VERSION ""

NS_ :

BS_:

BU_: ICC DVR PCL EAMP FLZCU_HCU_IC FLZCU_IC HCU_IC FLZCU_Signal_IC CGW TBOX BNCM CWC FRZCU

BO_ 1254 ICC_DK_7: 64 ICC
 SG_ ICC_WelcomeOpenSet : 1|2@0+ (1,0) [0|3] ""  FLZCU_HCU_IC,FLZCU_IC,BNCM
 SG_ ICC_WALOpenSet : 3|2@0+ (1,0) [0|3] ""  FLZCU_HCU_IC,FLZCU_IC,BNCM
 SG_ ICC_EasytrunkSet : 5|2@0+ (1,0) [0|3] ""  BNCM
 SG_ ICC_UIROpenSet : 7|2@0+ (1,0) [0|3] ""  FLZCU_HCU_IC,FLZCU_IC,BNCM
 SG_ ICC_BeanIDReq : 13|2@0+ (1,0) [0|3] ""  BNCM
 SG_ ICC_CWCWorkingStsSet : 15|2@0+ (1,0) [0|3] ""  CWC
 SG_ ICC_CWCPhoneforgottenFunStsSet : 17|2@0+ (1,0) [0|3] ""  CWC
 SG_ ICC_RCWCWorkingStsSet : 25|2@0+ (1,0) [0|3] "" Vector__XXX
 SG_ ICC_RCWCPhoneforgottenFunStsSet : 27|2@0+ (1,0) [0|3] "" Vector__XXX

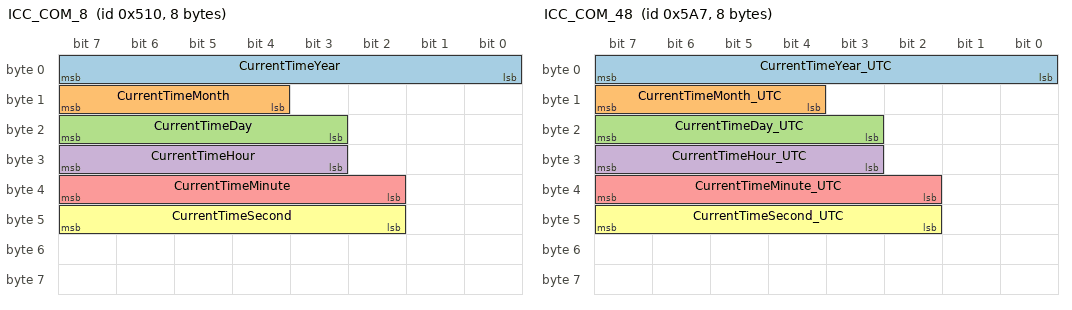
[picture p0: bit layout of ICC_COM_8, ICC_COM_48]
BO_ 1296 ICC_COM_8: 8 ICC
 SG_ CurrentTimeYear : 7|8@0+ (1,2000) [2000|2255] ""  DVR,FLZCU_HCU_IC,HCU_IC,BNCM
 SG_ CurrentTimeMonth : 15|4@0+ (1,0) [1|12] ""  DVR,FLZCU_HCU_IC,HCU_IC,BNCM
 SG_ CurrentTimeDay : 23|5@0+ (1,0) [1|31] ""  DVR,FLZCU_HCU_IC,HCU_IC,BNCM
 SG_ CurrentTimeHour : 31|5@0+ (1,0) [0|23] ""  DVR,FLZCU_HCU_IC,HCU_IC,BNCM
 SG_ CurrentTimeMinute : 39|6@0+ (1,0) [0|59] ""  DVR,FLZCU_HCU_IC,HCU_IC,BNCM
 SG_ CurrentTimeSecond : 47|6@0+ (1,0) [0|59] ""  DVR,FLZCU_HCU_IC,HCU_IC,BNCM

BO_ 1447 ICC_COM_48: 8 ICC
 SG_ CurrentTimeYear_UTC : 7|8@0+ (1,2000) [2000|2255] ""  FLZCU_HCU_IC,FLZCU_IC
 SG_ CurrentTimeMonth_UTC : 15|4@0+ (1,0) [1|12] ""  FLZCU_HCU_IC,FLZCU_IC
 SG_ CurrentTimeDay_UTC : 23|5@0+ (1,0) [1|31] ""  FLZCU_HCU_IC,FLZCU_IC
 SG_ CurrentTimeHour_UTC : 31|5@0+ (1,0) [0|23] ""  FLZCU_HCU_IC,FLZCU_IC
 SG_ CurrentTimeMinute_UTC : 39|6@0+ (1,0) [0|59] ""  FLZCU_HCU_IC,FLZCU_IC
 SG_ CurrentTimeSecond_UTC : 47|6@0+ (1,0) [0|59] ""  FLZCU_HCU_IC,FLZCU_IC

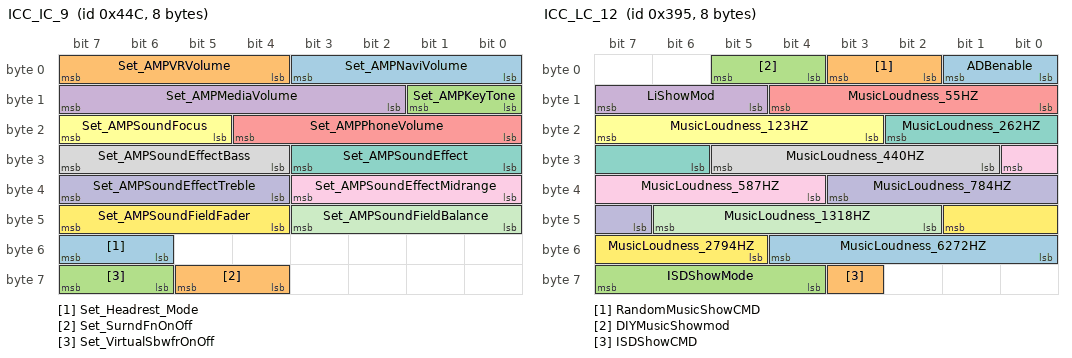
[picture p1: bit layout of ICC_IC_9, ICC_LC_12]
BO_ 1100 ICC_IC_9: 8 ICC
 SG_ Set_AMPNaviVolume : 3|4@0+ (1,0) [0|15] ""  EAMP
 SG_ Set_AMPVRVolume : 7|4@0+ (1,0) [0|15] ""  EAMP
 SG_ Set_AMPKeyTone : 9|2@0+ (1,0) [0|3] ""  EAMP
 SG_ Set_AMPMediaVolume : 15|6@0+ (1,0) [0|63] ""  EAMP
 SG_ Set_AMPPhoneVolume : 20|5@0+ (1,0) [0|31] ""  EAMP
 SG_ Set_AMPSoundFocus : 23|3@0+ (1,0) [0|7] ""  EAMP
 SG_ Set_AMPSoundEffect : 27|4@0+ (1,0) [0|15] ""  EAMP
 SG_ Set_AMPSoundEffectBass : 31|4@0+ (1,0) [0|15] ""  EAMP
 SG_ Set_AMPSoundEffectMidrange : 35|4@0+ (1,0) [0|15] ""  EAMP
 SG_ Set_AMPSoundEffectTreble : 39|4@0+ (1,0) [0|15] ""  EAMP
 SG_ Set_AMPSoundFieldBalance : 43|4@0+ (1,0) [0|15] ""  EAMP
 SG_ Set_AMPSoundFieldFader : 47|4@0+ (1,0) [0|15] ""  EAMP
 SG_ Set_Headrest_Mode : 55|2@0+ (1,0) [0|3] ""  EAMP
 SG_ Set_SurndFnOnOff : 61|2@0+ (1,0) [0|3] ""  EAMP
 SG_ Set_VirtualSbwfrOnOff : 63|2@0+ (1,0) [0|1] ""  EAMP

BO_ 1119 ICC_IC_10: 8 ICC
 SG_ Set_AMPMediaDuck : 1|2@0+ (1,0) [0|3] ""  EAMP
 SG_ Set_AMPSpeedVolume : 5|3@0+ (1,0) [0|7] ""  EAMP
 SG_ Set_AMPMute : 7|2@0+ (1,0) [0|3] ""  EAMP
 SG_ REQ_AMPA2BMediaSound : 9|2@0+ (1,0) [0|3] ""  EAMP
 SG_ REQ_AMPA2BNaviSound : 11|2@0+ (1,0) [0|3] ""  EAMP
 SG_ REQ_AMPA2BVRSound : 13|2@0+ (1,0) [0|3] ""  EAMP
 SG_ REQ_AMPA2BTTSSound : 15|2@0+ (1,0) [0|3] ""  EAMP
 SG_ REQ_AMPA2BKeyTone : 23|2@0+ (1,0) [0|3] ""  EAMP
 SG_ Set_AMPRestoreDefaults : 25|2@0+ (1,0) [0|3] ""  EAMP
 SG_ Set_AMPAlarmVolume : 29|4@0+ (1,0) [0|15] ""  EAMP
 SG_ REQ_AMPA2BPhoneSound : 31|2@0+ (1,0) [0|3] ""  EAMP
 SG_ Set_AMPSoundEffectMegaBass : 35|4@0+ (1,0) [0|15] ""  EAMP
 SG_ Set_AMPSoundEffectMidBass : 39|4@0+ (1,0) [0|15] ""  EAMP
 SG_ Set_AMPSoundEffectMidTreble : 43|4@0+ (1,0) [0|15] ""  EAMP
 SG_ Set_AMPBackgroundVolume : 53|6@0+ (1,0) [0|63] ""  EAMP
 SG_ Set_AMPSoundBypass : 45|2@0+ (1,0) [0|3] ""  EAMP
 SG_ Set_AMPA2BConfig : 47|2@0+ (1,0) [0|3] ""  EAMP

BO_ 1150 ICC_BD_11: 8 ICC
 SG_ Fusa_47E_3 : 28|1@0+ (1,0) [0|1] "" Vector__XXX
 SG_ Fusa_47E_2 : 23|4@0+ (1,0) [0|15] "" Vector__XXX
 SG_ Fusa_47E_1 : 15|2@0+ (1,0) [0|3] "" Vector__XXX
 SG_ ICC_BD_11_CRC : 7|8@0+ (1,0) [0|255] "" Vector__XXX
 SG_ ICC_BD_11_RollgCntr : 11|4@0+ (1,0) [0|14] "" Vector__XXX
 SG_ ICC_CPDDelaySwitchSet : 13|2@0+ (1,0) [0|3] "" Vector__XXX
 SG_ ICC_PPMIDBSRBPASet : 17|2@0+ (1,0) [0|3] "" Vector__XXX
 SG_ ICC_PPMIDHwSet : 19|2@0+ (1,0) [0|3] "" Vector__XXX
 SG_ ICC_DriveDrosinessLevel : 31|3@0+ (1,0) [0|7] "" Vector__XXX
 SG_ ICC_FLDoorButton : 25|2@0+ (1,0) [0|3] "" Vector__XXX
 SG_ ICC_FRDoorButton : 27|2@0+ (1,0) [0|3] "" Vector__XXX
 SG_ ICC_RRDoorButton : 33|2@0+ (1,0) [0|3] "" Vector__XXX
 SG_ ICC_RLDoorButton : 35|2@0+ (1,0) [0|3] "" Vector__XXX
 SG_ ICC_CloseAllDoors : 37|2@0+ (1,0) [0|3] "" Vector__XXX
 SG_ ICC_DoorRemoteKeyControlEnable : 39|2@0+ (1,0) [0|3] ""  FLZCU_HCU_IC
 SG_ ICC_SetOpenAngle : 41|2@0+ (1,0) [0|3] "" Vector__XXX
 SG_ ICC_CPDSwitchSet : 43|2@0+ (1,0) [0|3] "" Vector__XXX
 SG_ ICC_FrontDoorPowerMode : 45|2@0+ (1,0) [0|3] "" Vector__XXX
 SG_ ICC_RearDoorPowerMode : 47|2@0+ (1,0) [0|3] "" Vector__XXX
 SG_ ICC_PedalCloseDriverDoorEnable : 49|2@0+ (1,0) [0|3] "" Vector__XXX
 SG_ RR_Door_RearScreen_Control : 51|2@0+ (1,0) [0|3] "" Vector__XXX
 SG_ ICC_RearDoorVoiceControlEnable : 53|2@0+ (1,0) [0|3] "" Vector__XXX
 SG_ ICC_FLVoiceControl : 55|2@0+ (1,0) [0|3] "" Vector__XXX
 SG_ ICC_FRVoiceControl : 57|2@0+ (1,0) [0|3] "" Vector__XXX
 SG_ ICC_RRVoiceControl : 59|2@0+ (1,0) [0|3] "" Vector__XXX
 SG_ ICC_RLVoiceControl : 61|2@0+ (1,0) [0|3] "" Vector__XXX
 SG_ RL_Door_RearScreen_Control : 63|2@0+ (1,0) [0|3] "" Vector__XXX

BO_ 917 ICC_LC_12: 8 ICC
 SG_ ADBenable : 1|2@0+ (1,0) [0|3] "" Vector__XXX
 SG_ RandomMusicShowCMD : 3|2@0+ (1,0) [0|3] "" Vector__XXX
 SG_ DIYMusicShowmod : 5|2@0+ (1,0) [0|3] "" Vector__XXX
 SG_ LiShowMod : 15|3@0+ (1,0) [0|7] "" Vector__XXX
 SG_ MusicLoudness_55HZ : 12|5@0+ (1,0) [0|31] "" Vector__XXX
 SG_ MusicLoudness_123HZ : 23|5@0+ (1,0) [0|31] "" Vector__XXX
 SG_ MusicLoudness_262HZ : 18|5@0+ (1,0) [0|31] "" Vector__XXX
 SG_ MusicLoudness_440HZ : 29|5@0+ (1,0) [0|31] "" Vector__XXX
 SG_ MusicLoudness_587HZ : 24|5@0+ (1,0) [0|31] "" Vector__XXX
 SG_ MusicLoudness_784HZ : 35|5@0+ (1,0) [0|31] "" Vector__XXX
 SG_ MusicLoudness_1318HZ : 46|5@0+ (1,0) [0|31] "" Vector__XXX
 SG_ MusicLoudness_2794HZ : 41|5@0+ (1,0) [0|31] "" Vector__XXX
 SG_ MusicLoudness_6272HZ : 52|5@0+ (1,0) [0|31] "" Vector__XXX
 SG_ ISDShowCMD : 59|1@0+ (1,0) [0|1] "" Vector__XXX
 SG_ ISDShowMode : 63|4@0+ (1,0) [0|15] "" Vector__XXX

BO_ 1273 ICC_IC_14: 8 ICC
 SG_ FaceID : 29|3@0+ (1,0) [0|7] ""  FLZCU_HCU_IC,FLZCU_IC

BO_ 1157 ICC_DA_15: 8 ICC
 SG_ Fusa_485_2 : 55|16@0+ (1,0) [0|65535] "" Vector__XXX
 SG_ Fusa_485_1 : 31|3@0+ (1,0) [0|7] "" Vector__XXX
 SG_ ICC_DA_15_CRC : 7|8@0+ (1,0) [0|255] "" Vector__XXX
 SG_ ICC_DA_15_RollgCntr : 11|4@0+ (1,0) [0|14] "" Vector__XXX
 SG_ ICC_DA_15_Resd : 15|4@0+ (1,0) [0|15] "" Vector__XXX
 SG_ ICC_DA_15_BSDLCWSettingSt : 17|2@0+ (1,0) [0|3] "" Vector__XXX
 SG_ ICC_DA_15_DOWSettingSt : 19|2@0+ (1,0) [0|3] "" Vector__XXX
 SG_ ICC_DA_15_RCWSettingSt : 21|2@0+ (1,0) [0|3] "" Vector__XXX
 SG_ ICC_DA_15_RCTARCTBWarnType : 23|2@0+ (1,0) [0|3] "" Vector__XXX
 SG_ ICC_DA_15_FCTAFCTBWarnType : 25|2@0+ (1,0) [0|3] "" Vector__XXX
 SG_ ICC_DA_15_FrontPDCMuteSet : 26|1@0+ (1,0) [0|1] "" Vector__XXX
 SG_ ICC_DA_15_FKPMuteSet : 27|1@0+ (1,0) [0|1] "" Vector__XXX
 SG_ ICC_DA_15_ExtremeEnergySaveMode : 28|1@0+ (1,0) [0|1] "" Vector__XXX
 SG_ Driver_EyeOnRoad : 39|3@0+ (1,0) [0|7] "" Vector__XXX
 SG_ Dms_Status : 36|3@0+ (1,0) [0|7] "" Vector__XXX
 SG_ Driver_AbnormalBehavior : 33|2@0+ (1,0) [0|3] "" Vector__XXX
 SG_ Driver_GazeRegion : 47|4@0+ (1,0) [0|15] "" Vector__XXX
 SG_ Dms_DriverPresence : 43|2@0+ (1,0) [0|3] "" Vector__XXX
 SG_ ICC_IHCfunctionSw : 41|2@0+ (1,0) [0|3] "" Vector__XXX

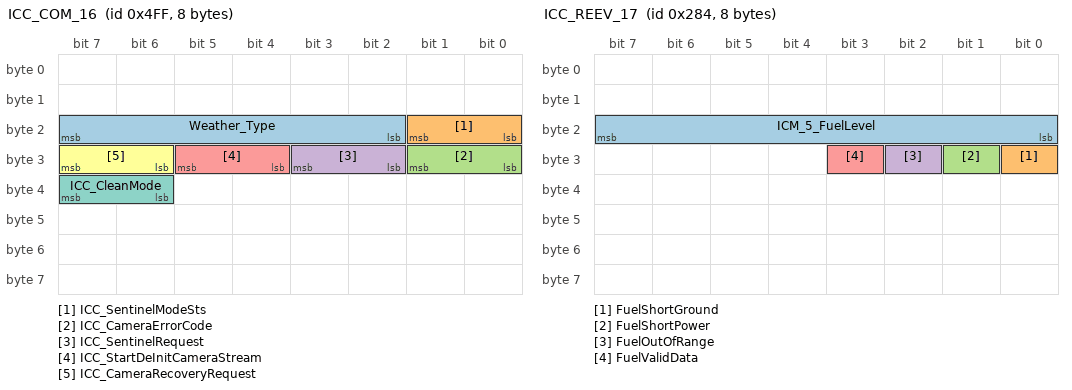
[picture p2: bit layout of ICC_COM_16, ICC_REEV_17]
BO_ 1279 ICC_COM_16: 8 ICC
 SG_ Weather_Type : 23|6@0+ (1,0) [0|63] "" Vector__XXX
 SG_ ICC_SentinelModeSts : 17|2@0+ (1,0) [0|3] "" Vector__XXX
 SG_ ICC_CameraErrorCode : 25|2@0+ (1,0) [0|3] "" Vector__XXX
 SG_ ICC_SentinelRequest : 27|2@0+ (1,0) [0|3] "" Vector__XXX
 SG_ ICC_StartDeInitCameraStream : 29|2@0+ (1,0) [0|3] "" Vector__XXX
 SG_ ICC_CameraRecoveryRequest : 31|2@0+ (1,0) [0|3] "" Vector__XXX
 SG_ ICC_CleanMode : 39|2@0+ (1,0) [0|3] "" Vector__XXX

BO_ 644 ICC_REEV_17: 8 ICC
 SG_ ICM_5_FuelLevel : 23|8@0+ (1,0) [0|100] "%"  FLZCU_HCU_IC,HCU_IC,TBOX
 SG_ FuelShortGround : 24|1@0+ (1,0) [0|1] ""  FLZCU_HCU_IC
 SG_ FuelShortPower : 25|1@0+ (1,0) [0|1] ""  FLZCU_HCU_IC
 SG_ FuelOutOfRange : 26|1@0+ (1,0) [0|1] ""  FLZCU_HCU_IC
 SG_ FuelValidData : 27|1@0+ (1,0) [0|1] ""  FLZCU_HCU_IC

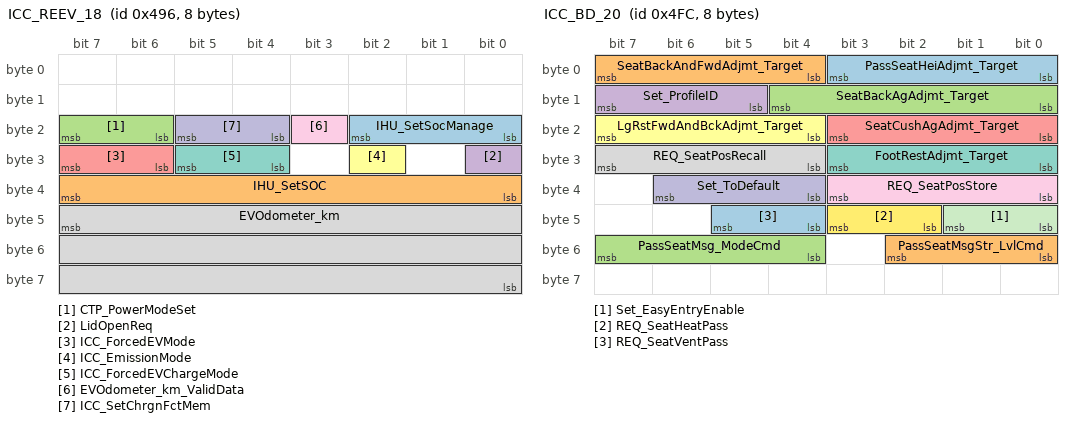
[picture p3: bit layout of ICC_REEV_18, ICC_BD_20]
BO_ 1174 ICC_REEV_18: 8 ICC
 SG_ IHU_SetSocManage : 18|3@0+ (1,0) [0|7] ""  FLZCU_HCU_IC
 SG_ IHU_SetSOC : 39|8@0+ (1,0) [0|100] "%"  FLZCU_HCU_IC,HCU_IC
 SG_ CTP_PowerModeSet : 23|2@0+ (1,0) [0|3] ""  FLZCU_HCU_IC,HCU_IC
 SG_ LidOpenReq : 24|1@0+ (1,0) [0|1] "" Vector__XXX
 SG_ ICC_ForcedEVMode : 31|2@0+ (1,0) [0|3] ""  FLZCU_HCU_IC
 SG_ ICC_EmissionMode : 26|1@0+ (1,0) [0|1] ""  FLZCU_HCU_IC,HCU_IC
 SG_ ICC_ForcedEVChargeMode : 29|2@0+ (1,0) [0|3] ""  FLZCU_HCU_IC
 SG_ EVOdometer_km : 47|24@0+ (0.1,0) [0|999999.9] "km"  FLZCU_HCU_IC
 SG_ EVOdometer_km_ValidData : 19|1@0+ (1,0) [0|1] ""  FLZCU_HCU_IC
 SG_ ICC_SetChrgnFctMem : 21|2@0+ (1,0) [0|3] ""  FLZCU_HCU_IC,HCU_IC

BO_ 1242 ICC_DK_19: 32 ICC
 SG_ ICC_DK_19_CRC1 : 7|8@0+ (1,0) [0|255] ""  BNCM
 SG_ ICC_DK_19_RollgCntr1 : 11|4@0+ (1,0) [0|14] ""  BNCM
 SG_ ICC_DK_19_Resd1 : 15|4@0+ (1,0) [0|15] ""  BNCM
 SG_ ICC_DK_19_CMD : 23|16@0+ (1,0) [0|65535] ""  BNCM
 SG_ ICC_DK_19_PDU1 : 39|64@0+ (1,0) [0|1.84467440737096E+019] ""  BNCM
 SG_ ICC_DK_19_PDU2 : 103|64@0+ (1,0) [0|1.84467440737096E+019] ""  BNCM
 SG_ ICC_DK_19_PDU3 : 167|64@0+ (1,0) [0|1.84467440737096E+019] ""  BNCM
 SG_ ICC_DK_19_PDU4 : 231|32@0+ (1,0) [0|4294967295] ""  BNCM

BO_ 1276 ICC_BD_20: 8 ICC
 SG_ PassSeatHeiAdjmt_Target : 3|4@0+ (1,0) [0|15] "" Vector__XXX
 SG_ SeatBackAndFwdAdjmt_Target : 7|4@0+ (1,0) [0|15] "" Vector__XXX
 SG_ SeatBackAgAdjmt_Target : 12|5@0+ (1,0) [0|31] "" Vector__XXX
 SG_ Set_ProfileID : 15|3@0+ (1,0) [0|7] "" Vector__XXX
 SG_ SeatCushAgAdjmt_Target : 19|4@0+ (1,0) [0|15] "" Vector__XXX
 SG_ LgRstFwdAndBckAdjmt_Target : 23|4@0+ (1,0) [0|15] "" Vector__XXX
 SG_ FootRestAdjmt_Target : 27|4@0+ (1,0) [0|15] "" Vector__XXX
 SG_ REQ_SeatPosRecall : 31|4@0+ (1,0) [0|15] "" Vector__XXX
 SG_ REQ_SeatPosStore : 35|4@0+ (1,0) [0|15] "" Vector__XXX
 SG_ Set_ToDefault : 38|3@0+ (1,0) [0|7] "" Vector__XXX
 SG_ Set_EasyEntryEnable : 41|2@0+ (1,0) [0|3] "" Vector__XXX
 SG_ REQ_SeatHeatPass : 43|2@0+ (1,0) [0|3] "" Vector__XXX
 SG_ REQ_SeatVentPass : 45|2@0+ (1,0) [0|3] "" Vector__XXX
 SG_ PassSeatMsgStr_LvlCmd : 50|3@0+ (1,0) [0|7] "" Vector__XXX
 SG_ PassSeatMsg_ModeCmd : 55|4@0+ (1,0) [0|15] "" Vector__XXX

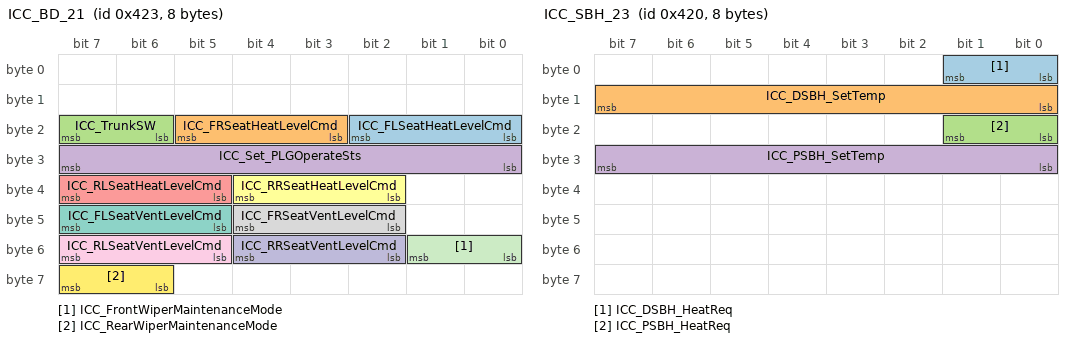
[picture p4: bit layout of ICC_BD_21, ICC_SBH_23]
BO_ 1059 ICC_BD_21: 8 ICC
 SG_ ICC_FLSeatHeatLevelCmd : 18|3@0+ (1,0) [0|7] ""  FLZCU_HCU_IC,FLZCU_IC
 SG_ ICC_FRSeatHeatLevelCmd : 21|3@0+ (1,0) [0|7] ""  FRZCU
 SG_ ICC_TrunkSW : 23|2@0+ (1,0) [0|3] "" Vector__XXX
 SG_ ICC_Set_PLGOperateSts : 31|8@0+ (1,-1) [-1|100] "%" Vector__XXX
 SG_ ICC_RLSeatHeatLevelCmd : 39|3@0+ (1,0) [0|7] ""  FLZCU_HCU_IC,FLZCU_IC
 SG_ ICC_RRSeatHeatLevelCmd : 36|3@0+ (1,0) [0|7] ""  FRZCU
 SG_ ICC_FLSeatVentLevelCmd : 47|3@0+ (1,0) [0|7] ""  FLZCU_HCU_IC,FLZCU_IC
 SG_ ICC_FRSeatVentLevelCmd : 44|3@0+ (1,0) [0|7] ""  FRZCU
 SG_ ICC_RLSeatVentLevelCmd : 55|3@0+ (1,0) [0|7] ""  FLZCU_HCU_IC,FLZCU_IC
 SG_ ICC_RRSeatVentLevelCmd : 52|3@0+ (1,0) [0|7] ""  FRZCU
 SG_ ICC_FrontWiperMaintenanceMode : 49|2@0+ (1,0) [0|3] ""  FLZCU_HCU_IC,FLZCU_IC
 SG_ ICC_RearWiperMaintenanceMode : 63|2@0+ (1,0) [0|3] ""  FLZCU_HCU_IC,FLZCU_IC

BO_ 1105 ICC_MFS_22: 8 ICC
 SG_ ICC_MultiplexSignalStatusSet : 12|3@0+ (1,0) [0|7] "" Vector__XXX

BO_ 1056 ICC_SBH_23: 8 ICC
 SG_ ICC_DSBH_HeatReq : 1|2@0+ (1,0) [0|3] "" Vector__XXX
 SG_ ICC_DSBH_SetTemp : 15|8@0+ (1,0) [30|65] "°C" Vector__XXX
 SG_ ICC_PSBH_HeatReq : 17|2@0+ (1,0) [0|3] "" Vector__XXX
 SG_ ICC_PSBH_SetTemp : 31|8@0+ (1,0) [30|65] "°C" Vector__XXX

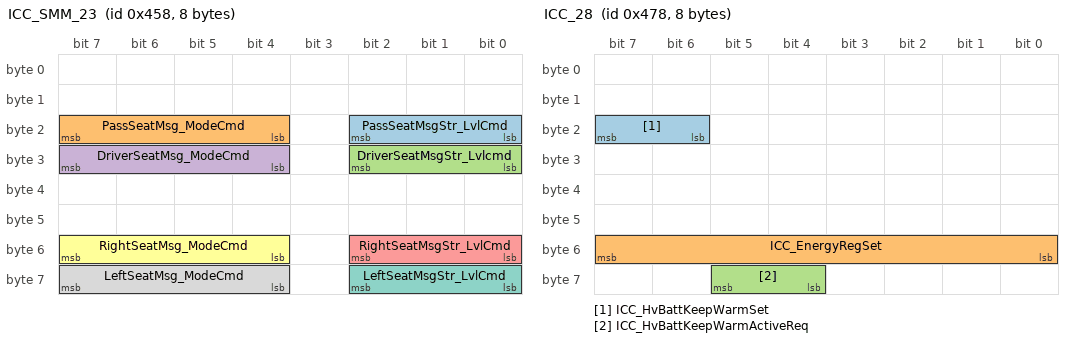
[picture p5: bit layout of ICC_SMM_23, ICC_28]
BO_ 1112 ICC_SMM_23: 8 ICC
 SG_ PassSeatMsgStr_LvlCmd : 18|3@0+ (1,0) [0|7] ""  FLZCU_HCU_IC,FLZCU_IC
 SG_ PassSeatMsg_ModeCmd : 23|4@0+ (1,0) [0|15] ""  FLZCU_HCU_IC,FLZCU_IC
 SG_ DriverSeatMsgStr_Lvlcmd : 26|3@0+ (1,0) [0|7] ""  FLZCU_HCU_IC,FLZCU_IC
 SG_ DriverSeatMsg_ModeCmd : 31|4@0+ (1,0) [0|15] ""  FLZCU_HCU_IC,FLZCU_IC
 SG_ RightSeatMsgStr_LvlCmd : 50|3@0+ (1,0) [0|7] ""  FLZCU_HCU_IC,FLZCU_IC
 SG_ RightSeatMsg_ModeCmd : 55|4@0+ (1,0) [0|15] ""  FLZCU_HCU_IC,FLZCU_IC
 SG_ LeftSeatMsgStr_LvlCmd : 58|3@0+ (1,0) [0|7] ""  FLZCU_HCU_IC,FLZCU_IC
 SG_ LeftSeatMsg_ModeCmd : 63|4@0+ (1,0) [0|15] ""  FLZCU_HCU_IC,FLZCU_IC

BO_ 1265 ICC_ZCU_25: 24 ICC
 SG_ ICC_PwrOff : 18|1@0+ (1,0) [0|1] ""  FLZCU_HCU_IC
 SG_ ICC_EtmEgySave : 20|1@0+ (1,0) [0|1] ""  FLZCU_HCU_IC
 SG_ ICC_HoodSW : 23|2@0+ (1,0) [0|3] ""  FLZCU_HCU_IC
 SG_ ICC_GloveboxSW : 25|2@0+ (1,0) [0|3] ""  FLZCU_HCU_IC
 SG_ ICC_ChrgPortCover_Switch : 27|2@0+ (1,0) [0|3] ""  FLZCU_HCU_IC
 SG_ ICC_ReWinDefrstSwt : 29|2@0+ (1,0) [0|3] ""  FLZCU_HCU_IC,FLZCU_IC
 SG_ ICC_RearMirrorFoldCmd : 31|2@0+ (1,0) [0|3] ""  FLZCU_HCU_IC,FLZCU_IC
 SG_ ICC_CenterLockSwt : 33|2@0+ (1,0) [0|3] ""  FLZCU_HCU_IC,FLZCU_IC
 SG_ ICC_ReverseExtMirrorSts : 36|3@0+ (1,0) [0|7] ""  FLZCU_HCU_IC,FLZCU_IC
 SG_ ICC_LightMainSwitchSts : 39|3@0+ (1,0) [0|7] ""  FLZCU_HCU_IC
 SG_ ICC_AutoFoldSts : 41|2@0+ (1,0) [0|3] ""  FLZCU_HCU_IC,FLZCU_IC
 SG_ ICC_HeadlampHeightSts : 44|3@0+ (1,0) [0|7] ""  FLZCU_HCU_IC,FLZCU_IC
 SG_ ICC_WiprSnvty : 47|3@0+ (1,0) [0|7] ""  FLZCU_HCU_IC,FLZCU_IC
 SG_ ICC_WindowCmd : 52|5@0+ (1,0) [0|31] ""  FLZCU_HCU_IC,FLZCU_IC
 SG_ ICC_LowBeamDelayOff : 55|3@0+ (1,0) [0|7] ""  FLZCU_HCU_IC,FLZCU_IC
 SG_ ICC_FLWinCmd : 62|7@0+ (1,-1) [-1|100] "%"  FLZCU_HCU_IC,FLZCU_IC
 SG_ ICC_FRWinCmd : 86|7@0+ (1,-1) [-1|100] "%"  FLZCU_HCU_IC,FLZCU_IC
 SG_ ICC_RLWinCmd : 94|7@0+ (1,-1) [-1|100] "%"  FLZCU_HCU_IC,FLZCU_IC
 SG_ ICC_RRWinCmd : 102|7@0+ (1,-1) [-1|100] "%"  FLZCU_HCU_IC,FLZCU_IC
 SG_ ICC_FGHeatSts : 105|2@0+ (1,0) [0|3] ""  FLZCU_HCU_IC,FLZCU_IC
 SG_ ICC_AutolockSts : 107|2@0+ (1,0) [0|3] ""  FLZCU_HCU_IC,FLZCU_IC
 SG_ ICC_WiperID : 109|2@0+ (1,0) [0|3] ""  FLZCU_HCU_IC
 SG_ ICC_MaintenanceMode : 111|2@0+ (1,0) [0|3] ""  FLZCU_HCU_IC
 SG_ ICC_lockSetSwitchSts : 113|2@0+ (1,0) [0|3] ""  FLZCU_HCU_IC
 SG_ ICC_ChildLockSW : 115|2@0+ (1,0) [0|3] ""  FLZCU_HCU_IC
 SG_ ICC_ParkUnlockEnable : 117|2@0+ (1,0) [0|3] ""  FLZCU_HCU_IC,FLZCU_IC
 SG_ ICC_BLEOpenDriverDoorEnable : 119|2@0+ (1,0) [0|3] ""  FLZCU_HCU_IC,FLZCU_IC
 SG_ ICC_WinInhbSwt : 121|2@0+ (1,0) [0|3] ""  FLZCU_HCU_IC
 SG_ ICC_SteerWhlHeatgSwt : 124|3@0+ (1,0) [0|7] ""  FLZCU_HCU_IC,FLZCU_IC
 SG_ ICC_AutoHeatingset : 127|2@0+ (1,0) [0|3] ""  FLZCU_HCU_IC
 SG_ ICC_FrontFogSw : 145|2@0+ (1,0) [0|3] ""  FLZCU_HCU_IC
 SG_ ICC_RearFogSw : 147|2@0+ (1,0) [0|3] ""  FLZCU_HCU_IC
 SG_ ICC_DoorControlSW : 149|2@0+ (1,0) [0|3] ""  FLZCU_HCU_IC
 SG_ ICC_LockCarWinCloseSw : 151|2@0+ (1,0) [0|3] ""  FLZCU_HCU_IC,FLZCU_IC
 SG_ ICC_RainCarWinCloseSw : 159|2@0+ (1,0) [0|3] ""  FLZCU_HCU_IC
 SG_ ICC_EasyEntryExitSet : 157|2@0+ (1,0) [0|3] ""  FLZCU_HCU_IC,FLZCU_IC
 SG_ ICC_NapTimeSet : 166|6@0+ (1,-1) [-1|60] "min"  FLZCU_HCU_IC,FLZCU_IC
 SG_ ICC_NapAreaSet : 155|2@0+ (1,0) [0|3] ""  FLZCU_HCU_IC,FLZCU_IC
 SG_ ICC_NapStatusSet : 153|2@0+ (1,0) [0|3] ""  FLZCU_HCU_IC,FLZCU_IC
 SG_ ICC_NapCFSStatusSet : 175|2@0+ (1,0) [0|3] ""  FLZCU_HCU_IC,FRZCU
 SG_ ICC_NapSetTemperature : 173|5@0+ (0.5,15.5) [15.5|30.5] "℃"  FLZCU_HCU_IC,FRZCU
 SG_ ICC_SpoilerWelcomeFunSet : 183|2@0+ (1,0) [0|3] ""  FLZCU_HCU_IC
 SG_ ICC_SpoilerCtrlCmd : 181|3@0+ (1,0) [0|7] ""  FLZCU_HCU_IC
 SG_ ICC_HazardLightReq : 177|2@0+ (1,0) [0|3] ""  FLZCU_HCU_IC
 SG_ ICC_MusicStatus : 187|2@0+ (1,0) [0|3] ""  FLZCU_HCU_IC,FLZCU_IC
 SG_ ICC_CinemaStatus : 185|2@0+ (1,0) [0|3] ""  PCL,FLZCU_HCU_IC,FLZCU_IC,HCU_IC

BO_ 1137 ICC_TBOX_27: 32 ICC
 SG_ ICC_BookChrgSetReq : 23|2@0+ (1,0) [0|3] ""  FLZCU_HCU_IC,HCU_IC,TBOX
 SG_ ICC_BkChrgStartTimeYear : 31|16@0+ (1,1900) [1900|9999] "年"  FLZCU_HCU_IC,HCU_IC,TBOX
 SG_ ICC_BkChrgStartTimeDay : 47|5@0+ (1,0) [1|31] "日"  FLZCU_HCU_IC,HCU_IC,TBOX
 SG_ ICC_BkChrgStartTimeHour : 55|5@0+ (1,0) [0|23] "小时"  FLZCU_HCU_IC,HCU_IC,TBOX
 SG_ ICC_BkChrgStartTimemMin : 63|6@0+ (1,0) [0|59] "分钟"  FLZCU_HCU_IC,HCU_IC,TBOX
 SG_ ICC_BkChrgStartTimeMonth : 87|4@0+ (1,0) [1|12] "月"  FLZCU_HCU_IC,HCU_IC,TBOX
 SG_ ICC_BkChrgDuration : 83|11@0+ (1,0) [0|1440] "min"  FLZCU_HCU_IC,HCU_IC,TBOX
 SG_ ICC_BkChrgCycleType : 103|3@0+ (1,0) [0|7] ""  FLZCU_HCU_IC,HCU_IC,TBOX
 SG_ ICC_StopChrgReq : 100|2@0+ (1,0) [0|3] ""  FLZCU_HCU_IC,HCU_IC,TBOX
 SG_ ICC_BkChrgCycleMon : 98|2@0+ (1,0) [0|3] ""  FLZCU_HCU_IC,HCU_IC,TBOX
 SG_ ICC_BkChrgCycleTues : 111|2@0+ (1,0) [0|3] ""  FLZCU_HCU_IC,HCU_IC,TBOX
 SG_ ICC_BkChrgCycleWen : 109|2@0+ (1,0) [0|3] ""  FLZCU_HCU_IC,HCU_IC,TBOX
 SG_ ICC_BkChrgCycleThur : 107|2@0+ (1,0) [0|3] ""  FLZCU_HCU_IC,HCU_IC,TBOX
 SG_ ICC_BkChrgCycleFri : 105|2@0+ (1,0) [0|3] ""  FLZCU_HCU_IC,HCU_IC,TBOX
 SG_ ICC_BkChrgCycleSat : 119|2@0+ (1,0) [0|3] ""  FLZCU_HCU_IC,HCU_IC,TBOX
 SG_ ICC_BkChrgCycleSun : 117|2@0+ (1,0) [0|3] ""  FLZCU_HCU_IC,HCU_IC,TBOX
 SG_ ICC_KeepWarmStrt : 124|5@0+ (1,0) [1|31] "日"  FLZCU_HCU_IC,HCU_IC,TBOX
 SG_ ICC_KeepWarmStrtHour : 148|5@0+ (1,0) [0|23] "小时"  FLZCU_HCU_IC,HCU_IC,TBOX
 SG_ ICC_KeepWarmStrtMin : 157|6@0+ (1,0) [0|59] "分钟"  FLZCU_HCU_IC,HCU_IC,TBOX
 SG_ ICC_PetmodeFb : 159|2@0+ (1,0) [0|3] ""  FLZCU_HCU_IC,HCU_IC,TBOX
 SG_ ICC_SentinelModeSwitchSts : 167|2@0+ (1,0) [0|3] ""  FLZCU_HCU_IC,HCU_IC,TBOX
 SG_ ICC_SentinelModeWorkingSts : 165|3@0+ (1,0) [0|7] ""  FLZCU_HCU_IC,HCU_IC,TBOX
 SG_ ICC_SentinelModeFaultSts : 161|2@0+ (1,0) [0|3] ""  FLZCU_HCU_IC,HCU_IC,TBOX
 SG_ ICC_SentinelModeAlarmSts : 175|2@0+ (1,0) [0|3] ""  FLZCU_HCU_IC,HCU_IC,TBOX
 SG_ ICC_SentinelModeExitReason : 173|3@0+ (1,0) [0|7] ""  FLZCU_HCU_IC,HCU_IC,TBOX
 SG_ ICC_PetModeWarn : 170|3@0+ (1,0) [0|7] ""  FLZCU_HCU_IC
 SG_ ICC_TBOXPetmodeReq : 178|2@0+ (1,0) [0|3] ""  FLZCU_HCU_IC,TBOX
 SG_ ICC_PetModeWarn_2 : 183|5@0+ (1,0) [0|31] ""  FLZCU_HCU_IC,HCU_IC,TBOX
 SG_ ICM_FuelLevel : 215|8@0+ (1,0) [0|255] "L"  FLZCU_HCU_IC,HCU_IC,TBOX,BNCM
 SG_ ICM_AverageVehicleSpeed : 223|8@0+ (1,0) [0|255] "Km/h"  FLZCU_HCU_IC,HCU_IC,TBOX
 SG_ ICM_DistenceToEmpty_Km : 231|11@0+ (1,0) [0|2047] "km"  FLZCU_HCU_IC,HCU_IC,TBOX
 SG_ ICM_FuelLevelFailSts : 235|1@0+ (1,0) [0|1] ""  FLZCU_HCU_IC,HCU_IC,TBOX
 SG_ ICM_Maintenance_tips : 234|1@0+ (1,0) [0|1] ""  FLZCU_HCU_IC,HCU_IC,TBOX
 SG_ ICM_SumTrip : 247|14@0+ (1,0) [0|16383] "km"  FLZCU_HCU_IC,HCU_IC,TBOX

BO_ 1144 ICC_28: 8 ICC
 SG_ ICC_HvBattKeepWarmSet : 23|2@0+ (1,0) [0|3] ""  FLZCU_HCU_IC,HCU_IC,TBOX
 SG_ ICC_EnergyRegSet : 55|8@0+ (1,-1) [-1|100] "%"  FLZCU_HCU_IC
 SG_ ICC_HvBattKeepWarmActiveReq : 61|2@0+ (1,0) [0|3] ""  FLZCU_HCU_IC,HCU_IC,TBOX

BO_ 1210 ICC_ZCU_29: 32 ICC
 SG_ ICC_FLSeatHeiCmd : 23|2@0+ (1,0) [0|3] ""  FLZCU_HCU_IC
 SG_ ICC_FLSeatLvlCmd : 21|2@0+ (1,0) [0|3] ""  FLZCU_HCU_IC
 SG_ ICC_FLSeatBackAgCmd : 19|2@0+ (1,0) [0|3] ""  FLZCU_HCU_IC
 SG_ ICC_FLSeatCushCmd : 17|2@0+ (1,0) [0|3] ""  FLZCU_HCU_IC
 SG_ ICC_FLSeatLegSpprtCmd : 31|2@0+ (1,0) [0|3] ""  FLZCU_HCU_IC
 SG_ ICC_FRSeatHeiCmd : 29|2@0+ (1,0) [0|3] ""  FLZCU_HCU_IC
 SG_ ICC_FRSeatLvlCmd : 27|2@0+ (1,0) [0|3] ""  FLZCU_HCU_IC
 SG_ ICC_FRSeatBackAgCmd : 25|2@0+ (1,0) [0|3] ""  FLZCU_HCU_IC
 SG_ ICC_FRSeatLegSpprtCmd : 39|2@0+ (1,0) [0|3] ""  FLZCU_HCU_IC
 SG_ ICC_MemoryRecoveryCmd : 37|2@0+ (1,0) [0|3] ""  FLZCU_HCU_IC,FLZCU_IC
 SG_ ICC_DeleteFaceID : 35|3@0+ (1,0) [0|7] ""  FLZCU_HCU_IC,FLZCU_IC
 SG_ ICC_FLSeatHeitargetCmd : 47|7@0+ (1,-1) [-1|100] "%"  FLZCU_HCU_IC
 SG_ ICC_FLSeatLvltargetCmd : 55|7@0+ (1,-1) [-1|100] "%"  FLZCU_HCU_IC
 SG_ ICC_FLSeatBackAgtargetCmd : 63|7@0+ (1,-1) [-1|100] "%"  FLZCU_HCU_IC
 SG_ ICC_FLSeatCushtargetCmd : 87|7@0+ (1,-1) [-1|100] "%"  FLZCU_HCU_IC
 SG_ ICC_FLSeatLegSpprttargetCmd : 95|7@0+ (1,-1) [-1|100] "%"  FLZCU_HCU_IC
 SG_ ICC_FRSeatHeitargetCmd : 103|7@0+ (1,-1) [-1|100] "%"  FLZCU_HCU_IC
 SG_ ICC_FRSeatLvltargetCmd : 111|7@0+ (1,-1) [-1|100] "%"  FLZCU_HCU_IC
 SG_ ICC_FRSeatBackAgtargetCmd : 119|7@0+ (1,-1) [-1|100] "%"  FLZCU_HCU_IC
 SG_ ICC_FRSeatLegSpprttargetCmd : 127|7@0+ (1,-1) [-1|100] "%"  FLZCU_HCU_IC
 SG_ ICC_NapFLSeatBackAgtargetSet : 151|7@0+ (1,-1) [-1|100] "%"  FLZCU_HCU_IC,FLZCU_IC
 SG_ ICC_NapFRSeatBackAgtargetSet : 159|7@0+ (1,-1) [-1|100] "%"  FLZCU_HCU_IC,FLZCU_IC
 SG_ ICC_NapFLSeatLvltargetSet : 167|7@0+ (1,-1) [-1|100] "%"  FLZCU_HCU_IC,FLZCU_IC
 SG_ ICC_NapFRSeatLvltargetSet : 175|7@0+ (1,-1) [-1|100] "%"  FLZCU_HCU_IC,FLZCU_IC
 SG_ ICC_FRSeatLegRestAngleCmd : 183|2@0+ (1,0) [0|3] ""  FLZCU_HCU_IC
 SG_ ICC_FRSeatLegRestAngletargetCmd : 190|7@0+ (1,-1) [-1|100] "%"  FLZCU_HCU_IC
 SG_ ICC_FRSeatCushCmd : 181|2@0+ (1,0) [0|3] ""  FLZCU_HCU_IC
 SG_ ICC_FRSeatCushtargetCmd : 214|7@0+ (1,-1) [-1|100] "%"  FLZCU_HCU_IC
 SG_ ICC_FRZeroGravitySeatSw : 179|2@0+ (1,0) [0|3] ""  FLZCU_HCU_IC
 SG_ ICC_HomeLinkArmHornSet : 223|2@0+ (1,0) [0|3] ""  FLZCU_HCU_IC
 SG_ ICC_HomeLinkWelLightSet : 221|2@0+ (1,0) [0|3] ""  FLZCU_HCU_IC
 SG_ ICC_HomeLinkPositionSts : 219|2@0+ (1,0) [0|3] ""  FLZCU_HCU_IC
 SG_ ICC_WelcomeOpenSetCmd : 217|2@0+ (1,0) [0|3] ""  FLZCU_HCU_IC,FLZCU_IC
 SG_ ICC_WALOpenSetCmd : 231|2@0+ (1,0) [0|3] ""  FLZCU_HCU_IC,FLZCU_IC
 SG_ ICC_UIROpenSetCmd : 229|2@0+ (1,0) [0|3] ""  FLZCU_HCU_IC,FLZCU_IC
 SG_ ICC_EnjoyableSeatSwitch : 227|2@0+ (1,0) [0|3] ""  FLZCU_HCU_IC,FLZCU_IC
 SG_ ICC_BLTKeyPESet : 225|2@0+ (1,0) [0|3] ""  FLZCU_HCU_IC,FLZCU_IC
 SG_ ICC_FRMemoryDeleteCmd : 241|2@0+ (1,0) [0|3] ""  FLZCU_HCU_IC
 SG_ ICC_FLSitPosnlocation : 233|2@0+ (1,0) [0|3] ""  FLZCU_HCU_IC,FLZCU_IC
 SG_ ICC_FRSitPosnlocation : 235|2@0+ (1,0) [0|3] ""  FLZCU_HCU_IC
 SG_ ICC_FREasyEntryExitSet : 237|2@0+ (1,0) [0|3] ""  FLZCU_HCU_IC
 SG_ ICC_FRMemoryRecoveryCmd : 239|2@0+ (1,0) [0|3] ""  FLZCU_HCU_IC
 SG_ ICC_ConsoleAdjustSwitch : 245|4@0+ (1,0) [0|15] ""  FLZCU_HCU_IC

BO_ 1399 ICC_TBOX_31: 32 ICC
 SG_ ICC_CLTC_RangeAval : 1|10@0+ (1,0) [0|1022] "KM"  TBOX
 SG_ ICC_DynamicRangeAval : 17|10@0+ (1,0) [0|1022] "KM"  TBOX
 SG_ ICC_WLTC_RangeAval : 33|10@0+ (1,0) [0|1022] "KM"  TBOX
 SG_ ICC_CLTC_RangeAvalFuel : 51|12@0+ (1,0) [0|2000] "KM"  TBOX
 SG_ ICC_WLTC_RangeAvalFuel : 67|12@0+ (1,0) [0|2000] "KM"  TBOX
 SG_ ICC_DynamicRangeAvalFuel : 83|12@0+ (1,0) [0|2000] "KM"  TBOX
 SG_ ICC_CLTC_RangeAvalComp : 99|12@0+ (1,0) [0|2000] "KM"  TBOX
 SG_ ICC_WLTC_RangeAvalComp : 115|12@0+ (1,0) [0|2000] "KM"  TBOX
 SG_ ICC_DynamicRangeAvalComp : 131|12@0+ (1,0) [0|2000] "KM"  TBOX
 SG_ ICC_Conditiontype : 151|2@0+ (1,0) [0|3] ""  TBOX

BO_ 1238 ICC_TMS_32: 32 ICC
 SG_ ICC_CFSSwitch : 17|2@0+ (1,0) [0|3] "" Vector__XXX
 SG_ ICC_CFSLevelSet : 20|3@0+ (1,0) [0|7] "" Vector__XXX
 SG_ ICC_CFSPosSet : 23|2@0+ (1,0) [0|3] "" Vector__XXX
 SG_ ICC_PM25Switch : 25|2@0+ (1,0) [0|3] "" Vector__XXX
 SG_ ICC_AQSSwitch : 27|2@0+ (1,0) [0|3] "" Vector__XXX
 SG_ ICC_SecSetTemp_C : 36|5@0+ (0.5,15.5) [15.5|30.5] "℃" Vector__XXX
 SG_ ICC_SecFaceKeySts : 39|2@0+ (1,0) [0|3] "" Vector__XXX
 SG_ ICC_SecFootKeySts : 41|2@0+ (1,0) [0|3] "" Vector__XXX
 SG_ ICC_SecBlowSpeedLevelKeySts : 45|4@0+ (1,0) [0|15] "" Vector__XXX
 SG_ ICC_SecAutoSwitch : 47|2@0+ (1,0) [0|3] "" Vector__XXX
 SG_ ICC_SecCLMSwitch : 49|2@0+ (1,0) [0|3] "" Vector__XXX
 SG_ ICC_ThrSetTemp_C : 54|5@0+ (0.5,15.5) [15.5|30.5] "℃" Vector__XXX
 SG_ ICC_ThrFaceKeySts : 57|2@0+ (1,0) [0|3] "" Vector__XXX
 SG_ ICC_ThrFootKeySts : 59|2@0+ (1,0) [0|3] "" Vector__XXX
 SG_ ICC_ThrBlowSpeedLevelKeySts : 63|4@0+ (1,0) [0|15] "" Vector__XXX
 SG_ ICC_ThrAutoSwitch : 81|2@0+ (1,0) [0|3] "" Vector__XXX
 SG_ ICC_ThrCLMSwitch : 83|2@0+ (1,0) [0|3] "" Vector__XXX
 SG_ ICC_ThrACRequestKeySts : 85|2@0+ (1,0) [0|3] "" Vector__XXX
 SG_ ICC_DFMSwitch : 87|2@0+ (1,0) [0|3] "" Vector__XXX

BO_ 1289 ICC_34: 32 ICC
 SG_ ICC_TirePressureDisplayUnit : 23|2@0+ (1,0) [0|3] ""  TBOX
 SG_ ICC_TireTemperatureDisplayUnit : 21|2@0+ (1,0) [0|3] ""  TBOX
 SG_ ICC_ToggleUnits : 19|2@0+ (1,0) [0|3] ""  TBOX
 SG_ ICC_BtConFlag : 28|3@0+ (1,0) [0|7] ""  TBOX
 SG_ ICC_GPSSwitchSet : 25|2@0+ (1,0) [0|3] ""  TBOX

BO_ 1167 ICC_35: 32 ICC
 SG_ ICC_KeyDriveModememory : 17|2@0+ (1,0) [0|3] ""  FLZCU_HCU_IC,HCU_IC
 SG_ ICC_DriveModeSet : 22|5@0+ (1,0) [0|31] ""  FLZCU_HCU_IC,HCU_IC
 SG_ ICC_DRIFTModeSetReq : 25|2@0+ (1,0) [0|3] ""  FLZCU_HCU_IC,HCU_IC
 SG_ ICC_EXPERTEIPBESPSet : 27|2@0+ (1,0) [0|3] ""  FLZCU_HCU_IC,HCU_IC
 SG_ ICC_EXPERTEcoSet : 29|2@0+ (1,0) [0|3] ""  FLZCU_HCU_IC,HCU_IC
 SG_ ICC_EXPERTNormSet : 31|2@0+ (1,0) [0|3] ""  FLZCU_HCU_IC,HCU_IC
 SG_ ICC_EXPERTSportSet : 33|2@0+ (1,0) [0|3] ""  FLZCU_HCU_IC,HCU_IC
 SG_ ICC_CrossaxisSet : 35|2@0+ (1,0) [0|3] ""  FLZCU_HCU_IC,HCU_IC
 SG_ ICC_EXPERTRWDSet : 37|2@0+ (1,0) [0|3] ""  FLZCU_HCU_IC,HCU_IC
 SG_ ICC_EXPERTAWDSet : 39|2@0+ (1,0) [0|3] ""  FLZCU_HCU_IC,HCU_IC
 SG_ ICC_EXPERTAutoSet : 41|2@0+ (1,0) [0|3] ""  FLZCU_HCU_IC,HCU_IC
 SG_ ICC_CLIMBSet : 43|2@0+ (1,0) [0|3] ""  FLZCU_HCU_IC,HCU_IC
 SG_ ICC_DriveModeExitSet : 45|2@0+ (1,0) [0|3] ""  FLZCU_HCU_IC,HCU_IC
 SG_ ICC_Confidencelevel : 62|7@0+ (1,-1) [0|100] "%"  FLZCU_HCU_IC,HCU_IC
 SG_ ICC_V2L_IntlDisChg : 81|2@0+ (1,0) [0|3] ""  FLZCU_HCU_IC,HCU_IC
 SG_ ICC_ExhibitionModeSwitch : 83|2@0+ (1,0) [0|3] ""  FLZCU_HCU_IC,FLZCU_IC,HCU_IC
 SG_ ICC_TrailerMode : 85|2@0+ (1,0) [0|3] ""  FLZCU_HCU_IC,HCU_IC
 SG_ ICC_V2L_DisChgMem : 87|2@0+ (1,0) [0|3] ""  FLZCU_HCU_IC,HCU_IC
 SG_ ICC_DrivePowerDispSet : 89|2@0+ (1,0) [0|3] ""  FLZCU_HCU_IC,HCU_IC
 SG_ ICC_WLTC_to_CLTC_Mode : 91|2@0+ (1,0) [0|3] ""  FLZCU_HCU_IC,HCU_IC
 SG_ ICC_StopChrgnSwitch : 93|2@0+ (1,0) [0|3] ""  FLZCU_HCU_IC,HCU_IC
 SG_ ICC_StopChrgnMode : 95|2@0+ (1,0) [0|3] ""  FLZCU_HCU_IC,HCU_IC
 SG_ ICC_RegenerateLevelCtrl : 98|3@0+ (1,0) [0|7] ""  FLZCU_HCU_IC,HCU_IC
 SG_ ICC_SinglePedalMem : 100|2@0+ (1,0) [0|3] ""  FLZCU_HCU_IC,HCU_IC
 SG_ ICC_FuelDetnSwt : 102|2@0+ (1,0) [0|3] ""  FLZCU_HCU_IC,HCU_IC
 SG_ ICC_FuelDetnState : 105|2@0+ (1,0) [0|3] ""  FLZCU_HCU_IC,HCU_IC
 SG_ ICC_FuelDetnOpDefeated : 107|2@0+ (1,0) [0|3] ""  FLZCU_HCU_IC,HCU_IC
 SG_ ICC_HVDownRepairMode : 109|2@0+ (1,0) [0|3] ""  FLZCU_HCU_IC,HCU_IC
 SG_ ICC_UTURNSnowSet : 111|2@0+ (1,0) [0|3] ""  FLZCU_HCU_IC,HCU_IC
 SG_ ICC_UTURNSandSet : 113|2@0+ (1,0) [0|3] ""  FLZCU_HCU_IC,HCU_IC
 SG_ ICC_UTURNMudSet : 115|2@0+ (1,0) [0|3] ""  FLZCU_HCU_IC,HCU_IC
 SG_ ICC_UTURNGrassSet : 117|2@0+ (1,0) [0|3] ""  FLZCU_HCU_IC,HCU_IC
 SG_ ICC_LTCDispSet2 : 124|2@0+ (1,0) [0|3] ""  FLZCU_HCU_IC,HCU_IC
 SG_ ICC_SetSocManage : 127|3@0+ (1,0) [0|7] ""  FLZCU_HCU_IC,HCU_IC

BO_ 1326 ICC_BD_36: 8 ICC
 SG_ ICC_DWDOnOff_Req : 17|2@0+ (1,0) [0|3] "" Vector__XXX
 SG_ ICC_ContainerLightSet : 19|2@0+ (1,0) [0|3] ""  FLZCU_HCU_IC,FLZCU_IC

BO_ 1331 ICC_IC_37: 32 ICC
 SG_ ICC_CMSMTouchSts : 123|2@0+ (1,0) [0|3] ""  CGW
 SG_ ICC_RLSeatEasyEntryExitSet : 17|2@0+ (1,0) [0|3] ""  PCL
 SG_ ICC_RRSeatEasyEntryExitSet : 19|2@0+ (1,0) [0|3] ""  PCL
 SG_ ICC_RLMemoryRecoveryCmd : 21|2@0+ (1,0) [0|3] ""  PCL
 SG_ ICC_RRMemoryRecoveryCmd : 23|2@0+ (1,0) [0|3] ""  PCL
 SG_ ICC_RLSitPosnlocation : 25|2@0+ (1,0) [0|3] ""  PCL
 SG_ ICC_RRSitPosnlocation : 27|2@0+ (1,0) [0|3] ""  PCL
 SG_ ICC_CMSMDisplaySwitch : 29|2@0+ (1,0) [0|3] "" Vector__XXX
 SG_ ICC_CMSMDisplayAdjustmode : 31|2@0+ (1,0) [0|3] "" Vector__XXX
 SG_ ICC_CMSMSetstandardSwitch : 33|2@0+ (1,0) [0|3] "" Vector__XXX
 SG_ ICC_LeftPedalControl : 35|2@0+ (1,0) [0|3] "" Vector__XXX
 SG_ ICC_RightPedalControl : 37|2@0+ (1,0) [0|3] "" Vector__XXX
 SG_ ICC_EPCEnable : 39|2@0+ (1,0) [0|3] "" Vector__XXX
 SG_ ICC_AMPKTVvoiceVolumeSet : 45|6@0+ (1,0) [0|63] ""  EAMP
 SG_ ICC_AMPA2BENCSoundReq : 47|2@0+ (1,0) [0|3] ""  EAMP
 SG_ ICC_AMPENCVolumeSet : 53|6@0+ (1,0) [0|63] ""  EAMP
 SG_ ICC_AMPA2BChimeSoundReq : 55|2@0+ (1,0) [0|3] ""  EAMP
 SG_ Set_AMPSoundFocus_2 : 63|4@0+ (1,0) [0|15] ""  EAMP
 SG_ ICC_AMPA2BKTVvoiceSoundReq : 58|3@0+ (1,0) [0|7] ""  EAMP
 SG_ ICC_MedStatusSet : 81|2@0+ (1,0) [0|3] ""  FLZCU_HCU_IC,FLZCU_IC
 SG_ Set_AMPLoudness : 83|2@0+ (1,0) [0|3] ""  EAMP
 SG_ ICC_MedAreaSet : 87|4@0+ (1,0) [0|15] ""  PCL,FLZCU_HCU_IC,FLZCU_IC
 SG_ ICC_LeftElectricPedalsSet : 89|2@0+ (1,0) [0|3] "" Vector__XXX
 SG_ ICC_RightElectricPedalsSet : 91|2@0+ (1,0) [0|3] "" Vector__XXX
 SG_ ICC_NapAreaSet2 : 95|3@0+ (1,0) [0|7] ""  PCL,FLZCU_HCU_IC,FLZCU_IC
 SG_ ICC_DisplayAdjustrAngReq : 103|8@0+ (1,0) [0|255] "°" Vector__XXX
 SG_ Set_AMPKeyVolume : 119|6@0+ (1,0) [0|63] ""  EAMP
 SG_ Set_AMPExSoundmode : 113|3@0+ (1,0) [0|7] ""  EAMP
 SG_ Set_AMPA2BENCSound : 126|3@0+ (1,0) [0|7] ""  EAMP

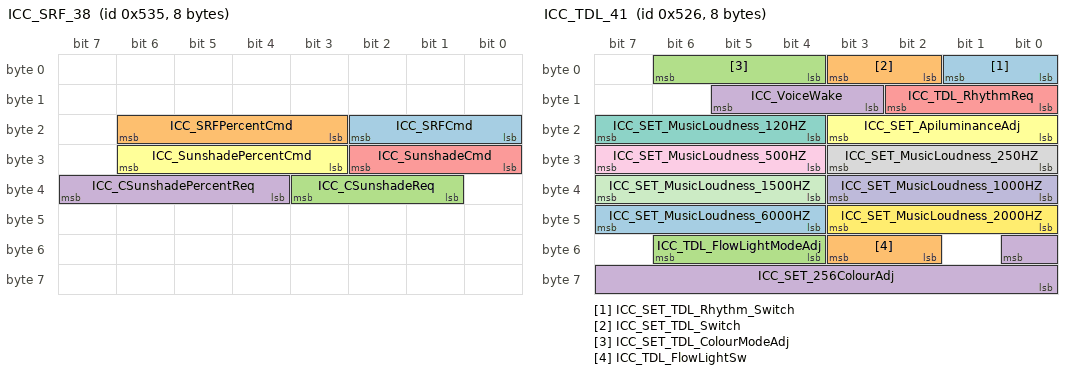
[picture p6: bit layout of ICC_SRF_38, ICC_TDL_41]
BO_ 1333 ICC_SRF_38: 8 ICC
 SG_ ICC_SRFCmd : 18|3@0+ (1,0) [0|7] ""  FLZCU_HCU_IC
 SG_ ICC_SRFPercentCmd : 22|4@0+ (1,0) [0|15] ""  FLZCU_HCU_IC
 SG_ ICC_CSunshadeReq : 35|3@0+ (1,0) [0|7] ""  FLZCU_HCU_IC
 SG_ ICC_CSunshadePercentReq : 39|4@0+ (1,0) [0|15] ""  FLZCU_HCU_IC
 SG_ ICC_SunshadeCmd : 26|3@0+ (1,0) [0|7] ""  FLZCU_HCU_IC
 SG_ ICC_SunshadePercentCmd : 30|4@0+ (1,0) [0|15] ""  FLZCU_HCU_IC

BO_ 1335 ICC_CH_39: 32 ICC
 SG_ New_Signal_537_3 : 47|24@0+ (1,0) [0|16777215] ""  CGW
 SG_ New_Signal_537_2 : 39|6@0+ (1,0) [0|63] ""  CGW
 SG_ New_Signal_537_1 : 23|1@0+ (1,0) [0|1] ""  CGW
 SG_ ICC_RolloverSetCmd : 33|2@0+ (1,0) [0|3] ""  CGW
 SG_ ICC_SET_EPS_SteerReturnRmdSts : 17|2@0+ (1,0) [0|3] ""  CGW
 SG_ ICC_SET_MFSShake : 19|2@0+ (1,0) [0|3] ""  CGW
 SG_ ICC_DMS_1_DistractionLevel : 22|3@0+ (1,0) [0|7] ""  CGW
 SG_ ICC_SET_EPS_AsociWithDrvModSts : 25|2@0+ (1,0) [0|3] ""  CGW
 SG_ ICC_OverLoadWarnShieldSet : 27|2@0+ (1,0) [0|3] ""  CGW
 SG_ ICC_BSWReq : 29|2@0+ (1,0) [0|3] ""  CGW
 SG_ ICC_horizontalReq : 31|2@0+ (1,0) [0|3] ""  CGW

BO_ 1337 ICC_TMS_40: 16 ICC
 SG_ ICC_SET_BT_ReduceWindSpeed : 17|2@0+ (1,0) [0|3] "" Vector__XXX
 SG_ ICC_SET_IPM_FirstBlowing : 19|2@0+ (1,0) [0|3] "" Vector__XXX
 SG_ ICC_SET_IPM_BlowerDelay : 21|2@0+ (1,0) [0|3] "" Vector__XXX
 SG_ ICC_SET_CirculationInTunnels : 23|2@0+ (1,0) [0|3] "" Vector__XXX
 SG_ ICC_UVCLuminanceReq : 25|2@0+ (1,0) [0|3] "" Vector__XXX
 SG_ ICC_UVCControlReq : 27|2@0+ (1,0) [0|3] "" Vector__XXX
 SG_ ICC_CrossCountryCoolingReq : 29|2@0+ (1,0) [0|3] "" Vector__XXX
 SG_ ICC_KeepWarmReq : 31|2@0+ (1,0) [0|3] "" Vector__XXX
 SG_ ICC_keepwarmSetTemperatureReq : 39|8@0+ (1,0) [0|255] "" Vector__XXX
 SG_ ICC_ParkingAirConditioning : 41|2@0+ (1,0) [0|3] "" Vector__XXX
 SG_ ICC_CoolantFill_Req : 43|2@0+ (1,0) [0|3] "" Vector__XXX
 SG_ ICC_FraganceLightoffReq : 45|2@0+ (1,0) [0|3] "" Vector__XXX
 SG_ ICC_FraganceMemoffReq : 47|2@0+ (1,0) [0|3] "" Vector__XXX
 SG_ ICC_AirPurgeReminderReq : 55|2@0+ (1,0) [0|3] "" Vector__XXX
 SG_ ICC_CFSCycleLevel : 53|3@0+ (1,0) [0|7] "" Vector__XXX
 SG_ ICC_TimingLevel : 50|3@0+ (1,0) [0|7] "" Vector__XXX
 SG_ ICC_ModeAdjustDisplaySts : 63|4@0+ (1,0) [0|15] "" Vector__XXX
 SG_ ICC_BiochemicalFuncReq : 59|2@0+ (1,0) [0|3] ""  CGW
 SG_ ICC_TimedVentilationReq : 57|2@0+ (1,0) [0|3] ""  CGW
 SG_ ICC_PetmodeSetTemperature_L_C : 87|5@0+ (0.5,15.5) [15.5|30.5] "℃"  CGW
 SG_ ICC_PetModeSetTemperature_R_C : 82|5@0+ (0.5,15.5) [15.5|30.5] "℃"  CGW
 SG_ ICC_PetModeSetCLMOn : 93|2@0+ (1,0) [0|3] ""  CGW
 SG_ ICC_PetModeSetAutoKeySts : 91|2@0+ (1,0) [0|3] ""  CGW
 SG_ ICC_PetModeSetCirculationSts : 89|2@0+ (1,0) [0|3] ""  CGW

BO_ 1318 ICC_TDL_41: 8 ICC
 SG_ ICC_SET_TDL_Rhythm_Switch : 1|2@0+ (1,0) [0|3] ""  FLZCU_HCU_IC
 SG_ ICC_SET_TDL_Switch : 3|2@0+ (1,0) [0|3] ""  FLZCU_HCU_IC
 SG_ ICC_SET_TDL_ColourModeAdj : 6|3@0+ (1,0) [0|7] ""  FLZCU_HCU_IC
 SG_ ICC_VoiceWake : 13|3@0+ (1,0) [0|7] ""  FLZCU_HCU_IC
 SG_ ICC_TDL_RhythmReq : 10|3@0+ (1,0) [0|7] ""  FLZCU_HCU_IC
 SG_ ICC_SET_ApiluminanceAdj : 19|4@0+ (1,0) [0|15] ""  FLZCU_HCU_IC
 SG_ ICC_SET_MusicLoudness_120HZ : 23|4@0+ (1,0) [0|15] ""  FLZCU_HCU_IC
 SG_ ICC_SET_MusicLoudness_250HZ : 27|4@0+ (1,0) [0|15] ""  FLZCU_HCU_IC
 SG_ ICC_SET_MusicLoudness_500HZ : 31|4@0+ (1,0) [0|15] ""  FLZCU_HCU_IC
 SG_ ICC_SET_MusicLoudness_1000HZ : 35|4@0+ (1,0) [0|15] ""  FLZCU_HCU_IC
 SG_ ICC_SET_MusicLoudness_1500HZ : 39|4@0+ (1,0) [0|15] ""  FLZCU_HCU_IC
 SG_ ICC_SET_MusicLoudness_2000HZ : 43|4@0+ (1,0) [0|15] ""  FLZCU_HCU_IC
 SG_ ICC_SET_MusicLoudness_6000HZ : 47|4@0+ (1,0) [0|15] ""  FLZCU_HCU_IC
 SG_ ICC_TDL_FlowLightSw : 51|2@0+ (1,0) [0|3] ""  FLZCU_HCU_IC
 SG_ ICC_TDL_FlowLightModeAdj : 54|3@0+ (1,0) [0|7] ""  FLZCU_HCU_IC
 SG_ ICC_SET_256ColourAdj : 48|9@0+ (1,0) [0|256] ""  FLZCU_HCU_IC

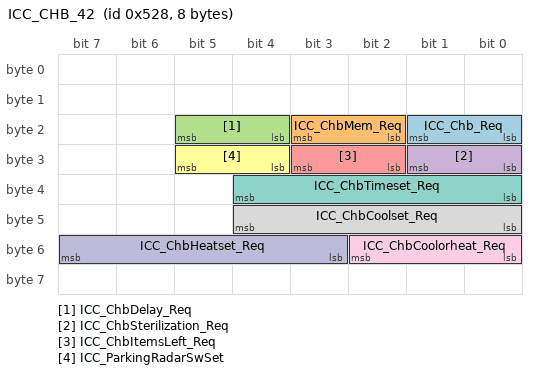
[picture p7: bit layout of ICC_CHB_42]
BO_ 1320 ICC_CHB_42: 8 ICC
 SG_ ICC_Chb_Req : 17|2@0+ (1,0) [0|3] "" Vector__XXX
 SG_ ICC_ChbMem_Req : 19|2@0+ (1,0) [0|3] "" Vector__XXX
 SG_ ICC_ChbDelay_Req : 21|2@0+ (1,0) [0|3] "" Vector__XXX
 SG_ ICC_ChbSterilization_Req : 25|2@0+ (1,0) [0|3] "" Vector__XXX
 SG_ ICC_ChbItemsLeft_Req : 27|2@0+ (1,0) [0|3] "" Vector__XXX
 SG_ ICC_ParkingRadarSwSet : 29|2@0+ (1,0) [0|3] "" Vector__XXX
 SG_ ICC_ChbTimeset_Req : 36|5@0+ (1,0) [0|31] "h" Vector__XXX
 SG_ ICC_ChbCoolset_Req : 44|5@0+ (1,0) [0|31] "" Vector__XXX
 SG_ ICC_ChbCoolorheat_Req : 50|3@0+ (1,0) [0|7] "" Vector__XXX
 SG_ ICC_ChbHeatset_Req : 55|5@0+ (1,0) [0|31] "" Vector__XXX

BO_ 1360 ICC_LC_42: 64 ICC
 SG_ ICC_XDriveMode : 40|5@0+ (1,0) [0|31] ""  FLZCU_HCU_IC,HCU_IC
 SG_ ICC_LISD_DisplaySwitch : 1|2@0+ (1,0) [0|3] ""  CGW
 SG_ ICC_LISD_ParkingShowCMD : 3|2@0+ (1,0) [0|3] ""  CGW
 SG_ ICC_RoofCampLampSetL : 5|2@0+ (1,0) [0|3] ""  FLZCU_HCU_IC,FLZCU_Signal_IC,CGW
 SG_ ICC_RISD_DisplaySwitch : 7|2@0+ (1,0) [0|3] ""  CGW
 SG_ ICC_RISD_ParkingShowCMD : 9|2@0+ (1,0) [0|3] ""  CGW
 SG_ ICC_RoofCampLampSetR : 11|2@0+ (1,0) [0|3] ""  FLZCU_HCU_IC,FLZCU_Signal_IC,CGW
 SG_ ICC_LogoParkingReq : 13|2@0+ (1,0) [0|3] ""  CGW
 SG_ ICC_LogoChargingReq : 15|2@0+ (1,0) [0|3] ""  FLZCU_HCU_IC,FLZCU_IC,CGW
 SG_ ICC_DRLSw : 17|2@0+ (1,0) [0|3] ""  FLZCU_HCU_IC,FLZCU_IC,CGW
 SG_ ICC_TopLightSet : 19|2@0+ (1,0) [0|3] ""  FLZCU_HCU_IC,FLZCU_Signal_IC,CGW
 SG_ ICC_APillarYellowAmbientSet : 21|2@0+ (1,0) [0|3] ""  FLZCU_HCU_IC,FLZCU_Signal_IC,CGW
 SG_ ICC_APillarWhiteAmbientSet : 23|2@0+ (1,0) [0|3] ""  FLZCU_HCU_IC,FLZCU_Signal_IC,CGW
 SG_ ICC_LISD_ParkingShowMod : 27|4@0+ (1,0) [0|15] ""  CGW
 SG_ ICC_RISD_ParkingShowMod : 31|4@0+ (1,0) [0|15] ""  CGW
 SG_ ICC_APillarSpotLampSet : 39|2@0+ (1,0) [0|3] ""  FLZCU_HCU_IC,FLZCU_Signal_IC,CGW
 SG_ ICC_PenetrationLampSetF : 37|2@0+ (1,0) [0|3] ""  FLZCU_HCU_IC,FLZCU_IC,CGW
 SG_ ICC_MusicLampShowSW : 35|2@0+ (1,0) [0|3] ""  FLZCU_HCU_IC,FLZCU_IC,CGW
 SG_ ICC_LogoColorReq : 33|9@0+ (1,0) [0|511] ""  CGW

CM_ SG_ 1254 ICC_WelcomeOpenSet "迎宾灯开启设置";
CM_ SG_ 1254 ICC_WALOpenSet "远离闭锁开关设置";
CM_ SG_ 1254 ICC_EasytrunkSet "尾门感应开启设置开关";
CM_ SG_ 1254 ICC_UIROpenSet "靠近解锁开关设置";
CM_ SG_ 1254 ICC_BeanIDReq "车端大屏请求设备号";
CM_ SG_ 1254 ICC_CWCWorkingStsSet "通过DVD软按键控制无线充电器工作模式
0x0：不动作
0x1: 无线充电器关闭
0x2: 无线充电器打开
0x3：无效
CWC收到DVD的0x0、0x3时保持CWC当前开关状态";
CM_ SG_ 1254 ICC_CWCPhoneforgottenFunStsSet "通过DVD软按键控制无线充电器手机遗忘提醒功能的开关
0x0：不动作
0x1: 手机遗忘提醒功能关闭
0x2: 手机遗忘提醒功能打开
0x3：无效
CWC收到DVD的0x0、0x3时保持CWC当前手机遗忘提醒功能开关状态";
CM_ SG_ 1254 ICC_RCWCWorkingStsSet "通过DVD软按键控制无线充电器工作模式
0x0：不动作
0x1: 无线充电器关闭
0x2: 无线充电器打开
0x3：无效
RCWC收到DVD的0x0、0x3时保持RCWC当前开关状态";
CM_ SG_ 1296 CurrentTimeYear "时间（年）";
CM_ SG_ 1296 CurrentTimeMonth "时间（月）";
CM_ SG_ 1296 CurrentTimeDay "时间（日）";
CM_ SG_ 1296 CurrentTimeHour "时间（时）";
CM_ SG_ 1296 CurrentTimeMinute "时间（分）";
CM_ SG_ 1296 CurrentTimeSecond "时间（秒）";
CM_ SG_ 1447 CurrentTimeYear_UTC "时间（年）";
CM_ SG_ 1447 CurrentTimeMonth_UTC "时间（月）";
CM_ SG_ 1447 CurrentTimeDay_UTC "时间（日）";
CM_ SG_ 1447 CurrentTimeHour_UTC "时间（时）";
CM_ SG_ 1447 CurrentTimeMinute_UTC "时间（分）";
CM_ SG_ 1447 CurrentTimeSecond_UTC "时间（秒）";
CM_ SG_ 1100 Set_AMPNaviVolume "Amplifier navigation volume status";
CM_ SG_ 1100 Set_AMPVRVolume "Amplifier voice recognize volume status";
CM_ SG_ 1100 Set_AMPKeyTone "Amplifier key tone status";
CM_ SG_ 1100 Set_AMPMediaVolume "Amplifier media volume status";
CM_ SG_ 1100 Set_AMPPhoneVolume "Amplifier phone volume status";
CM_ SG_ 1100 Set_AMPSoundFocus "Amplifier sound focus status";
CM_ SG_ 1100 Set_AMPSoundEffect "Amplifier sound effect status";
CM_ SG_ 1100 Set_AMPSoundEffectBass "Amplifier sound effect bass status";
CM_ SG_ 1100 Set_AMPSoundEffectMidrange "Amplifier sound effect midrange status";
CM_ SG_ 1100 Set_AMPSoundEffectTreble "Amplifier sound effect treble status";
CM_ SG_ 1100 Set_AMPSoundFieldBalance "Amplifier sound field balance status";
CM_ SG_ 1100 Set_AMPSoundFieldFader "Amplifier sound field fader status";
CM_ SG_ 1100 Set_Headrest_Mode "Headrest_Mode";
CM_ SG_ 1100 Set_SurndFnOnOff "Surround Function On Off Switch";
CM_ SG_ 1100 Set_VirtualSbwfrOnOff "Virtual_Subwoofer_On_Off_Request";
CM_ SG_ 1119 Set_AMPMediaDuck "Media Duck request to amplifier/发送媒体降音需求给外置功放";
CM_ SG_ 1119 Set_AMPSpeedVolume "Amplifier vehicle speed volume compensation setting";
CM_ SG_ 1119 Set_AMPMute "Amplifier audio mute or not setting";
CM_ SG_ 1119 REQ_AMPA2BMediaSound "Head unit media sound request to amplifier";
CM_ SG_ 1119 REQ_AMPA2BNaviSound "Head unit navigation sound request to amplifier";
CM_ SG_ 1119 REQ_AMPA2BVRSound "Head unit VR sound request to amplifier";
CM_ SG_ 1119 REQ_AMPA2BTTSSound "Head unit TTS sound request to amplifier";
CM_ SG_ 1119 REQ_AMPA2BKeyTone "Head unit Beep sound request to amplifier";
CM_ SG_ 1119 Set_AMPRestoreDefaults "Amplifier audio restore defaults setting/恢复默认音频参数设置开关";
CM_ SG_ 1119 Set_AMPAlarmVolume "Amplifier instrument panel cluster alarm volume setting/警报音量值设定";
CM_ SG_ 1119 REQ_AMPA2BPhoneSound "Head unit BT Phone and Tbox sound request to amplifier/电话/Tbox音源需求设定";
CM_ SG_ 1119 Set_AMPSoundEffectMegaBass "Amplifier sound effect megabass setting/重低音设定";
CM_ SG_ 1119 Set_AMPSoundEffectMidBass "Amplifier sound effect midbass setting/中低音设定";
CM_ SG_ 1119 Set_AMPSoundEffectMidTreble "Amplifier sound effect midtreble setting/中高音设定";
CM_ SG_ 1119 Set_AMPBackgroundVolume "Amplifier background media volume status/背景音（迎宾音）音量值设定";
CM_ SG_ 1119 Set_AMPSoundBypass "Amplifier sound bypass need/第三方APP打开时，外置功放做音效bypass处理";
CM_ SG_ 1119 Set_AMPA2BConfig "Amplifier A2B Config status/EAMP的A2B节点配置完成后，下发OK";
CM_ SG_ 1150 ICC_BD_11_CRC "Profile1A:E2E CRC (SAE J1850 CRC-8) for 8 Bytes
DataID:0x009E";
CM_ SG_ 1150 ICC_BD_11_RollgCntr "Profile1A:E2E Rolling message counter(the maximum value of Alive counter is 14)";
CM_ SG_ 1150 ICC_CPDDelaySwitchSet "CIR功能延迟开关设置状态";
CM_ SG_ 1150 ICC_PPMIDBSRBPASet "Belt slack reduction(BSR) / 织带间隙消除
Belt parking assist(BPA) / 织带辅助回收";
CM_ SG_ 1150 ICC_PPMIDHwSet "Haptic Warning(HWA) /  震动触觉提醒";
CM_ SG_ 1150 ICC_DriveDrosinessLevel "0x0: not available;驾驶员在位检测输出“不在位”的时候触发
0x1: unknown;驾驶员不疲劳的默认状态
0x2: not fatigue;驾驶员不疲劳
0x3: lightly fatigue轻度疲劳,;
0x4: moderate fatigue中度疲劳;
0x5: severe fatigue重度疲劳;
0x6~0x7: Reserved";
CM_ SG_ 1150 ICC_FLDoorButton "大屏主驾门打开关闭，按钮按下是0x2 Active,不按是0x1 Inactive";
CM_ SG_ 1150 ICC_FRDoorButton "大屏副驾门打开关闭，按钮按下是0x2 Active,不按是0x1 Inactive";
CM_ SG_ 1150 ICC_RRDoorButton "大屏右后门打开关闭 按钮按下是0x2 Active,不按是0x1 Inactive";
CM_ SG_ 1150 ICC_RLDoorButton "大屏左后门打开关闭，按钮按下是0x2 Active,不按是0x1 Inactive";
CM_ SG_ 1150 ICC_CloseAllDoors "大屏一键电动门全关，按钮按下是0x2 Active,不按是0x1 Inactive";
CM_ SG_ 1150 ICC_DoorRemoteKeyControlEnable "长按钥匙远程控制使能";
CM_ SG_ 1150 ICC_SetOpenAngle "大屏设置侧门开度";
CM_ SG_ 1150 ICC_CPDSwitchSet "CIR功能开关设置状态";
CM_ SG_ 1150 ICC_FrontDoorPowerMode "前门手动模式、电动模式、半自动模式";
CM_ SG_ 1150 ICC_RearDoorPowerMode "后门手动模式、电动模式、半自动模式";
CM_ SG_ 1150 ICC_PedalCloseDriverDoorEnable "刹车踏板控制驾驶门 功能使能";
CM_ SG_ 1150 RR_Door_RearScreen_Control "The rear screen controls the door function to open/close/stop the rear door后排屏幕控制车门";
CM_ SG_ 1150 ICC_RearDoorVoiceControlEnable "后门语音控制使能";
CM_ SG_ 1150 ICC_FLVoiceControl "左前门语音控制";
CM_ SG_ 1150 ICC_FRVoiceControl "右前门语音控制";
CM_ SG_ 1150 ICC_RRVoiceControl "右后门语音控制";
CM_ SG_ 1150 ICC_RLVoiceControl "左后门语音控制";
CM_ SG_ 1150 RL_Door_RearScreen_Control "The rear screen controls the door function to open/close/stop the rear door后排屏幕控制车门";
CM_ SG_ 917 RandomMusicShowCMD "RandomMusic";
CM_ SG_ 917 DIYMusicShowmod "DIYMusicShow";
CM_ SG_ 917 LiShowMod "LightShowMode";
CM_ SG_ 917 MusicLoudness_55HZ "The corresponding audio loudness when the sampling point music frequency is 
55HZ
Note:
1.When DVD don't display music , DVD send this signal value 0x1F
2.Within a cycle time, If DVD don't acquire this frequency, DVD send this signal value 0x1F";
CM_ SG_ 917 MusicLoudness_123HZ "The corresponding audio loudness when the sampling point music frequency is 123HZ
Note:
1.When DVD don't display music , DVD send this signal value 0x1F
2.Within a cycle time, If DVD don't acquire this frequency, DVD send this signal value 0x1F";
CM_ SG_ 917 MusicLoudness_262HZ "The corresponding audio loudness when the sampling point music frequency is 262HZ
Note:
1.When DVD don't display music , DVD send this signal value 0x1F
2.Within a cycle time, If DVD don't acquire this frequency, DVD send this signal value 0x1F";
CM_ SG_ 917 MusicLoudness_440HZ "The corresponding audio loudness when the sampling point music frequency is 440HZ
Note:
1.When DVD don't display music , DVD send this signal value 0x1F
2.Within a cycle time, If DVD don't acquire this frequency, DVD send this signal value 0x1F";
CM_ SG_ 917 MusicLoudness_587HZ "The corresponding audio loudness when the sampling point music frequency is 587HZ
Note:
1.When DVD don't display music , DVD send this signal value 0x1F
2.Within a cycle time, If DVD don't acquire this frequency, DVD send this signal value 0x1F";
CM_ SG_ 917 MusicLoudness_784HZ "The corresponding audio loudness when the sampling point music frequency is 784HZ
Note:
1.When DVD don't display music , DVD send this signal value 0x1F
2.Within a cycle time, If DVD don't acquire this frequency, DVD send this signal value 0x1F";
CM_ SG_ 917 MusicLoudness_1318HZ "The corresponding audio loudness when the sampling point music frequency is 1318HZ
Note:
1.When DVD don't display music , DVD send this signal value 0x1F
2.Within a cycle time, If DVD don't acquire this frequency, DVD send this signal value 0x1F";
CM_ SG_ 917 MusicLoudness_2794HZ "The corresponding audio loudness when the sampling point music frequency is 2794HZ
Note:
1.When DVD don't display music , DVD send this signal value 0x1F
2.Within a cycle time, If DVD don't acquire this frequency, DVD send this signal value 0x1F";
CM_ SG_ 917 MusicLoudness_6272HZ "The corresponding audio loudness when the sampling point music frequency is 6272HZ
Note:
1.When DVD don't display music , DVD send this signal value 0x1F
2.Within a cycle time, If DVD don't acquire this frequency, DVD send this signal value 0x1F";
CM_ SG_ 917 ISDShowCMD "ISD灯光开启,同一个模式若想反复播放，需要先";
CM_ SG_ 917 ISDShowMode "ISD灯光模式";
CM_ SG_ 1273 FaceID "人脸ID";
CM_ SG_ 1157 ICC_DA_15_CRC "Profile1A:E2E CRC (SAE J1850 CRC-8) for 8 Bytes
DataID:0x009D";
CM_ SG_ 1157 ICC_DA_15_RollgCntr "Profile1A:E2E Rolling message counter(the maximum value of Alive counter is 14)";
CM_ SG_ 1157 ICC_DA_15_Resd "Profile1A:E2E Reserved";
CM_ SG_ 1157 ICC_DA_15_BSDLCWSettingSt "BSD/LCA function setting button status";
CM_ SG_ 1157 ICC_DA_15_DOWSettingSt "Door open warning function setting button status";
CM_ SG_ 1157 ICC_DA_15_RCWSettingSt "Rear Collision Warning function setting button status";
CM_ SG_ 1157 ICC_DA_15_RCTARCTBWarnType "RCTA/RCTB function setting button status";
CM_ SG_ 1157 ICC_DA_15_FCTAFCTBWarnType "FCTA/FCTB function setting button status";
CM_ SG_ 1157 ICC_DA_15_FrontPDCMuteSet "前PDC、侧PDC声音开关";
CM_ SG_ 1157 ICC_DA_15_FKPMuteSet "侧PDC声音开关";
CM_ SG_ 1157 Driver_EyeOnRoad "indicate Driver Eyes On Road status";
CM_ SG_ 1157 Dms_Status "DMS(Driver Monitor System) Status
驾驶员监测状态";
CM_ SG_ 1157 Driver_AbnormalBehavior "Driver Abnormal Behavior detection result
非正常行为";
CM_ SG_ 1157 Driver_GazeRegion "Driver Gaze Region
凝视的区域";
CM_ SG_ 1157 Dms_DriverPresence "indicate Driver Presence detection status
未检测到驾驶员";
CM_ SG_ 1157 ICC_IHCfunctionSw "智能远光辅助开关";
CM_ SG_ 1279 Weather_Type "天气类型
0x1：晴天
0x2：多云
0x3：阴天
0x4：阵雨
0x5：雷阵雨
0x6：雷阵雨夹冰雹
0x7：雨夹雪
0x8：小雨
0x9：中雨
0xA：大雨
0xB：暴风雨
0xF：小雪
0x10：中雪
0x11：大雪
0x12：暴风雪
0x13：雾天
0x15：尘暴
0x1E：尘埃
0x1F：风沙
0x21：雾霾";
CM_ SG_ 1279 ICC_SentinelModeSts "哨兵模式开启/关闭的状态";
CM_ SG_ 1279 ICC_CameraErrorCode "ICC侧Camera链路错误码";
CM_ SG_ 1279 ICC_SentinelRequest "哨兵模式进入，退出请求";
CM_ SG_ 1279 ICC_StartDeInitCameraStream "ICC通知ADCC开始关闭Camera视频流";
CM_ SG_ 1279 ICC_CameraRecoveryRequest "ICC通知ADCC恢复Camera视频链路";
CM_ SG_ 1279 ICC_CleanMode "洗车模式(主项目沿用)";
CM_ SG_ 644 ICM_5_FuelLevel "备注：国六项目EMS收，滤波后的燃油液位信息";
CM_ SG_ 644 FuelShortGround "备注：国六项目EMS收，短路到地";
CM_ SG_ 644 FuelShortPower "备注：国六项目EMS收，短路到电源";
CM_ SG_ 644 FuelOutOfRange "备注：国六项目EMS收。超范围";
CM_ SG_ 644 FuelValidData "备注：国六项目EMS收，开路，信号丢失";
CM_ SG_ 1174 IHU_SetSocManage "0x0:Not Active
0x1:Pure electricity priority mode（纯电优先）
0x2:Fuel priority mode（燃油优先）
0x3:SOC hold mode（电量保持）
0x4~0x7:Reserved";
CM_ SG_ 1174 IHU_SetSOC "设置电池";
CM_ SG_ 1174 CTP_PowerModeSet "动力模式设置";
CM_ SG_ 1174 LidOpenReq "加油小门开启请求";
CM_ SG_ 1174 ICC_ForcedEVMode "设置强制EV模式";
CM_ SG_ 1174 ICC_EmissionMode "设置排放检测模式";
CM_ SG_ 1174 ICC_ForcedEVChargeMode "设置强制发电模式";
CM_ SG_ 1174 EVOdometer_km "EV总里程";
CM_ SG_ 1174 EVOdometer_km_ValidData "EV总里程有效值";
CM_ SG_ 1174 ICC_SetChrgnFctMem "强制保电记忆开关设置";
CM_ SG_ 1242 ICC_DK_19_CRC1 "Profile1A:E2E CRC (SAE J1850 CRC-8) for 8 Bytes
DataID:No ASIL requirements.Not configure
CRC Reserved.";
CM_ SG_ 1242 ICC_DK_19_RollgCntr1 "Profile1A:E2E Rolling message counter(the maximum value of Alive counter is 14)";
CM_ SG_ 1242 ICC_DK_19_Resd1 "Profile1A:E2E Reserved";
CM_ SG_ 1242 ICC_DK_19_CMD "收到0不处理";
CM_ SG_ 1242 ICC_DK_19_PDU1 "收到0不处理";
CM_ SG_ 1242 ICC_DK_19_PDU2 "收到0不处理";
CM_ SG_ 1242 ICC_DK_19_PDU3 "收到0不处理";
CM_ SG_ 1242 ICC_DK_19_PDU4 "收到0不处理";
CM_ SG_ 1276 PassSeatHeiAdjmt_Target "座椅高度调节目标位置（大屏调节请求）";
CM_ SG_ 1276 SeatBackAndFwdAdjmt_Target "座椅水平调节目标值（大屏调节请求）";
CM_ SG_ 1276 SeatBackAgAdjmt_Target "座椅靠背角度调节目标值（大屏调节请求）";
CM_ SG_ 1276 Set_ProfileID "Set personalization profile ID number（记忆设置）";
CM_ SG_ 1276 SeatCushAgAdjmt_Target "座椅坐垫角度调节目标值（大屏调节请求）";
CM_ SG_ 1276 LgRstFwdAndBckAdjmt_Target "腿托前后位置目标值（大屏调节请求）";
CM_ SG_ 1276 FootRestAdjmt_Target "脚托调整位置目标值（大屏调节请求）";
CM_ SG_ 1276 REQ_SeatPosRecall "Seat position recall request";
CM_ SG_ 1276 REQ_SeatPosStore "Seat position store request";
CM_ SG_ 1276 Set_ToDefault "IHU setting function";
CM_ SG_ 1276 Set_EasyEntryEnable "Easy entry Set";
CM_ SG_ 1276 REQ_SeatHeatPass "Passenger Seat heating request from head unit";
CM_ SG_ 1276 REQ_SeatVentPass "Passenger Seat venting request from head unit";
CM_ SG_ 1276 PassSeatMsgStr_LvlCmd "0x0:未激活
0x1:关
0x2:低
0x3:中
0x4:高";
CM_ SG_ 1276 PassSeatMsg_ModeCmd "0x0：无动作
0x1:脉冲模式
0x2:波浪模式
0x3:猫步模式
0x4:单排模式
0x5:交叉模式
0x6:蝶形模式
0x7:腰部按摩模式
0x8:蛇形模式
0x9:特殊模式1
0xA:特殊模式2
0xB:特殊模式3
0xC:特殊模式4";
CM_ SG_ 1059 ICC_FLSeatHeatLevelCmd "一排主驾座椅加热信号";
CM_ SG_ 1059 ICC_FRSeatHeatLevelCmd "一排副驾座椅加热信号";
CM_ SG_ 1059 ICC_TrunkSW "后备箱开关";
CM_ SG_ 1059 ICC_Set_PLGOperateSts "电动尾门开度调节";
CM_ SG_ 1059 ICC_RLSeatHeatLevelCmd "二排左座椅加热";
CM_ SG_ 1059 ICC_RRSeatHeatLevelCmd "二排右座椅加热";
CM_ SG_ 1059 ICC_FLSeatVentLevelCmd "主驾座椅通风";
CM_ SG_ 1059 ICC_FRSeatVentLevelCmd "副驾座椅通风";
CM_ SG_ 1059 ICC_RLSeatVentLevelCmd "二排左座椅通风";
CM_ SG_ 1059 ICC_RRSeatVentLevelCmd "二排右座椅通风";
CM_ SG_ 1059 ICC_FrontWiperMaintenanceMode "大屏设置前雨刮维修
0x1:ON 进入维修
0x2: OFF退出维修";
CM_ SG_ 1059 ICC_RearWiperMaintenanceMode "大屏设置后雨刮维修
0x1:ON 进入维修
0x2: OFF退出维修";
CM_ SG_ 1056 ICC_DSBH_HeatReq "加热请求信号";
CM_ SG_ 1056 ICC_DSBH_SetTemp "设置加热温度，范围为30-65℃，即0x1E-0x41";
CM_ SG_ 1056 ICC_PSBH_HeatReq "加热请求信号";
CM_ SG_ 1056 ICC_PSBH_SetTemp "设置加热温度，范围为30-65℃，即0x1E-0x41";
CM_ SG_ 1112 PassSeatMsgStr_LvlCmd "0x0:未激活
0x1:关
0x2:低
0x3:中
0x4:高";
CM_ SG_ 1112 PassSeatMsg_ModeCmd "0x0:无动作
0x1:脉冲模式
0x2:波浪模式
0x3:猫步模式
0x4:单排模式
0x5:交叉模式
0x6:蝶形模式
0x7:腰部按摩模式
0x8:蛇形模式
0x9:特殊模式1
0xA:特殊模式2
0xB:特殊模式3
0xC:特殊模式4";
CM_ SG_ 1112 DriverSeatMsgStr_Lvlcmd "0x0:未激活
0x1:关
0x2:低
0x3:中
0x4:高";
CM_ SG_ 1112 DriverSeatMsg_ModeCmd "0x0:无动作
0x1:脉冲模式
0x2:波浪模式
0x3:猫步模式
0x4:单排模式
0x5:交叉模式
0x6:蝶形模式
0x7:腰部按摩模式
0x8:蛇形模式
0x9:特殊模式1
0xA:特殊模式2
0xB:特殊模式3
0xC:特殊模式4";
CM_ SG_ 1112 RightSeatMsgStr_LvlCmd "0x0:未激活
0x1:关
0x2:低
0x3:中
0x4:高";
CM_ SG_ 1112 RightSeatMsg_ModeCmd "0x0:无动作
0x1:脉冲模式
0x2:波浪模式
0x3:猫步模式
0x4:单排模式
0x5:交叉模式
0x6:蝶形模式
0x7:腰部按摩模式
0x8:蛇形模式
0x9:特殊模式1
0xA:特殊模式2
0xB:特殊模式3
0xC:特殊模式4";
CM_ SG_ 1112 LeftSeatMsgStr_LvlCmd "0x0:未激活
0x1:关
0x2:低
0x3:中
0x4:高";
CM_ SG_ 1112 LeftSeatMsg_ModeCmd "0x0:无动作
0x1:脉冲模式
0x2:波浪模式
0x3:猫步模式
0x4:单排模式
0x5:交叉模式
0x6:蝶形模式
0x7:腰部按摩模式
0x8:蛇形模式
0x9:特殊模式1
0xA:特殊模式2
0xB:特殊模式3
0xC:特殊模式4";
CM_ SG_ 1265 ICC_PwrOff "车辆下电";
CM_ SG_ 1265 ICC_EtmEgySave "极致节能模式";
CM_ SG_ 1265 ICC_HoodSW "前舱盖开关";
CM_ SG_ 1265 ICC_GloveboxSW "手套箱开关";
CM_ SG_ 1265 ICC_ChrgPortCover_Switch "充电口盖开关";
CM_ SG_ 1265 ICC_ReWinDefrstSwt "Rear window defrost后风窗加热";
CM_ SG_ 1265 ICC_RearMirrorFoldCmd "后视镜手动折叠开关";
CM_ SG_ 1265 ICC_CenterLockSwt "CenterLock中控锁开关";
CM_ SG_ 1265 ICC_ReverseExtMirrorSts "DVD设置倒车外后视镜下翻功能开启";
CM_ SG_ 1265 ICC_LightMainSwitchSts "小灯、近光、Auto开关";
CM_ SG_ 1265 ICC_AutoFoldSts "后视镜自动折叠";
CM_ SG_ 1265 ICC_HeadlampHeightSts "大灯高度调节设置信号";
CM_ SG_ 1265 ICC_WiprSnvty "WiperSensitivity雨刮灵敏度";
CM_ SG_ 1265 ICC_WindowCmd "语音控制车窗指令：
1、包含对左前车窗、右前车窗、左后车窗、右后车窗、前排车窗、后排车窗、全部车窗的指令控制；
2、具备open（打开）、close（关闭）、comfort（通风）三种动作指令，目前只有同时控制四个车窗时有comfort指令。
3、没有此功能，其他信号触发此帧报文发送时，此信号发“Not active”；";
CM_ SG_ 1265 ICC_LowBeamDelayOff "大灯延迟关闭开关";
CM_ SG_ 1265 ICC_FLWinCmd "玻璃升降防夹（霍尔、纹波）左前窗";
CM_ SG_ 1265 ICC_FRWinCmd "玻璃升降防夹（霍尔、纹波）右前窗";
CM_ SG_ 1265 ICC_RLWinCmd "玻璃升降防夹（霍尔、纹波）左后窗";
CM_ SG_ 1265 ICC_RRWinCmd "玻璃升降防夹（霍尔、纹波）左后窗";
CM_ SG_ 1265 ICC_FGHeatSts "设置前挡风加热";
CM_ SG_ 1265 ICC_AutolockSts "设置自动落锁模式";
CM_ SG_ 1265 ICC_WiperID "雨刮ID";
CM_ SG_ 1265 ICC_MaintenanceMode "雨刮维修模式开关";
CM_ SG_ 1265 ICC_lockSetSwitchSts "解闭锁设置";
CM_ SG_ 1265 ICC_ChildLockSW "儿童锁开关";
CM_ SG_ 1265 ICC_ParkUnlockEnable "驻车解锁设置";
CM_ SG_ 1265 ICC_BLEOpenDriverDoorEnable "蓝牙靠近开门设置";
CM_ SG_ 1265 ICC_WinInhbSwt "Window Inhibit 玻璃禁止开关";
CM_ SG_ 1265 ICC_SteerWhlHeatgSwt "Steering Wheel heating方向盘加热";
CM_ SG_ 1265 ICC_AutoHeatingset "后视镜自动加热设置";
CM_ SG_ 1265 ICC_FrontFogSw "屏内前雾灯开关";
CM_ SG_ 1265 ICC_RearFogSw "屏内后雾灯开关";
CM_ SG_ 1265 ICC_DoorControlSW "顶灯门控开关";
CM_ SG_ 1265 ICC_LockCarWinCloseSw "锁车自动升窗开关";
CM_ SG_ 1265 ICC_RainCarWinCloseSw "雨天自动升窗开关";
CM_ SG_ 1265 ICC_EasyEntryExitSet "便捷进入\离车";
CM_ SG_ 1265 ICC_NapTimeSet "小憩模式时长设置";
CM_ SG_ 1265 ICC_NapAreaSet "小憩模式开启区域设置";
CM_ SG_ 1265 ICC_NapStatusSet "小憩模式开关设置";
CM_ SG_ 1265 ICC_NapCFSStatusSet "小憩模式香氛系统开关设置";
CM_ SG_ 1265 ICC_NapSetTemperature "小憩模式设置空调温度";
CM_ SG_ 1265 ICC_SpoilerWelcomeFunSet "电动尾翼迎宾功能设置";
CM_ SG_ 1265 ICC_SpoilerCtrlCmd "电动尾翼控制设置";
CM_ SG_ 1265 ICC_HazardLightReq "双闪灯请求";
CM_ SG_ 1265 ICC_MusicStatus "K歌模式状态";
CM_ SG_ 1265 ICC_CinemaStatus "影院模式状态";
CM_ SG_ 1137 ICC_BookChrgSetReq "预约充电开启/取消设置请求";
CM_ SG_ 1137 ICC_BkChrgStartTimeYear "预约充电开始时间设置-年";
CM_ SG_ 1137 ICC_BkChrgStartTimeDay "预约充电开始时间设置-日";
CM_ SG_ 1137 ICC_BkChrgStartTimeHour "预约充电开始时间设置-时";
CM_ SG_ 1137 ICC_BkChrgStartTimemMin "预约充电开始时间设置-分";
CM_ SG_ 1137 ICC_BkChrgStartTimeMonth "预约充电开始时间设置-月";
CM_ SG_ 1137 ICC_BkChrgDuration "本地预约充电时长设置";
CM_ SG_ 1137 ICC_BkChrgCycleType "本地预约充电周期循环方式";
CM_ SG_ 1137 ICC_StopChrgReq "结束充电请求";
CM_ SG_ 1137 ICC_BkChrgCycleMon "预约充电周期循环_每周一循环";
CM_ SG_ 1137 ICC_BkChrgCycleTues "预约充电周期循环_每周二循环";
CM_ SG_ 1137 ICC_BkChrgCycleWen "预约充电周期循环_每周三循环";
CM_ SG_ 1137 ICC_BkChrgCycleThur "预约充电周期循环_每周四循环";
CM_ SG_ 1137 ICC_BkChrgCycleFri "预约充电周期循环_每周五循环";
CM_ SG_ 1137 ICC_BkChrgCycleSat "预约充电周期循环_每周六循环";
CM_ SG_ 1137 ICC_BkChrgCycleSun "预约充电周期循环_每周日循环";
CM_ SG_ 1137 ICC_KeepWarmStrt "插枪保温开始时间设置-日";
CM_ SG_ 1137 ICC_KeepWarmStrtHour "插枪保温开始时间设置-时";
CM_ SG_ 1137 ICC_KeepWarmStrtMin "插枪保温开始时间设置-分";
CM_ SG_ 1137 ICC_PetmodeFb "宠物模式反馈信号";
CM_ SG_ 1137 ICC_SentinelModeSwitchSts "哨兵开关状态";
CM_ SG_ 1137 ICC_SentinelModeWorkingSts "哨兵工作状态
0x0: NoActive，哨兵模式未进入或未激活
0x1: Active，哨兵模式已进入或激活
0x2: LowSOC 动力电池 电量低
0x3:HVNotReady，高压系统未上电
0x4: HVFault，高压系统故障
0x5: MirrorUnFold，后视镜未展开
0x6: CameraFault，摄像头故障
0x7:LowBatVolt，蓄电池电压低";
CM_ SG_ 1137 ICC_SentinelModeFaultSts "哨兵故障状态（摄像头被遮挡）
0x0:Not Warming
0x1:Artificial occlusion摄像头被人为遮挡
0x2 :Rain and snow cover摄像头被雨雪遮挡";
CM_ SG_ 1137 ICC_SentinelModeAlarmSts "哨兵模式报警状态
0x1: Level 1待命
0x2: Level 2警惕
0x3: Level 3警报";
CM_ SG_ 1137 ICC_SentinelModeExitReason "哨兵模式异常退出原因
0x0: Normal正常
0x1:LowSOC动力电池电量低
0x2:HVNotReady高压系统未上电
0x3:HVFault高压系统故障
0x4:MirrorUnFold后视镜未展开
0x5:CameraFault，摄像头故障
0x6:LowBatVolt蓄电池电压低";
CM_ SG_ 1137 ICC_PetModeWarn "宠物模式异常关闭
0x0:Not Active
0x1:高压电池电量低
0x2:空调异常
0x3:高压异常
0x4:低压电池电量低
0x5:高压电池电量低于15%
0x6:高压电池电量低于12%
0x7:时间过长预警";
CM_ SG_ 1137 ICC_TBOXPetmodeReq "ICC发给TBOX宠物模式激活请求
0x1:ON 激活
0X2:OFF 退出";
CM_ SG_ 1137 ICC_PetModeWarn_2 "宠物模式异常关闭
0x0:Not Active
0x1:高压电池电量低
0x2:空调异常
0x3:高压异常
0x4:低压电池电量低
0x5:高压电池电量低于15%
0x6:高压电池电量低于12%
0x7:时间过长预警
0x8:车辆充电中
0x9:车辆未设防
0xA:车辆档位为非P档";
CM_ SG_ 1137 ICM_FuelLevel "燃油量";
CM_ SG_ 1137 ICM_AverageVehicleSpeed "平均车速 (仪表计算)";
CM_ SG_ 1137 ICM_DistenceToEmpty_Km "燃油续航里程";
CM_ SG_ 1137 ICM_FuelLevelFailSts "燃油故障";
CM_ SG_ 1137 ICM_Maintenance_tips "保养提示（仪表计算，可能上传到平台）";
CM_ SG_ 1137 ICM_SumTrip "小计里程";
CM_ SG_ 1144 ICC_HvBattKeepWarmSet "中控插枪保温开关";
CM_ SG_ 1144 ICC_EnergyRegSet "能量回收强度调节设置";
CM_ SG_ 1144 ICC_HvBattKeepWarmActiveReq "插枪保温开始请求";
CM_ SG_ 1210 ICC_FLSeatHeiCmd "主驾座椅高度调节";
CM_ SG_ 1210 ICC_FLSeatLvlCmd "主驾座椅水平调节";
CM_ SG_ 1210 ICC_FLSeatBackAgCmd "主驾座椅靠背角度调节";
CM_ SG_ 1210 ICC_FLSeatCushCmd "主驾座椅坐垫角度调节";
CM_ SG_ 1210 ICC_FLSeatLegSpprtCmd "主驾座椅腿托调节";
CM_ SG_ 1210 ICC_FRSeatHeiCmd "副驾座椅高度调节";
CM_ SG_ 1210 ICC_FRSeatLvlCmd "副驾座椅水平调节";
CM_ SG_ 1210 ICC_FRSeatBackAgCmd "副驾座椅靠背角度调节";
CM_ SG_ 1210 ICC_FRSeatLegSpprtCmd "副驾座椅腿托调节";
CM_ SG_ 1210 ICC_MemoryRecoveryCmd "ICC记忆保存/恢复指令";
CM_ SG_ 1210 ICC_DeleteFaceID "删除ID";
CM_ SG_ 1210 ICC_FLSeatHeitargetCmd "主驾座椅高度调节目标";
CM_ SG_ 1210 ICC_FLSeatLvltargetCmd "主驾座椅水平调节目标";
CM_ SG_ 1210 ICC_FLSeatBackAgtargetCmd "主驾座椅靠背角度调节目标";
CM_ SG_ 1210 ICC_FLSeatCushtargetCmd "主驾座椅坐垫角度调节目标";
CM_ SG_ 1210 ICC_FLSeatLegSpprttargetCmd "主驾座椅腿托调节目标";
CM_ SG_ 1210 ICC_FRSeatHeitargetCmd "副驾座椅高度调节目标";
CM_ SG_ 1210 ICC_FRSeatLvltargetCmd "副驾座椅水平调节目标";
CM_ SG_ 1210 ICC_FRSeatBackAgtargetCmd "副驾座椅靠背角度调节目标";
CM_ SG_ 1210 ICC_FRSeatLegSpprttargetCmd "副驾座椅腿托调节目标";
CM_ SG_ 1210 ICC_NapFLSeatBackAgtargetSet "小憩模式设置主驾座椅靠背角度调节目标";
CM_ SG_ 1210 ICC_NapFRSeatBackAgtargetSet "小憩模式设置副驾座椅靠背角度调节目标";
CM_ SG_ 1210 ICC_NapFLSeatLvltargetSet "小憩模式设置主驾座椅水平调节目标";
CM_ SG_ 1210 ICC_NapFRSeatLvltargetSet "小憩模式设置副驾座椅水平调节目标";
CM_ SG_ 1210 ICC_FRSeatLegRestAngleCmd "副驾座椅腿托延伸调节";
CM_ SG_ 1210 ICC_FRSeatLegRestAngletargetCmd "副驾座椅腿托延伸调节目标";
CM_ SG_ 1210 ICC_FRSeatCushCmd "副驾座椅坐垫角度调节";
CM_ SG_ 1210 ICC_FRSeatCushtargetCmd "副驾座椅坐垫角度调节目标";
CM_ SG_ 1210 ICC_FRZeroGravitySeatSw "一键副驾零压座椅开关";
CM_ SG_ 1210 ICC_HomeLinkArmHornSet "HomeLink设防鸣笛设置状态";
CM_ SG_ 1210 ICC_HomeLinkWelLightSet "HomeLink迎宾灯设置";
CM_ SG_ 1210 ICC_HomeLinkPositionSts "HomeLink 位置状态";
CM_ SG_ 1210 ICC_WelcomeOpenSetCmd "迎宾灯开启设置";
CM_ SG_ 1210 ICC_WALOpenSetCmd "远离闭锁开关设置";
CM_ SG_ 1210 ICC_UIROpenSetCmd "靠近解锁开关设置";
CM_ SG_ 1210 ICC_EnjoyableSeatSwitch "一键尊享";
CM_ SG_ 1210 ICC_BLTKeyPESet "备注：设置蓝牙钥匙的PE功能ON/OFF状态
0x0：不动作
0x1：PE功能打开
0x2：PE功能关闭";
CM_ SG_ 1210 ICC_FRMemoryDeleteCmd "副驾座椅记忆删除";
CM_ SG_ 1210 ICC_FLSitPosnlocation "主驾座椅记忆设置";
CM_ SG_ 1210 ICC_FRSitPosnlocation "副驾座椅记忆设置";
CM_ SG_ 1210 ICC_FREasyEntryExitSet "副驾便捷进入\离车";
CM_ SG_ 1210 ICC_FRMemoryRecoveryCmd "ICC副驾记忆保存/恢复指令";
CM_ SG_ 1210 ICC_ConsoleAdjustSwitch "副仪表台调节开关
0x0:Not Active
0x1:Lock
0x2:Unlock
0x3:Forward(Reserved)
0x4:Backward(Reserved)
0x5:Delpoy一键最后
0x6:Retract一键最前
0x7:Middle
0x8:Stop";
CM_ SG_ 1399 ICC_CLTC_RangeAval "CLTC工况里程(电)";
CM_ SG_ 1399 ICC_DynamicRangeAval "动态工况里程(电)";
CM_ SG_ 1399 ICC_WLTC_RangeAval "WLTC工况里程(电)";
CM_ SG_ 1399 ICC_CLTC_RangeAvalFuel "CLTC工况里程(燃油)";
CM_ SG_ 1399 ICC_WLTC_RangeAvalFuel "WLTC工况里程(燃油)";
CM_ SG_ 1399 ICC_DynamicRangeAvalFuel "动态工况里程(燃油)";
CM_ SG_ 1399 ICC_CLTC_RangeAvalComp "CLTC工况里程(综合)";
CM_ SG_ 1399 ICC_WLTC_RangeAvalComp "WLTC工况里程(综合)";
CM_ SG_ 1399 ICC_DynamicRangeAvalComp "动态工况里程(综合)";
CM_ SG_ 1399 ICC_Conditiontype "工况类型";
CM_ SG_ 1238 ICC_CFSSwitch "香氛系统开关设置";
CM_ SG_ 1238 ICC_CFSLevelSet "中控屏香氛浓度
0x0:Not_Active
0x1:Level1 淡香
0x2:Level2 清香
0x3:Level3 浓香
0x4~0x7:Reserve";
CM_ SG_ 1238 ICC_CFSPosSet "中控屏香氛类型（位置）";
CM_ SG_ 1238 ICC_PM25Switch "中控屏空气净化开关";
CM_ SG_ 1238 ICC_AQSSwitch "中控屏AQS开关";
CM_ SG_ 1238 ICC_SecSetTemp_C "二排空调温度";
CM_ SG_ 1238 ICC_SecFaceKeySts "Face Key Status
二排吹面按键开关";
CM_ SG_ 1238 ICC_SecFootKeySts "Foot Key Status
二排吹脚按键开关";
CM_ SG_ 1238 ICC_SecBlowSpeedLevelKeySts "Foot Key Status
二排吹脚按键开关";
CM_ SG_ 1238 ICC_SecAutoSwitch "二排空调AUTO开关";
CM_ SG_ 1238 ICC_SecCLMSwitch "二排空调开关";
CM_ SG_ 1238 ICC_ThrSetTemp_C "三排空调温度";
CM_ SG_ 1238 ICC_ThrFaceKeySts "Face Key Status
三排吹面按键开关";
CM_ SG_ 1238 ICC_ThrFootKeySts "Foot Key Status
三排吹脚按键开关";
CM_ SG_ 1238 ICC_ThrBlowSpeedLevelKeySts "Foot Key Status
三排吹脚按键开关";
CM_ SG_ 1238 ICC_ThrAutoSwitch "三排空调AUTO开关";
CM_ SG_ 1238 ICC_ThrCLMSwitch "三排空调开关";
CM_ SG_ 1238 ICC_ThrACRequestKeySts "Set AC Request Status
三排DVD设置AC请求开启";
CM_ SG_ 1238 ICC_DFMSwitch "单席功能开关";
CM_ SG_ 1289 ICC_TirePressureDisplayUnit "胎压显示单位";
CM_ SG_ 1289 ICC_TireTemperatureDisplayUnit "胎温显示单位";
CM_ SG_ 1289 ICC_ToggleUnits "英制单位切换";
CM_ SG_ 1289 ICC_BtConFlag "蓝牙连接状态反馈";
CM_ SG_ 1289 ICC_GPSSwitchSet "GPS定位开关设置";
CM_ SG_ 1167 ICC_KeyDriveModememory "驾驶模式记忆开关";
CM_ SG_ 1167 ICC_DriveModeSet "大屏越野模式设置
0x1：经济
0x2：标准
0x3：运动
0x4：雪/草地
0x5: 泥地
0x6: 越野
0x7: 沙地
0x8: 岩石
0x9: 专家
0xA: 智能
0xB: 涉水
0xC: 极限掉头
0xD: 漂移
0xE: 拖挂
0xF: 越野竞速";
CM_ SG_ 1167 ICC_DRIFTModeSetReq "通过大屏设置漂移模式灵敏度
0x0：不动作
0x1：入门
0x2：大师
0x3：专家";
CM_ SG_ 1167 ICC_EXPERTEIPBESPSet "关闭牵引力控制系统&车身稳定控制系统（TCS&VDC OFF）
全开（TCS、VDC等与ESP有关功能全部开启）
全关（TCS、VDC及RMI放侧翻、DTC发动机拖滞力矩管理）";
CM_ SG_ 1167 ICC_EXPERTEcoSet "专家模式动力设置柔和模式开关";
CM_ SG_ 1167 ICC_EXPERTNormSet "专家模式动力设置标准模式开关";
CM_ SG_ 1167 ICC_EXPERTSportSet "专家模式动力设置激进模式开关";
CM_ SG_ 1167 ICC_CrossaxisSet "专家模式交叉轴模式设置";
CM_ SG_ 1167 ICC_EXPERTRWDSet "专家模式驱动形式后驱设置";
CM_ SG_ 1167 ICC_EXPERTAWDSet "专家模式驱动形式四驱设置";
CM_ SG_ 1167 ICC_EXPERTAutoSet "专家模式驱动形式Auto设置";
CM_ SG_ 1167 ICC_CLIMBSet "防溜设置开关";
CM_ SG_ 1167 ICC_DriveModeExitSet "越野模式退出开关";
CM_ SG_ 1167 ICC_Confidencelevel "x模式的前端地形感知置信度（可靠度）";
CM_ SG_ 1167 ICC_V2L_IntlDisChg "放电记忆开关";
CM_ SG_ 1167 ICC_ExhibitionModeSwitch "展车模式开关";
CM_ SG_ 1167 ICC_TrailerMode "被拖模式开关";
CM_ SG_ 1167 ICC_V2L_DisChgMem "放电记忆开关";
CM_ SG_ 1167 ICC_DrivePowerDispSet "驱动系统功率显示方式开关";
CM_ SG_ 1167 ICC_WLTC_to_CLTC_Mode "驱动系统功率显示方式开关";
CM_ SG_ 1167 ICC_StopChrgnSwitch "驻车发电开关";
CM_ SG_ 1167 ICC_StopChrgnMode "驻车发电模式开关
0x1:静谧补电
0x2:快速补电";
CM_ SG_ 1167 ICC_RegenerateLevelCtrl "能量回馈设置开关
0x0:无效值
0x1:弱
0x2:强
0x3:中
0x4:单踏板";
CM_ SG_ 1167 ICC_SinglePedalMem "单踏板记忆开关";
CM_ SG_ 1167 ICC_FuelDetnSwt "燃油检测开关";
CM_ SG_ 1167 ICC_FuelDetnState "燃油检测模式状态";
CM_ SG_ 1167 ICC_FuelDetnOpDefeated "燃油检测开启失败提示";
CM_ SG_ 1167 ICC_HVDownRepairMode "断高压维修模式开关";
CM_ SG_ 1167 ICC_UTURNSnowSet "极限调头雪地场景开关";
CM_ SG_ 1167 ICC_UTURNSandSet "极限调头泥地场景开关";
CM_ SG_ 1167 ICC_UTURNMudSet "极限调头沙地场景开关";
CM_ SG_ 1167 ICC_UTURNGrassSet "极限调头草地场景开关";
CM_ SG_ 1167 ICC_LTCDispSet2 "续航里程选择开关显示";
CM_ SG_ 1326 ICC_DWDOnOff_Req "涉水雷达开关设置";
CM_ SG_ 1326 ICC_ContainerLightSet "货箱灯开关(D01P）";
CM_ SG_ 1331 ICC_RLSeatEasyEntryExitSet "二排左侧便捷进入\离车";
CM_ SG_ 1331 ICC_RRSeatEasyEntryExitSet "二排右侧便捷进入\离车";
CM_ SG_ 1331 ICC_RLMemoryRecoveryCmd "ICC二排左侧记忆保存/恢复指令";
CM_ SG_ 1331 ICC_RRMemoryRecoveryCmd "ICC二排右侧记忆保存/恢复指令";
CM_ SG_ 1331 ICC_RLSitPosnlocation "二排左侧座椅记忆设置";
CM_ SG_ 1331 ICC_RRSitPosnlocation "二排右侧座椅记忆设置";
CM_ SG_ 1331 ICC_CMSMDisplaySwitch "吸顶屏开关";
CM_ SG_ 1331 ICC_CMSMDisplayAdjustmode "吸顶屏模式调节
0x1:正常角度
0x2:观影角度";
CM_ SG_ 1331 ICC_CMSMSetstandardSwitch "吸顶屏标定开关0x1:标定打开 0x2:标定关闭";
CM_ SG_ 1331 ICC_LeftPedalControl "左边电踏请求（左边电踏软开关展开缩回请求）";
CM_ SG_ 1331 ICC_RightPedalControl "右边电踏请求（右边电踏软开关展开缩回请求）";
CM_ SG_ 1331 ICC_EPCEnable "电踏电动功能模式
0：无效值；
1：电动踏板启用（软开关启用）
2：电动踏板禁用（软开关禁用）";
CM_ SG_ 1331 ICC_AMPKTVvoiceVolumeSet "Amplifier KTV voice volume status
KTV人声音量设定";
CM_ SG_ 1331 ICC_AMPA2BENCSoundReq "Head unit ENC sound request to amplifier
ENC音源需求状态";
CM_ SG_ 1331 ICC_AMPENCVolumeSet "Amplifier ENC volume status
ENC声音量设定";
CM_ SG_ 1331 ICC_AMPA2BChimeSoundReq "Head unit Chime sound request to amplifier
Chime音源需求状态";
CM_ SG_ 1331 Set_AMPSoundFocus_2 "Amplifier sound focus status";
CM_ SG_ 1331 ICC_AMPA2BKTVvoiceSoundReq "Head unit KTV voice/IESS sound request to amplifier
KTV人声/模拟声浪音源需求状态";
CM_ SG_ 1331 ICC_MedStatusSet "冥想模式开关";
CM_ SG_ 1331 Set_AMPLoudness "Amplifier Loudness setting / 响度设定";
CM_ SG_ 1331 ICC_MedAreaSet "冥想模式开启区域设置";
CM_ SG_ 1331 ICC_LeftElectricPedalsSet "左电踏收回和展开软开关（前提自动打开）
0x1:踏板3D软开关开启
0x2:踏板3D软开关关闭";
CM_ SG_ 1331 ICC_RightElectricPedalsSet "右电踏收回和展开软开关（前提自动打开）
0x1:踏板3D软开关开启
0x2:踏板3D软开关关闭";
CM_ SG_ 1331 ICC_NapAreaSet2 "小憩模式开启区域设置2";
CM_ SG_ 1331 ICC_DisplayAdjustrAngReq "微信小程序遥控器控制吸顶屏角度90-110";
CM_ SG_ 1331 Set_AMPKeyVolume "Amplifier Keytone volume setting /设定按键音通道音量设定";
CM_ SG_ 1331 Set_AMPExSoundmode "Amplifier Exsound mode setting / 设定高级音效模式";
CM_ SG_ 1331 Set_AMPA2BENCSound "扬声器位置";
CM_ SG_ 1333 ICC_SRFCmd "天窗开关设置
全开
全关
翘起";
CM_ SG_ 1333 ICC_SRFPercentCmd "手滑动开启天窗百分比";
CM_ SG_ 1333 ICC_CSunshadeReq "天幕遮阳帘开关设置";
CM_ SG_ 1333 ICC_CSunshadePercentReq "手滑动开启天幕遮阳帘百分比";
CM_ SG_ 1333 ICC_SunshadeCmd "遮阳帘开关设置
全开
全关
一半";
CM_ SG_ 1333 ICC_SunshadePercentCmd "手滑动开启遮阳帘百分比";
CM_ SG_ 1335 ICC_SET_EPS_SteerReturnRmdSts "方向盘回正开关";
CM_ SG_ 1335 ICC_SET_MFSShake "方向盘震动开关";
CM_ SG_ 1335 ICC_DMS_1_DistractionLevel "方向盘震动等级调节";
CM_ SG_ 1335 ICC_SET_EPS_AsociWithDrvModSts "EPS与驾驶模式关联开关";
CM_ SG_ 1335 ICC_OverLoadWarnShieldSet "重量报警屏蔽软开关";
CM_ SG_ 1335 ICC_BSWReq "智能擦盘开启信号";
CM_ SG_ 1335 ICC_horizontalReq "露营找平软开关";
CM_ SG_ 1337 ICC_SET_BT_ReduceWindSpeed "大屏设置蓝牙通话降低风速";
CM_ SG_ 1337 ICC_SET_IPM_FirstBlowing "夏日热风规避_大屏设置空调启动时第一口风";
CM_ SG_ 1337 ICC_SET_IPM_BlowerDelay "大屏设置车辆熄火空调鼓风机延时";
CM_ SG_ 1337 ICC_SET_CirculationInTunnels "大屏设置隧道内循环";
CM_ SG_ 1337 ICC_UVCLuminanceReq "大屏设置紫外线杀菌灯强度请求";
CM_ SG_ 1337 ICC_UVCControlReq "大屏设置紫外线杀菌灯";
CM_ SG_ 1337 ICC_CrossCountryCoolingReq "越野散热开关";
CM_ SG_ 1337 ICC_KeepWarmReq "恒温模式状态开关请求";
CM_ SG_ 1337 ICC_keepwarmSetTemperatureReq "恒温模式温度设置请求";
CM_ SG_ 1337 ICC_ParkingAirConditioning "驻车空调使能开关
ventilate通风";
CM_ SG_ 1337 ICC_CoolantFill_Req "冷却液加注开关请求";
CM_ SG_ 1337 ICC_FraganceLightoffReq "香氛氛围灯开关状态";
CM_ SG_ 1337 ICC_FraganceMemoffReq "香氛记忆开关状态";
CM_ SG_ 1337 ICC_AirPurgeReminderReq "空气净化提醒开关请求";
CM_ SG_ 1337 ICC_CFSCycleLevel "香氛循环等级";
CM_ SG_ 1337 ICC_TimingLevel "香氛定时等级";
CM_ SG_ 1337 ICC_ModeAdjustDisplaySts "空调模式";
CM_ SG_ 1337 ICC_BiochemicalFuncReq "大屏生化功能开关";
CM_ SG_ 1337 ICC_TimedVentilationReq "大屏定时换气功能开关";
CM_ SG_ 1337 ICC_PetmodeSetTemperature_L_C "宠物模式前左空调温度设置";
CM_ SG_ 1337 ICC_PetModeSetTemperature_R_C "宠物模式前右空调温度设置";
CM_ SG_ 1337 ICC_PetModeSetCLMOn "宠物模式空调开关设置";
CM_ SG_ 1337 ICC_PetModeSetAutoKeySts "宠物模式空调自动模式设置";
CM_ SG_ 1337 ICC_PetModeSetCirculationSts "宠物模式空调内外循环切换设置";
CM_ SG_ 1318 ICC_SET_TDL_Rhythm_Switch "氛围灯律动开关";
CM_ SG_ 1318 ICC_SET_TDL_Switch "氛围灯开关";
CM_ SG_ 1318 ICC_SET_TDL_ColourModeAdj "氛围灯颜色模式调节

Monochrome_单色
panchromatic为全色
FLZCU_TDL";
CM_ SG_ 1318 ICC_VoiceWake "语音唤醒";
CM_ SG_ 1318 ICC_TDL_RhythmReq "音乐律动模式调节";
CM_ SG_ 1318 ICC_SET_ApiluminanceAdj "氛围灯亮度调节
氛围灯亮度_Level1最暗_Level8最亮FLZCU_TDL";
CM_ SG_ 1318 ICC_SET_MusicLoudness_120HZ "均衡器设置";
CM_ SG_ 1318 ICC_SET_MusicLoudness_250HZ "均衡器设置";
CM_ SG_ 1318 ICC_SET_MusicLoudness_500HZ "均衡器设置";
CM_ SG_ 1318 ICC_SET_MusicLoudness_1000HZ "均衡器设置";
CM_ SG_ 1318 ICC_SET_MusicLoudness_1500HZ "均衡器设置";
CM_ SG_ 1318 ICC_SET_MusicLoudness_2000HZ "均衡器设置";
CM_ SG_ 1318 ICC_SET_MusicLoudness_6000HZ "均衡器设置";
CM_ SG_ 1318 ICC_TDL_FlowLightSw "流水灯开关";
CM_ SG_ 1318 ICC_TDL_FlowLightModeAdj "流水灯模式调节";
CM_ SG_ 1318 ICC_SET_256ColourAdj "多元颜色设置（256色）";
CM_ SG_ 1320 ICC_Chb_Req "冰箱开关请求";
CM_ SG_ 1320 ICC_ChbMem_Req "记忆开关请求";
CM_ SG_ 1320 ICC_ChbDelay_Req "延时开关请求";
CM_ SG_ 1320 ICC_ChbSterilization_Req "杀菌开关请求";
CM_ SG_ 1320 ICC_ChbItemsLeft_Req "物品遗留开关请求";
CM_ SG_ 1320 ICC_ParkingRadarSwSet "驻车雷达开关请求";
CM_ SG_ 1320 ICC_ChbTimeset_Req "延时时间设置请求";
CM_ SG_ 1320 ICC_ChbCoolset_Req "制冷温度设置
0x1~0xD:-6℃~6℃（捷途使用）
0xE~0x19:-18℃~-7℃（股份使用，捷途预留）";
CM_ SG_ 1320 ICC_ChbCoolorheat_Req "制冷制热开关请求";
CM_ SG_ 1320 ICC_ChbHeatset_Req "制热温度调节设置请求";
CM_ SG_ 1360 ICC_XDriveMode "ICC通过视频流发给VCU进行驾驶模式设置
0x0:Not Active
0x1:无法判断 unidentifiable
0x2:普通1 Normal
0x3:雪地1 SNOW
0x4:泥地1 MUD
0x5:岩石1 ROCK
0x6:沙地1 SAND
0x7:水面1 WATER SURFACE
0x8：普通2 Normal
0x9:雪地2 SNOW
0xA:泥地2 MUD
0xB: 岩石2 ROCK
0xC:沙地2 SAND
0xD:水面2 WATER SURFACE
0xE:普通3 Normal
0xF:雪地3 SNOW
0x10:泥地3 MUD
0x11:岩石3 ROCK
0x12:沙地3 SAND";
CM_ SG_ 1360 ICC_LISD_DisplaySwitch "自定义图片实时显示功能开关";
CM_ SG_ 1360 ICC_LISD_ParkingShowCMD "驻车动画开关（反馈已有）";
CM_ SG_ 1360 ICC_RoofCampLampSetL "左侧露营射灯软开关（选装）";
CM_ SG_ 1360 ICC_RISD_DisplaySwitch "自定义图片实时显示功能开关";
CM_ SG_ 1360 ICC_RISD_ParkingShowCMD "驻车动画开关（反馈已有）";
CM_ SG_ 1360 ICC_RoofCampLampSetR "右侧露营射灯软开关（选装）";
CM_ SG_ 1360 ICC_LogoParkingReq "前LOGO驻车点亮开关请求";
CM_ SG_ 1360 ICC_LogoChargingReq "前LOGO充电灯效开关请求";
CM_ SG_ 1360 ICC_DRLSw "日间行车灯软开关";
CM_ SG_ 1360 ICC_TopLightSet "车顶射灯软开关（选装）";
CM_ SG_ 1360 ICC_APillarYellowAmbientSet "A柱黄色氛围灯软开关（选装）";
CM_ SG_ 1360 ICC_APillarWhiteAmbientSet "A柱白色氛围灯软开关（选装）";
CM_ SG_ 1360 ICC_LISD_ParkingShowMod "LISD驻车动画模式";
CM_ SG_ 1360 ICC_RISD_ParkingShowMod "RISD驻车动画模式";
CM_ SG_ 1360 ICC_APillarSpotLampSet "A柱射灯软开关（选装）";
CM_ SG_ 1360 ICC_PenetrationLampSetF "前贯穿灯软开关(D01P使用)";
CM_ SG_ 1360 ICC_MusicLampShowSW "0x0: 灯光秀总开关关闭
0x1: 灯光秀总开关开启";
CM_ SG_ 1360 ICC_LogoColorReq "Logo灯颜色设置，1-256分别对应256种颜色";
BA_DEF_ BO_  "GenMsgCycleTimeFast" INT 0 50000;
BA_DEF_ BO_  "GenMsgNrOfRepetition" INT 0 999999;
BA_DEF_ BO_  "GenMsgDelayTime" INT 0 1000;
BA_DEF_ BO_  "VFrameFormat" ENUM  "StandardCAN","ExtendedCAN","reserved","reserved","reserved","reserved","reserved","reserved","reserved","reserved","reserved","reserved","reserved","reserved","StandardCAN_FD","ExtendedCAN_FD";
BA_DEF_ BO_  "GenMsgILSupport" ENUM  "No","Yes";
BA_DEF_ BO_  "NmMessage" ENUM  "No","Yes";
BA_DEF_ BO_  "GenMsgSendType" ENUM  "Cycle","Event","IfActive","CE","CA","NoMsgSendType";
BA_DEF_ BO_  "GenMsgCycleTime" INT 0 50000;
BA_DEF_ BO_  "CANFD_BRS" INT 0 1;
BA_DEF_ BO_  "NmAsrMessage" ENUM  "No","Yes";
BA_DEF_ BO_  "GRC_ASIL" ENUM  "vector_leerstring","QM","A","B","C","D";
BA_DEF_ BO_  "GRC_History" STRING ;
BA_DEF_ SG_  "GenSigStartValue" FLOAT 0 100000000000;
BA_DEF_ SG_  "GenSigInactiveValue" INT 0 100000;
BA_DEF_ SG_  "GenSigInvalidValue" INT 0 100000000;
BA_DEF_ SG_  "GenSigSendType" ENUM  "Cycle","OnChange","OnWrite","IfActive","OnChangeWithRepetition","OnWriteWithRepetition","IfActiveWithRepetition","NoSigSendType","OnChangeAndIfActive","OnChangeAndIfActiveWithRepetition","CA","CE","Event";
BA_DEF_ SG_  "GRC_Sig_ASIL" ENUM  "vector_leerstring","QM","A","B","C","D";
BA_DEF_ SG_  "E2EDataId" INT 0 0;
BA_DEF_ SG_  "E2EProfile" STRING ;
BA_DEF_ SG_  "E2EDataLength" INT 0 512;
BA_DEF_DEF_  "GenMsgCycleTimeFast" 0;
BA_DEF_DEF_  "GenMsgNrOfRepetition" 0;
BA_DEF_DEF_  "GenMsgDelayTime" 0;
BA_DEF_DEF_  "VFrameFormat" "StandardCAN";
BA_DEF_DEF_  "GenMsgILSupport" "No";
BA_DEF_DEF_  "NmMessage" "No";
BA_DEF_DEF_  "GenMsgSendType" "NoMsgSendType";
BA_DEF_DEF_  "GenMsgCycleTime" 0;
BA_DEF_DEF_  "CANFD_BRS" 0;
BA_DEF_DEF_  "NmAsrMessage" "No";
BA_DEF_DEF_  "GRC_ASIL" "";
BA_DEF_DEF_  "GRC_History" "";
BA_DEF_DEF_  "GenSigStartValue" 0;
BA_DEF_DEF_  "GenSigInactiveValue" 0;
BA_DEF_DEF_  "GenSigInvalidValue" 0;
BA_DEF_DEF_  "GenSigSendType" "NoSigSendType";
BA_DEF_DEF_  "GRC_Sig_ASIL" "";
BA_DEF_DEF_  "E2EDataId" 0;
BA_DEF_DEF_  "E2EProfile" "";
BA_DEF_DEF_  "E2EDataLength" 0;
BA_ "CANFD_BRS" BO_ 1254 1;
BA_ "GenMsgSendType" BO_ 1254 0;
BA_ "GenMsgCycleTime" BO_ 1254 100;
BA_ "GenMsgCycleTimeFast" BO_ 1254 50;
BA_ "GenMsgNrOfRepetition" BO_ 1254 2;
BA_ "GenMsgDelayTime" BO_ 1254 5;
BA_ "GenMsgILSupport" BO_ 1254 1;
BA_ "VFrameFormat" BO_ 1254 14;
BA_ "CANFD_BRS" BO_ 1296 1;
BA_ "GenMsgSendType" BO_ 1296 0;
BA_ "GenMsgCycleTime" BO_ 1296 500;
BA_ "GenMsgILSupport" BO_ 1296 1;
BA_ "VFrameFormat" BO_ 1296 14;
BA_ "CANFD_BRS" BO_ 1447 1;
BA_ "GenMsgSendType" BO_ 1447 0;
BA_ "GenMsgCycleTime" BO_ 1447 500;
BA_ "GenMsgILSupport" BO_ 1447 1;
BA_ "VFrameFormat" BO_ 1447 14;
BA_ "CANFD_BRS" BO_ 1100 1;
BA_ "GenMsgSendType" BO_ 1100 1;
BA_ "GenMsgCycleTimeFast" BO_ 1100 100;
BA_ "GenMsgNrOfRepetition" BO_ 1100 2;
BA_ "GenMsgDelayTime" BO_ 1100 5;
BA_ "GenMsgILSupport" BO_ 1100 1;
BA_ "VFrameFormat" BO_ 1100 14;
BA_ "CANFD_BRS" BO_ 1119 1;
BA_ "GenMsgSendType" BO_ 1119 1;
BA_ "GenMsgCycleTimeFast" BO_ 1119 100;
BA_ "GenMsgNrOfRepetition" BO_ 1119 2;
BA_ "GenMsgDelayTime" BO_ 1119 5;
BA_ "GenMsgILSupport" BO_ 1119 1;
BA_ "VFrameFormat" BO_ 1119 14;
BA_ "CANFD_BRS" BO_ 1150 1;
BA_ "GenMsgSendType" BO_ 1150 3;
BA_ "GenMsgCycleTime" BO_ 1150 100;
BA_ "GenMsgCycleTimeFast" BO_ 1150 50;
BA_ "GenMsgNrOfRepetition" BO_ 1150 2;
BA_ "GenMsgDelayTime" BO_ 1150 5;
BA_ "GenMsgILSupport" BO_ 1150 1;
BA_ "GRC_ASIL" BO_ 1150 2;
BA_ "VFrameFormat" BO_ 1150 14;
BA_ "CANFD_BRS" BO_ 917 1;
BA_ "GenMsgSendType" BO_ 917 0;
BA_ "GenMsgCycleTime" BO_ 917 50;
BA_ "GenMsgILSupport" BO_ 917 1;
BA_ "VFrameFormat" BO_ 917 14;
BA_ "CANFD_BRS" BO_ 1273 1;
BA_ "GenMsgSendType" BO_ 1273 1;
BA_ "GenMsgCycleTimeFast" BO_ 1273 100;
BA_ "GenMsgNrOfRepetition" BO_ 1273 2;
BA_ "GenMsgDelayTime" BO_ 1273 5;
BA_ "GenMsgILSupport" BO_ 1273 1;
BA_ "VFrameFormat" BO_ 1273 14;
BA_ "CANFD_BRS" BO_ 1157 1;
BA_ "GenMsgSendType" BO_ 1157 3;
BA_ "GenMsgCycleTime" BO_ 1157 100;
BA_ "GenMsgCycleTimeFast" BO_ 1157 50;
BA_ "GenMsgNrOfRepetition" BO_ 1157 2;
BA_ "GenMsgDelayTime" BO_ 1157 5;
BA_ "GenMsgILSupport" BO_ 1157 1;
BA_ "GRC_ASIL" BO_ 1157 3;
BA_ "VFrameFormat" BO_ 1157 14;
BA_ "CANFD_BRS" BO_ 1279 1;
BA_ "GenMsgSendType" BO_ 1279 3;
BA_ "GenMsgCycleTime" BO_ 1279 100;
BA_ "GenMsgCycleTimeFast" BO_ 1279 50;
BA_ "GenMsgNrOfRepetition" BO_ 1279 2;
BA_ "GenMsgDelayTime" BO_ 1279 5;
BA_ "GenMsgILSupport" BO_ 1279 1;
BA_ "VFrameFormat" BO_ 1279 14;
BA_ "CANFD_BRS" BO_ 644 1;
BA_ "GenMsgSendType" BO_ 644 0;
BA_ "GenMsgCycleTime" BO_ 644 20;
BA_ "GenMsgILSupport" BO_ 644 1;
BA_ "VFrameFormat" BO_ 644 14;
BA_ "CANFD_BRS" BO_ 1174 1;
BA_ "GenMsgSendType" BO_ 1174 3;
BA_ "GenMsgCycleTime" BO_ 1174 100;
BA_ "GenMsgCycleTimeFast" BO_ 1174 50;
BA_ "GenMsgNrOfRepetition" BO_ 1174 2;
BA_ "GenMsgDelayTime" BO_ 1174 5;
BA_ "GenMsgILSupport" BO_ 1174 1;
BA_ "VFrameFormat" BO_ 1174 14;
BA_ "CANFD_BRS" BO_ 1242 1;
BA_ "GenMsgSendType" BO_ 1242 1;
BA_ "GenMsgDelayTime" BO_ 1242 5;
BA_ "GenMsgILSupport" BO_ 1242 1;
BA_ "VFrameFormat" BO_ 1242 14;
BA_ "CANFD_BRS" BO_ 1276 1;
BA_ "GenMsgSendType" BO_ 1276 0;
BA_ "GenMsgCycleTime" BO_ 1276 100;
BA_ "GenMsgCycleTimeFast" BO_ 1276 50;
BA_ "GenMsgNrOfRepetition" BO_ 1276 2;
BA_ "GenMsgDelayTime" BO_ 1276 5;
BA_ "GenMsgILSupport" BO_ 1276 1;
BA_ "VFrameFormat" BO_ 1276 14;
BA_ "CANFD_BRS" BO_ 1059 1;
BA_ "GenMsgSendType" BO_ 1059 0;
BA_ "GenMsgCycleTime" BO_ 1059 100;
BA_ "GenMsgCycleTimeFast" BO_ 1059 100;
BA_ "GenMsgNrOfRepetition" BO_ 1059 2;
BA_ "GenMsgDelayTime" BO_ 1059 5;
BA_ "GenMsgILSupport" BO_ 1059 1;
BA_ "VFrameFormat" BO_ 1059 14;
BA_ "CANFD_BRS" BO_ 1105 1;
BA_ "GenMsgSendType" BO_ 1105 0;
BA_ "GenMsgCycleTime" BO_ 1105 100;
BA_ "GenMsgCycleTimeFast" BO_ 1105 100;
BA_ "GenMsgNrOfRepetition" BO_ 1105 2;
BA_ "GenMsgDelayTime" BO_ 1105 5;
BA_ "GenMsgILSupport" BO_ 1105 1;
BA_ "VFrameFormat" BO_ 1105 14;
BA_ "CANFD_BRS" BO_ 1056 1;
BA_ "GenMsgSendType" BO_ 1056 3;
BA_ "GenMsgCycleTime" BO_ 1056 100;
BA_ "GenMsgCycleTimeFast" BO_ 1056 100;
BA_ "GenMsgNrOfRepetition" BO_ 1056 2;
BA_ "GenMsgDelayTime" BO_ 1056 5;
BA_ "GenMsgILSupport" BO_ 1056 1;
BA_ "VFrameFormat" BO_ 1056 14;
BA_ "CANFD_BRS" BO_ 1112 1;
BA_ "GenMsgSendType" BO_ 1112 0;
BA_ "GenMsgCycleTime" BO_ 1112 100;
BA_ "GenMsgCycleTimeFast" BO_ 1112 100;
BA_ "GenMsgNrOfRepetition" BO_ 1112 2;
BA_ "GenMsgDelayTime" BO_ 1112 5;
BA_ "GenMsgILSupport" BO_ 1112 1;
BA_ "VFrameFormat" BO_ 1112 14;
BA_ "CANFD_BRS" BO_ 1265 1;
BA_ "GenMsgSendType" BO_ 1265 3;
BA_ "GenMsgCycleTime" BO_ 1265 100;
BA_ "GenMsgCycleTimeFast" BO_ 1265 100;
BA_ "GenMsgNrOfRepetition" BO_ 1265 2;
BA_ "GenMsgDelayTime" BO_ 1265 5;
BA_ "GenMsgILSupport" BO_ 1265 1;
BA_ "VFrameFormat" BO_ 1265 14;
BA_ "CANFD_BRS" BO_ 1137 1;
BA_ "GenMsgSendType" BO_ 1137 3;
BA_ "GenMsgCycleTime" BO_ 1137 100;
BA_ "GenMsgCycleTimeFast" BO_ 1137 100;
BA_ "GenMsgNrOfRepetition" BO_ 1137 2;
BA_ "GenMsgDelayTime" BO_ 1137 5;
BA_ "GenMsgILSupport" BO_ 1137 1;
BA_ "VFrameFormat" BO_ 1137 14;
BA_ "CANFD_BRS" BO_ 1144 1;
BA_ "GenMsgSendType" BO_ 1144 0;
BA_ "GenMsgCycleTime" BO_ 1144 100;
BA_ "GenMsgCycleTimeFast" BO_ 1144 100;
BA_ "GenMsgNrOfRepetition" BO_ 1144 2;
BA_ "GenMsgDelayTime" BO_ 1144 5;
BA_ "GenMsgILSupport" BO_ 1144 1;
BA_ "VFrameFormat" BO_ 1144 14;
BA_ "CANFD_BRS" BO_ 1210 1;
BA_ "GenMsgSendType" BO_ 1210 3;
BA_ "GenMsgCycleTime" BO_ 1210 100;
BA_ "GenMsgCycleTimeFast" BO_ 1210 100;
BA_ "GenMsgNrOfRepetition" BO_ 1210 2;
BA_ "GenMsgDelayTime" BO_ 1210 5;
BA_ "GenMsgILSupport" BO_ 1210 1;
BA_ "VFrameFormat" BO_ 1210 14;
BA_ "CANFD_BRS" BO_ 1399 1;
BA_ "GenMsgSendType" BO_ 1399 0;
BA_ "GenMsgCycleTime" BO_ 1399 1000;
BA_ "GenMsgILSupport" BO_ 1399 1;
BA_ "VFrameFormat" BO_ 1399 14;
BA_ "CANFD_BRS" BO_ 1238 1;
BA_ "GenMsgSendType" BO_ 1238 0;
BA_ "GenMsgCycleTime" BO_ 1238 100;
BA_ "GenMsgCycleTimeFast" BO_ 1238 50;
BA_ "GenMsgNrOfRepetition" BO_ 1238 2;
BA_ "GenMsgDelayTime" BO_ 1238 5;
BA_ "GenMsgILSupport" BO_ 1238 1;
BA_ "VFrameFormat" BO_ 1238 14;
BA_ "CANFD_BRS" BO_ 1289 1;
BA_ "GenMsgSendType" BO_ 1289 0;
BA_ "GenMsgCycleTime" BO_ 1289 500;
BA_ "GenMsgILSupport" BO_ 1289 1;
BA_ "GRC_History" BO_ 1289 "[{'approvedBy':'贾少辉','author':'吴慧','changesComments':'（同步D01更改）刘标ICC新增发送：GPS定位开启和关闭设置ICC_GPSSwitchSet信号，TBOX接收','date':'2025/4/8','ecu':'ICC_34(0x509)','ecuName':'ICC','reviewedBy':'杨华','revision':'V1.2'}]";
BA_ "VFrameFormat" BO_ 1289 14;
BA_ "CANFD_BRS" BO_ 1167 1;
BA_ "GenMsgSendType" BO_ 1167 1;
BA_ "GenMsgCycleTimeFast" BO_ 1167 50;
BA_ "GenMsgNrOfRepetition" BO_ 1167 2;
BA_ "GenMsgDelayTime" BO_ 1167 5;
BA_ "GenMsgILSupport" BO_ 1167 1;
BA_ "VFrameFormat" BO_ 1167 14;
BA_ "CANFD_BRS" BO_ 1326 1;
BA_ "GenMsgSendType" BO_ 1326 1;
BA_ "GenMsgCycleTimeFast" BO_ 1326 100;
BA_ "GenMsgNrOfRepetition" BO_ 1326 2;
BA_ "GenMsgDelayTime" BO_ 1326 5;
BA_ "GenMsgILSupport" BO_ 1326 1;
BA_ "VFrameFormat" BO_ 1326 14;
BA_ "CANFD_BRS" BO_ 1331 1;
BA_ "GenMsgSendType" BO_ 1331 1;
BA_ "GenMsgCycleTimeFast" BO_ 1331 100;
BA_ "GenMsgNrOfRepetition" BO_ 1331 2;
BA_ "GenMsgDelayTime" BO_ 1331 5;
BA_ "GenMsgILSupport" BO_ 1331 1;
BA_ "GRC_History" BO_ 1331 "[{'approvedBy':'贾少辉','author':'吴慧','changesComments':'姜新ICC新增发送Set_AMPLoudness和Set_AMPKeyVolume和Set_AMPExSoundmode和Set_AMPA2BENCSound信号，EAMP接收','date':'2025/4/15','ecu':'ICC_IC_37(0x533)','ecuName':'ICC,EAMP','reviewedBy':'杨华','revis";
BA_ "VFrameFormat" BO_ 1331 14;
BA_ "CANFD_BRS" BO_ 1333 1;
BA_ "GenMsgSendType" BO_ 1333 1;
BA_ "GenMsgCycleTimeFast" BO_ 1333 100;
BA_ "GenMsgNrOfRepetition" BO_ 1333 2;
BA_ "GenMsgDelayTime" BO_ 1333 5;
BA_ "GenMsgILSupport" BO_ 1333 1;
BA_ "VFrameFormat" BO_ 1333 14;
BA_ "CANFD_BRS" BO_ 1335 1;
BA_ "GenMsgSendType" BO_ 1335 0;
BA_ "GenMsgCycleTime" BO_ 1335 100;
BA_ "GenMsgCycleTimeFast" BO_ 1335 20;
BA_ "GenMsgNrOfRepetition" BO_ 1335 2;
BA_ "GenMsgDelayTime" BO_ 1335 5;
BA_ "GenMsgILSupport" BO_ 1335 1;
BA_ "GRC_History" BO_ 1335 "[{'approvedBy':'贾少辉','author':'吴慧','changesComments':'姜新ICC新增ICC_SET_EPS_AsociWithDrvModSts信号','date':'2025/1/17','ecu':'ICC_CH_39(0x537)','ecuName':'ICC','reviewedBy':'杨华','revision':'V1.0'}]";
BA_ "VFrameFormat" BO_ 1335 14;
BA_ "CANFD_BRS" BO_ 1337 1;
BA_ "GenMsgSendType" BO_ 1337 1;
BA_ "GenMsgCycleTimeFast" BO_ 1337 100;
BA_ "GenMsgNrOfRepetition" BO_ 1337 2;
BA_ "GenMsgDelayTime" BO_ 1337 5;
BA_ "GenMsgILSupport" BO_ 1337 1;
BA_ "GRC_History" BO_ 1337 "[{'approvedBy':'贾少辉','author':'吴慧','changesComments':'姜新ICC新增ICC_CFSCycleLevel和ICC_TimingLevel和ICC_ModeAdjustDisplaySts信号，TMS接收','date':'2025/1/17','ecu':'ICC_TMS_40(0x539)','ecuName':'ICC','reviewedBy':'杨华','revision':'V1.0'},{'approve";
BA_ "VFrameFormat" BO_ 1337 14;
BA_ "CANFD_BRS" BO_ 1318 1;
BA_ "GenMsgSendType" BO_ 1318 3;
BA_ "GenMsgCycleTime" BO_ 1318 100;
BA_ "GenMsgCycleTimeFast" BO_ 1318 100;
BA_ "GenMsgNrOfRepetition" BO_ 1318 2;
BA_ "GenMsgDelayTime" BO_ 1318 5;
BA_ "GenMsgILSupport" BO_ 1318 1;
BA_ "GRC_History" BO_ 1318 "[{'approvedBy':'贾少辉','author':'吴慧','changesComments':'D01项目刘标ICC需求修改，同步修改：ICC_SET_256ColourAdj初始值由0x1改为0xA，无效值填写为0x7F，对应实际色号','date':'2025/3/4','ecu':'ICC_TDL_41(0x526)','ecuName':'ICC,FLZCU','reviewedBy':'杨华','re";
BA_ "VFrameFormat" BO_ 1318 14;
BA_ "CANFD_BRS" BO_ 1320 1;
BA_ "GenMsgSendType" BO_ 1320 1;
BA_ "GenMsgCycleTimeFast" BO_ 1320 100;
BA_ "GenMsgNrOfRepetition" BO_ 1320 2;
BA_ "GenMsgDelayTime" BO_ 1320 5;
BA_ "GenMsgILSupport" BO_ 1320 1;
BA_ "VFrameFormat" BO_ 1320 14;
BA_ "CANFD_BRS" BO_ 1360 1;
BA_ "GenMsgSendType" BO_ 1360 0;
BA_ "GenMsgCycleTime" BO_ 1360 100;
BA_ "GenMsgCycleTimeFast" BO_ 1360 100;
BA_ "GenMsgNrOfRepetition" BO_ 1360 2;
BA_ "GenMsgDelayTime" BO_ 1360 5;
BA_ "GenMsgILSupport" BO_ 1360 1;
BA_ "VFrameFormat" BO_ 1360 14;
BA_ "GenSigSendType" SG_ 1254 ICC_WelcomeOpenSet 5;
BA_ "GenSigSendType" SG_ 1254 ICC_WALOpenSet 5;
BA_ "GenSigSendType" SG_ 1254 ICC_EasytrunkSet 5;
BA_ "GenSigSendType" SG_ 1254 ICC_UIROpenSet 5;
BA_ "GenSigSendType" SG_ 1254 ICC_BeanIDReq 5;
BA_ "GenSigSendType" SG_ 1254 ICC_CWCWorkingStsSet 5;
BA_ "GenSigInvalidValue" SG_ 1254 ICC_CWCWorkingStsSet 3;
BA_ "GenSigStartValue" SG_ 1254 ICC_CWCWorkingStsSet 3;
BA_ "GenSigSendType" SG_ 1254 ICC_CWCPhoneforgottenFunStsSet 5;
BA_ "GenSigInvalidValue" SG_ 1254 ICC_CWCPhoneforgottenFunStsSet 3;
BA_ "GenSigStartValue" SG_ 1254 ICC_CWCPhoneforgottenFunStsSet 3;
BA_ "GenSigSendType" SG_ 1254 ICC_RCWCWorkingStsSet 5;
BA_ "GenSigInvalidValue" SG_ 1254 ICC_RCWCWorkingStsSet 3;
BA_ "GenSigStartValue" SG_ 1254 ICC_RCWCWorkingStsSet 3;
BA_ "GenSigSendType" SG_ 1254 ICC_RCWCPhoneforgottenFunStsSet 5;
BA_ "GenSigInvalidValue" SG_ 1254 ICC_RCWCPhoneforgottenFunStsSet 3;
BA_ "GenSigStartValue" SG_ 1254 ICC_RCWCPhoneforgottenFunStsSet 3;
BA_ "GenSigSendType" SG_ 1296 CurrentTimeYear 0;
BA_ "GenSigSendType" SG_ 1296 CurrentTimeMonth 0;
BA_ "GenSigStartValue" SG_ 1296 CurrentTimeMonth 1;
BA_ "GenSigSendType" SG_ 1296 CurrentTimeDay 0;
BA_ "GenSigStartValue" SG_ 1296 CurrentTimeDay 1;
BA_ "GenSigSendType" SG_ 1296 CurrentTimeHour 0;
BA_ "GenSigSendType" SG_ 1296 CurrentTimeMinute 0;
BA_ "GenSigSendType" SG_ 1296 CurrentTimeSecond 0;
BA_ "GenSigSendType" SG_ 1447 CurrentTimeYear_UTC 0;
BA_ "GenSigSendType" SG_ 1447 CurrentTimeMonth_UTC 0;
BA_ "GenSigStartValue" SG_ 1447 CurrentTimeMonth_UTC 1;
BA_ "GenSigSendType" SG_ 1447 CurrentTimeDay_UTC 0;
BA_ "GenSigStartValue" SG_ 1447 CurrentTimeDay_UTC 1;
BA_ "GenSigSendType" SG_ 1447 CurrentTimeHour_UTC 0;
BA_ "GenSigSendType" SG_ 1447 CurrentTimeMinute_UTC 0;
BA_ "GenSigSendType" SG_ 1447 CurrentTimeSecond_UTC 0;
BA_ "GenSigSendType" SG_ 1100 Set_AMPNaviVolume 5;
BA_ "GenSigSendType" SG_ 1100 Set_AMPVRVolume 5;
BA_ "GenSigSendType" SG_ 1100 Set_AMPKeyTone 5;
BA_ "GenSigSendType" SG_ 1100 Set_AMPMediaVolume 5;
BA_ "GenSigSendType" SG_ 1100 Set_AMPPhoneVolume 5;
BA_ "GenSigSendType" SG_ 1100 Set_AMPSoundFocus 5;
BA_ "GenSigSendType" SG_ 1100 Set_AMPSoundEffect 5;
BA_ "GenSigSendType" SG_ 1100 Set_AMPSoundEffectBass 5;
BA_ "GenSigSendType" SG_ 1100 Set_AMPSoundEffectMidrange 5;
BA_ "GenSigSendType" SG_ 1100 Set_AMPSoundEffectTreble 5;
BA_ "GenSigSendType" SG_ 1100 Set_AMPSoundFieldBalance 5;
BA_ "GenSigSendType" SG_ 1100 Set_AMPSoundFieldFader 5;
BA_ "GenSigSendType" SG_ 1100 Set_Headrest_Mode 5;
BA_ "GenSigSendType" SG_ 1100 Set_SurndFnOnOff 5;
BA_ "GenSigSendType" SG_ 1100 Set_VirtualSbwfrOnOff 5;
BA_ "GenSigSendType" SG_ 1119 Set_AMPMediaDuck 5;
BA_ "GenSigSendType" SG_ 1119 Set_AMPSpeedVolume 5;
BA_ "GenSigSendType" SG_ 1119 Set_AMPMute 5;
BA_ "GenSigSendType" SG_ 1119 REQ_AMPA2BMediaSound 5;
BA_ "GenSigSendType" SG_ 1119 REQ_AMPA2BNaviSound 5;
BA_ "GenSigSendType" SG_ 1119 REQ_AMPA2BVRSound 5;
BA_ "GenSigSendType" SG_ 1119 REQ_AMPA2BTTSSound 5;
BA_ "GenSigSendType" SG_ 1119 REQ_AMPA2BKeyTone 5;
BA_ "GenSigSendType" SG_ 1119 Set_AMPRestoreDefaults 5;
BA_ "GenSigSendType" SG_ 1119 Set_AMPAlarmVolume 5;
BA_ "GenSigSendType" SG_ 1119 REQ_AMPA2BPhoneSound 5;
BA_ "GenSigSendType" SG_ 1119 Set_AMPSoundEffectMegaBass 5;
BA_ "GenSigSendType" SG_ 1119 Set_AMPSoundEffectMidBass 5;
BA_ "GenSigSendType" SG_ 1119 Set_AMPSoundEffectMidTreble 5;
BA_ "GenSigSendType" SG_ 1119 Set_AMPBackgroundVolume 5;
BA_ "GenSigSendType" SG_ 1119 Set_AMPSoundBypass 5;
BA_ "GenSigSendType" SG_ 1119 Set_AMPA2BConfig 5;
BA_ "GenSigSendType" SG_ 1150 Fusa_47E_3 4;
BA_ "GenSigSendType" SG_ 1150 Fusa_47E_2 4;
BA_ "GenSigSendType" SG_ 1150 Fusa_47E_1 4;
BA_ "GenSigSendType" SG_ 1150 ICC_BD_11_CRC 5;
BA_ "E2EDataId" SG_ 1150 ICC_BD_11_CRC 158;
BA_ "E2EProfile" SG_ 1150 ICC_BD_11_CRC "P01";
BA_ "E2EDataLength" SG_ 1150 ICC_BD_11_CRC 64;
BA_ "GenSigSendType" SG_ 1150 ICC_BD_11_RollgCntr 5;
BA_ "E2EDataId" SG_ 1150 ICC_BD_11_RollgCntr 158;
BA_ "E2EProfile" SG_ 1150 ICC_BD_11_RollgCntr "P01";
BA_ "E2EDataLength" SG_ 1150 ICC_BD_11_RollgCntr 64;
BA_ "GenSigSendType" SG_ 1150 ICC_CPDDelaySwitchSet 4;
BA_ "E2EDataId" SG_ 1150 ICC_CPDDelaySwitchSet 158;
BA_ "E2EProfile" SG_ 1150 ICC_CPDDelaySwitchSet "P01";
BA_ "E2EDataLength" SG_ 1150 ICC_CPDDelaySwitchSet 64;
BA_ "GenSigSendType" SG_ 1150 ICC_PPMIDBSRBPASet 4;
BA_ "E2EDataId" SG_ 1150 ICC_PPMIDBSRBPASet 158;
BA_ "E2EProfile" SG_ 1150 ICC_PPMIDBSRBPASet "P01";
BA_ "E2EDataLength" SG_ 1150 ICC_PPMIDBSRBPASet 64;
BA_ "GenSigSendType" SG_ 1150 ICC_PPMIDHwSet 4;
BA_ "E2EDataId" SG_ 1150 ICC_PPMIDHwSet 158;
BA_ "E2EProfile" SG_ 1150 ICC_PPMIDHwSet "P01";
BA_ "E2EDataLength" SG_ 1150 ICC_PPMIDHwSet 64;
BA_ "GRC_Sig_ASIL" SG_ 1150 ICC_DriveDrosinessLevel 2;
BA_ "GenSigSendType" SG_ 1150 ICC_DriveDrosinessLevel 0;
BA_ "E2EDataId" SG_ 1150 ICC_DriveDrosinessLevel 158;
BA_ "E2EProfile" SG_ 1150 ICC_DriveDrosinessLevel "P01";
BA_ "E2EDataLength" SG_ 1150 ICC_DriveDrosinessLevel 64;
BA_ "GenSigSendType" SG_ 1150 ICC_FLDoorButton 4;
BA_ "E2EDataId" SG_ 1150 ICC_FLDoorButton 158;
BA_ "E2EProfile" SG_ 1150 ICC_FLDoorButton "P01";
BA_ "E2EDataLength" SG_ 1150 ICC_FLDoorButton 64;
BA_ "GenSigSendType" SG_ 1150 ICC_FRDoorButton 4;
BA_ "E2EDataId" SG_ 1150 ICC_FRDoorButton 158;
BA_ "E2EProfile" SG_ 1150 ICC_FRDoorButton "P01";
BA_ "E2EDataLength" SG_ 1150 ICC_FRDoorButton 64;
BA_ "GenSigSendType" SG_ 1150 ICC_RRDoorButton 4;
BA_ "E2EDataId" SG_ 1150 ICC_RRDoorButton 158;
BA_ "E2EProfile" SG_ 1150 ICC_RRDoorButton "P01";
BA_ "E2EDataLength" SG_ 1150 ICC_RRDoorButton 64;
BA_ "GenSigSendType" SG_ 1150 ICC_RLDoorButton 4;
BA_ "E2EDataId" SG_ 1150 ICC_RLDoorButton 158;
BA_ "E2EProfile" SG_ 1150 ICC_RLDoorButton "P01";
BA_ "E2EDataLength" SG_ 1150 ICC_RLDoorButton 64;
BA_ "GenSigSendType" SG_ 1150 ICC_CloseAllDoors 4;
BA_ "E2EDataId" SG_ 1150 ICC_CloseAllDoors 158;
BA_ "E2EProfile" SG_ 1150 ICC_CloseAllDoors "P01";
BA_ "E2EDataLength" SG_ 1150 ICC_CloseAllDoors 64;
BA_ "GenSigSendType" SG_ 1150 ICC_DoorRemoteKeyControlEnable 4;
BA_ "E2EDataId" SG_ 1150 ICC_DoorRemoteKeyControlEnable 158;
BA_ "E2EProfile" SG_ 1150 ICC_DoorRemoteKeyControlEnable "P01";
BA_ "E2EDataLength" SG_ 1150 ICC_DoorRemoteKeyControlEnable 64;
BA_ "GenSigSendType" SG_ 1150 ICC_SetOpenAngle 4;
BA_ "E2EDataId" SG_ 1150 ICC_SetOpenAngle 158;
BA_ "E2EProfile" SG_ 1150 ICC_SetOpenAngle "P01";
BA_ "E2EDataLength" SG_ 1150 ICC_SetOpenAngle 64;
BA_ "GenSigSendType" SG_ 1150 ICC_CPDSwitchSet 4;
BA_ "E2EDataId" SG_ 1150 ICC_CPDSwitchSet 158;
BA_ "E2EProfile" SG_ 1150 ICC_CPDSwitchSet "P01";
BA_ "E2EDataLength" SG_ 1150 ICC_CPDSwitchSet 64;
BA_ "GenSigSendType" SG_ 1150 ICC_FrontDoorPowerMode 4;
BA_ "E2EDataId" SG_ 1150 ICC_FrontDoorPowerMode 158;
BA_ "E2EProfile" SG_ 1150 ICC_FrontDoorPowerMode "P01";
BA_ "E2EDataLength" SG_ 1150 ICC_FrontDoorPowerMode 64;
BA_ "GenSigSendType" SG_ 1150 ICC_RearDoorPowerMode 4;
BA_ "E2EDataId" SG_ 1150 ICC_RearDoorPowerMode 158;
BA_ "E2EProfile" SG_ 1150 ICC_RearDoorPowerMode "P01";
BA_ "E2EDataLength" SG_ 1150 ICC_RearDoorPowerMode 64;
BA_ "GenSigSendType" SG_ 1150 ICC_PedalCloseDriverDoorEnable 4;
BA_ "E2EDataId" SG_ 1150 ICC_PedalCloseDriverDoorEnable 158;
BA_ "E2EProfile" SG_ 1150 ICC_PedalCloseDriverDoorEnable "P01";
BA_ "E2EDataLength" SG_ 1150 ICC_PedalCloseDriverDoorEnable 64;
BA_ "GenSigSendType" SG_ 1150 RR_Door_RearScreen_Control 4;
BA_ "E2EDataId" SG_ 1150 RR_Door_RearScreen_Control 158;
BA_ "E2EProfile" SG_ 1150 RR_Door_RearScreen_Control "P01";
BA_ "E2EDataLength" SG_ 1150 RR_Door_RearScreen_Control 64;
BA_ "GenSigSendType" SG_ 1150 ICC_RearDoorVoiceControlEnable 4;
BA_ "E2EDataId" SG_ 1150 ICC_RearDoorVoiceControlEnable 158;
BA_ "E2EProfile" SG_ 1150 ICC_RearDoorVoiceControlEnable "P01";
BA_ "E2EDataLength" SG_ 1150 ICC_RearDoorVoiceControlEnable 64;
BA_ "GenSigSendType" SG_ 1150 ICC_FLVoiceControl 4;
BA_ "E2EDataId" SG_ 1150 ICC_FLVoiceControl 158;
BA_ "E2EProfile" SG_ 1150 ICC_FLVoiceControl "P01";
BA_ "E2EDataLength" SG_ 1150 ICC_FLVoiceControl 64;
BA_ "GenSigSendType" SG_ 1150 ICC_FRVoiceControl 4;
BA_ "E2EDataId" SG_ 1150 ICC_FRVoiceControl 158;
BA_ "E2EProfile" SG_ 1150 ICC_FRVoiceControl "P01";
BA_ "E2EDataLength" SG_ 1150 ICC_FRVoiceControl 64;
BA_ "GenSigSendType" SG_ 1150 ICC_RRVoiceControl 4;
BA_ "E2EDataId" SG_ 1150 ICC_RRVoiceControl 158;
BA_ "E2EProfile" SG_ 1150 ICC_RRVoiceControl "P01";
BA_ "E2EDataLength" SG_ 1150 ICC_RRVoiceControl 64;
BA_ "GenSigSendType" SG_ 1150 ICC_RLVoiceControl 4;
BA_ "E2EDataId" SG_ 1150 ICC_RLVoiceControl 158;
BA_ "E2EProfile" SG_ 1150 ICC_RLVoiceControl "P01";
BA_ "E2EDataLength" SG_ 1150 ICC_RLVoiceControl 64;
BA_ "GenSigSendType" SG_ 1150 RL_Door_RearScreen_Control 4;
BA_ "E2EDataId" SG_ 1150 RL_Door_RearScreen_Control 158;
BA_ "E2EProfile" SG_ 1150 RL_Door_RearScreen_Control "P01";
BA_ "E2EDataLength" SG_ 1150 RL_Door_RearScreen_Control 64;
BA_ "GenSigSendType" SG_ 917 ADBenable 0;
BA_ "GenSigSendType" SG_ 917 RandomMusicShowCMD 0;
BA_ "GenSigSendType" SG_ 917 DIYMusicShowmod 0;
BA_ "GenSigSendType" SG_ 917 LiShowMod 0;
BA_ "GenSigSendType" SG_ 917 MusicLoudness_55HZ 0;
BA_ "GenSigSendType" SG_ 917 MusicLoudness_123HZ 0;
BA_ "GenSigSendType" SG_ 917 MusicLoudness_262HZ 0;
BA_ "GenSigSendType" SG_ 917 MusicLoudness_440HZ 0;
BA_ "GenSigSendType" SG_ 917 MusicLoudness_587HZ 0;
BA_ "GenSigSendType" SG_ 917 MusicLoudness_784HZ 0;
BA_ "GenSigSendType" SG_ 917 MusicLoudness_1318HZ 0;
BA_ "GenSigSendType" SG_ 917 MusicLoudness_2794HZ 0;
BA_ "GenSigSendType" SG_ 917 MusicLoudness_6272HZ 0;
BA_ "GenSigSendType" SG_ 917 ISDShowCMD 0;
BA_ "GenSigSendType" SG_ 917 ISDShowMode 0;
BA_ "GenSigSendType" SG_ 1273 FaceID 5;
BA_ "GenSigSendType" SG_ 1157 Fusa_485_2 4;
BA_ "GenSigSendType" SG_ 1157 Fusa_485_1 4;
BA_ "GenSigSendType" SG_ 1157 ICC_DA_15_CRC 5;
BA_ "E2EDataId" SG_ 1157 ICC_DA_15_CRC 157;
BA_ "E2EProfile" SG_ 1157 ICC_DA_15_CRC "P01";
BA_ "E2EDataLength" SG_ 1157 ICC_DA_15_CRC 64;
BA_ "GenSigSendType" SG_ 1157 ICC_DA_15_RollgCntr 5;
BA_ "E2EDataId" SG_ 1157 ICC_DA_15_RollgCntr 157;
BA_ "E2EProfile" SG_ 1157 ICC_DA_15_RollgCntr "P01";
BA_ "E2EDataLength" SG_ 1157 ICC_DA_15_RollgCntr 64;
BA_ "GenSigSendType" SG_ 1157 ICC_DA_15_Resd 0;
BA_ "E2EDataId" SG_ 1157 ICC_DA_15_Resd 157;
BA_ "E2EProfile" SG_ 1157 ICC_DA_15_Resd "P01";
BA_ "E2EDataLength" SG_ 1157 ICC_DA_15_Resd 64;
BA_ "GenSigSendType" SG_ 1157 ICC_DA_15_BSDLCWSettingSt 4;
BA_ "E2EDataId" SG_ 1157 ICC_DA_15_BSDLCWSettingSt 157;
BA_ "E2EProfile" SG_ 1157 ICC_DA_15_BSDLCWSettingSt "P01";
BA_ "E2EDataLength" SG_ 1157 ICC_DA_15_BSDLCWSettingSt 64;
BA_ "GenSigSendType" SG_ 1157 ICC_DA_15_DOWSettingSt 4;
BA_ "E2EDataId" SG_ 1157 ICC_DA_15_DOWSettingSt 157;
BA_ "E2EProfile" SG_ 1157 ICC_DA_15_DOWSettingSt "P01";
BA_ "E2EDataLength" SG_ 1157 ICC_DA_15_DOWSettingSt 64;
BA_ "GenSigSendType" SG_ 1157 ICC_DA_15_RCWSettingSt 4;
BA_ "E2EDataId" SG_ 1157 ICC_DA_15_RCWSettingSt 157;
BA_ "E2EProfile" SG_ 1157 ICC_DA_15_RCWSettingSt "P01";
BA_ "E2EDataLength" SG_ 1157 ICC_DA_15_RCWSettingSt 64;
BA_ "GenSigSendType" SG_ 1157 ICC_DA_15_RCTARCTBWarnType 4;
BA_ "GenSigStartValue" SG_ 1157 ICC_DA_15_RCTARCTBWarnType 3;
BA_ "E2EDataId" SG_ 1157 ICC_DA_15_RCTARCTBWarnType 157;
BA_ "E2EProfile" SG_ 1157 ICC_DA_15_RCTARCTBWarnType "P01";
BA_ "E2EDataLength" SG_ 1157 ICC_DA_15_RCTARCTBWarnType 64;
BA_ "GenSigSendType" SG_ 1157 ICC_DA_15_FCTAFCTBWarnType 4;
BA_ "GenSigStartValue" SG_ 1157 ICC_DA_15_FCTAFCTBWarnType 3;
BA_ "E2EDataId" SG_ 1157 ICC_DA_15_FCTAFCTBWarnType 157;
BA_ "E2EProfile" SG_ 1157 ICC_DA_15_FCTAFCTBWarnType "P01";
BA_ "E2EDataLength" SG_ 1157 ICC_DA_15_FCTAFCTBWarnType 64;
BA_ "GenSigSendType" SG_ 1157 ICC_DA_15_FrontPDCMuteSet 0;
BA_ "E2EDataId" SG_ 1157 ICC_DA_15_FrontPDCMuteSet 157;
BA_ "E2EProfile" SG_ 1157 ICC_DA_15_FrontPDCMuteSet "P01";
BA_ "E2EDataLength" SG_ 1157 ICC_DA_15_FrontPDCMuteSet 64;
BA_ "GenSigSendType" SG_ 1157 ICC_DA_15_FKPMuteSet 0;
BA_ "E2EDataId" SG_ 1157 ICC_DA_15_FKPMuteSet 157;
BA_ "E2EProfile" SG_ 1157 ICC_DA_15_FKPMuteSet "P01";
BA_ "E2EDataLength" SG_ 1157 ICC_DA_15_FKPMuteSet 64;
BA_ "GenSigSendType" SG_ 1157 ICC_DA_15_ExtremeEnergySaveMode 0;
BA_ "E2EDataId" SG_ 1157 ICC_DA_15_ExtremeEnergySaveMode 157;
BA_ "E2EProfile" SG_ 1157 ICC_DA_15_ExtremeEnergySaveMode "P01";
BA_ "E2EDataLength" SG_ 1157 ICC_DA_15_ExtremeEnergySaveMode 64;
BA_ "GRC_Sig_ASIL" SG_ 1157 Driver_EyeOnRoad 3;
BA_ "GenSigSendType" SG_ 1157 Driver_EyeOnRoad 0;
BA_ "E2EDataId" SG_ 1157 Driver_EyeOnRoad 157;
BA_ "E2EProfile" SG_ 1157 Driver_EyeOnRoad "P01";
BA_ "E2EDataLength" SG_ 1157 Driver_EyeOnRoad 64;
BA_ "GRC_Sig_ASIL" SG_ 1157 Dms_Status 3;
BA_ "GenSigSendType" SG_ 1157 Dms_Status 0;
BA_ "E2EDataId" SG_ 1157 Dms_Status 157;
BA_ "E2EProfile" SG_ 1157 Dms_Status "P01";
BA_ "E2EDataLength" SG_ 1157 Dms_Status 64;
BA_ "GenSigSendType" SG_ 1157 Driver_AbnormalBehavior 0;
BA_ "E2EDataId" SG_ 1157 Driver_AbnormalBehavior 157;
BA_ "E2EProfile" SG_ 1157 Driver_AbnormalBehavior "P01";
BA_ "E2EDataLength" SG_ 1157 Driver_AbnormalBehavior 64;
BA_ "GenSigSendType" SG_ 1157 Driver_GazeRegion 0;
BA_ "E2EDataId" SG_ 1157 Driver_GazeRegion 157;
BA_ "E2EProfile" SG_ 1157 Driver_GazeRegion "P01";
BA_ "E2EDataLength" SG_ 1157 Driver_GazeRegion 64;
BA_ "GRC_Sig_ASIL" SG_ 1157 Dms_DriverPresence 2;
BA_ "GenSigSendType" SG_ 1157 Dms_DriverPresence 0;
BA_ "E2EDataId" SG_ 1157 Dms_DriverPresence 157;
BA_ "E2EProfile" SG_ 1157 Dms_DriverPresence "P01";
BA_ "E2EDataLength" SG_ 1157 Dms_DriverPresence 64;
BA_ "GenSigSendType" SG_ 1157 ICC_IHCfunctionSw 4;
BA_ "E2EDataId" SG_ 1157 ICC_IHCfunctionSw 157;
BA_ "E2EProfile" SG_ 1157 ICC_IHCfunctionSw "P01";
BA_ "E2EDataLength" SG_ 1157 ICC_IHCfunctionSw 64;
BA_ "GenSigSendType" SG_ 1279 Weather_Type 0;
BA_ "GenSigSendType" SG_ 1279 ICC_SentinelModeSts 0;
BA_ "GenSigSendType" SG_ 1279 ICC_CameraErrorCode 0;
BA_ "GenSigSendType" SG_ 1279 ICC_SentinelRequest 5;
BA_ "GenSigSendType" SG_ 1279 ICC_StartDeInitCameraStream 5;
BA_ "GenSigSendType" SG_ 1279 ICC_CameraRecoveryRequest 5;
BA_ "GenSigSendType" SG_ 1279 ICC_CleanMode 5;
BA_ "GenSigSendType" SG_ 644 ICM_5_FuelLevel 0;
BA_ "GenSigSendType" SG_ 644 FuelShortGround 0;
BA_ "GenSigSendType" SG_ 644 FuelShortPower 0;
BA_ "GenSigSendType" SG_ 644 FuelOutOfRange 0;
BA_ "GenSigSendType" SG_ 644 FuelValidData 0;
BA_ "GenSigSendType" SG_ 1174 IHU_SetSocManage 5;
BA_ "GenSigSendType" SG_ 1174 IHU_SetSOC 5;
BA_ "GenSigSendType" SG_ 1174 CTP_PowerModeSet 5;
BA_ "GenSigSendType" SG_ 1174 LidOpenReq 5;
BA_ "GenSigSendType" SG_ 1174 ICC_ForcedEVMode 5;
BA_ "GenSigSendType" SG_ 1174 ICC_EmissionMode 0;
BA_ "GenSigSendType" SG_ 1174 ICC_ForcedEVChargeMode 5;
BA_ "GenSigSendType" SG_ 1174 EVOdometer_km 0;
BA_ "GenSigInvalidValue" SG_ 1174 EVOdometer_km 16777215;
BA_ "GenSigSendType" SG_ 1174 EVOdometer_km_ValidData 0;
BA_ "GenSigSendType" SG_ 1174 ICC_SetChrgnFctMem 5;
BA_ "GenSigSendType" SG_ 1242 ICC_DK_19_CRC1 1;
BA_ "GenSigSendType" SG_ 1242 ICC_DK_19_RollgCntr1 1;
BA_ "GenSigSendType" SG_ 1242 ICC_DK_19_Resd1 1;
BA_ "GenSigSendType" SG_ 1242 ICC_DK_19_CMD 1;
BA_ "GenSigSendType" SG_ 1242 ICC_DK_19_PDU1 1;
BA_ "GenSigSendType" SG_ 1242 ICC_DK_19_PDU2 1;
BA_ "GenSigSendType" SG_ 1242 ICC_DK_19_PDU3 1;
BA_ "GenSigSendType" SG_ 1242 ICC_DK_19_PDU4 1;
BA_ "GenSigSendType" SG_ 1276 PassSeatHeiAdjmt_Target 5;
BA_ "GenSigSendType" SG_ 1276 SeatBackAndFwdAdjmt_Target 5;
BA_ "GenSigSendType" SG_ 1276 SeatBackAgAdjmt_Target 5;
BA_ "GenSigSendType" SG_ 1276 Set_ProfileID 5;
BA_ "GenSigSendType" SG_ 1276 SeatCushAgAdjmt_Target 5;
BA_ "GenSigSendType" SG_ 1276 LgRstFwdAndBckAdjmt_Target 5;
BA_ "GenSigSendType" SG_ 1276 FootRestAdjmt_Target 5;
BA_ "GenSigSendType" SG_ 1276 REQ_SeatPosRecall 5;
BA_ "GenSigSendType" SG_ 1276 REQ_SeatPosStore 5;
BA_ "GenSigSendType" SG_ 1276 Set_ToDefault 5;
BA_ "GenSigStartValue" SG_ 1276 Set_ToDefault 7;
BA_ "GenSigSendType" SG_ 1276 Set_EasyEntryEnable 5;
BA_ "GenSigStartValue" SG_ 1276 Set_EasyEntryEnable 3;
BA_ "GenSigSendType" SG_ 1276 REQ_SeatHeatPass 5;
BA_ "GenSigSendType" SG_ 1276 REQ_SeatVentPass 5;
BA_ "GenSigSendType" SG_ 1276 PassSeatMsgStr_LvlCmd 5;
BA_ "GenSigSendType" SG_ 1276 PassSeatMsg_ModeCmd 5;
BA_ "GenSigSendType" SG_ 1059 ICC_FLSeatHeatLevelCmd 5;
BA_ "GenSigSendType" SG_ 1059 ICC_FRSeatHeatLevelCmd 5;
BA_ "GenSigSendType" SG_ 1059 ICC_TrunkSW 5;
BA_ "GenSigSendType" SG_ 1059 ICC_Set_PLGOperateSts 5;
BA_ "GenSigInvalidValue" SG_ 1059 ICC_Set_PLGOperateSts 127;
BA_ "GenSigSendType" SG_ 1059 ICC_RLSeatHeatLevelCmd 5;
BA_ "GenSigSendType" SG_ 1059 ICC_RRSeatHeatLevelCmd 5;
BA_ "GenSigSendType" SG_ 1059 ICC_FLSeatVentLevelCmd 5;
BA_ "GenSigSendType" SG_ 1059 ICC_FRSeatVentLevelCmd 5;
BA_ "GenSigSendType" SG_ 1059 ICC_RLSeatVentLevelCmd 5;
BA_ "GenSigSendType" SG_ 1059 ICC_RRSeatVentLevelCmd 5;
BA_ "GenSigSendType" SG_ 1059 ICC_FrontWiperMaintenanceMode 5;
BA_ "GenSigSendType" SG_ 1059 ICC_RearWiperMaintenanceMode 5;
BA_ "GenSigSendType" SG_ 1105 ICC_MultiplexSignalStatusSet 5;
BA_ "GenSigSendType" SG_ 1056 ICC_DSBH_HeatReq 0;
BA_ "GenSigSendType" SG_ 1056 ICC_DSBH_SetTemp 0;
BA_ "GenSigStartValue" SG_ 1056 ICC_DSBH_SetTemp 30;
BA_ "GenSigSendType" SG_ 1056 ICC_PSBH_HeatReq 0;
BA_ "GenSigSendType" SG_ 1056 ICC_PSBH_SetTemp 0;
BA_ "GenSigStartValue" SG_ 1056 ICC_PSBH_SetTemp 30;
BA_ "GenSigSendType" SG_ 1112 PassSeatMsgStr_LvlCmd 5;
BA_ "GenSigSendType" SG_ 1112 PassSeatMsg_ModeCmd 5;
BA_ "GenSigSendType" SG_ 1112 DriverSeatMsgStr_Lvlcmd 5;
BA_ "GenSigSendType" SG_ 1112 DriverSeatMsg_ModeCmd 5;
BA_ "GenSigSendType" SG_ 1112 RightSeatMsgStr_LvlCmd 5;
BA_ "GenSigSendType" SG_ 1112 RightSeatMsg_ModeCmd 5;
BA_ "GenSigSendType" SG_ 1112 LeftSeatMsgStr_LvlCmd 5;
BA_ "GenSigSendType" SG_ 1112 LeftSeatMsg_ModeCmd 5;
BA_ "GenSigSendType" SG_ 1265 ICC_PwrOff 0;
BA_ "GenSigSendType" SG_ 1265 ICC_EtmEgySave 0;
BA_ "GenSigSendType" SG_ 1265 ICC_HoodSW 5;
BA_ "GenSigSendType" SG_ 1265 ICC_GloveboxSW 5;
BA_ "GenSigSendType" SG_ 1265 ICC_ChrgPortCover_Switch 5;
BA_ "GenSigSendType" SG_ 1265 ICC_ReWinDefrstSwt 5;
BA_ "GenSigSendType" SG_ 1265 ICC_RearMirrorFoldCmd 5;
BA_ "GenSigSendType" SG_ 1265 ICC_CenterLockSwt 5;
BA_ "GenSigSendType" SG_ 1265 ICC_ReverseExtMirrorSts 5;
BA_ "GenSigSendType" SG_ 1265 ICC_LightMainSwitchSts 5;
BA_ "GenSigSendType" SG_ 1265 ICC_AutoFoldSts 5;
BA_ "GenSigSendType" SG_ 1265 ICC_HeadlampHeightSts 5;
BA_ "GenSigSendType" SG_ 1265 ICC_WiprSnvty 5;
BA_ "GenSigSendType" SG_ 1265 ICC_WindowCmd 5;
BA_ "GenSigSendType" SG_ 1265 ICC_LowBeamDelayOff 5;
BA_ "GenSigSendType" SG_ 1265 ICC_FLWinCmd 5;
BA_ "GenSigInvalidValue" SG_ 1265 ICC_FLWinCmd 127;
BA_ "GenSigSendType" SG_ 1265 ICC_FRWinCmd 5;
BA_ "GenSigInvalidValue" SG_ 1265 ICC_FRWinCmd 127;
BA_ "GenSigSendType" SG_ 1265 ICC_RLWinCmd 5;
BA_ "GenSigInvalidValue" SG_ 1265 ICC_RLWinCmd 127;
BA_ "GenSigSendType" SG_ 1265 ICC_RRWinCmd 5;
BA_ "GenSigInvalidValue" SG_ 1265 ICC_RRWinCmd 127;
BA_ "GenSigSendType" SG_ 1265 ICC_FGHeatSts 4;
BA_ "GenSigSendType" SG_ 1265 ICC_AutolockSts 5;
BA_ "GenSigSendType" SG_ 1265 ICC_WiperID 5;
BA_ "GenSigSendType" SG_ 1265 ICC_MaintenanceMode 5;
BA_ "GenSigSendType" SG_ 1265 ICC_lockSetSwitchSts 5;
BA_ "GenSigSendType" SG_ 1265 ICC_ChildLockSW 5;
BA_ "GenSigSendType" SG_ 1265 ICC_ParkUnlockEnable 5;
BA_ "GenSigSendType" SG_ 1265 ICC_BLEOpenDriverDoorEnable 5;
BA_ "GenSigSendType" SG_ 1265 ICC_WinInhbSwt 5;
BA_ "GenSigSendType" SG_ 1265 ICC_SteerWhlHeatgSwt 5;
BA_ "GenSigSendType" SG_ 1265 ICC_AutoHeatingset 5;
BA_ "GenSigSendType" SG_ 1265 ICC_FrontFogSw 5;
BA_ "GenSigSendType" SG_ 1265 ICC_RearFogSw 5;
BA_ "GenSigSendType" SG_ 1265 ICC_DoorControlSW 5;
BA_ "GenSigSendType" SG_ 1265 ICC_LockCarWinCloseSw 5;
BA_ "GenSigSendType" SG_ 1265 ICC_RainCarWinCloseSw 5;
BA_ "GenSigSendType" SG_ 1265 ICC_EasyEntryExitSet 5;
BA_ "GenSigSendType" SG_ 1265 ICC_NapTimeSet 5;
BA_ "GenSigSendType" SG_ 1265 ICC_NapAreaSet 5;
BA_ "GenSigSendType" SG_ 1265 ICC_NapStatusSet 5;
BA_ "GenSigSendType" SG_ 1265 ICC_NapCFSStatusSet 5;
BA_ "GenSigSendType" SG_ 1265 ICC_NapSetTemperature 5;
BA_ "GenSigInvalidValue" SG_ 1265 ICC_NapSetTemperature 31;
BA_ "GenSigStartValue" SG_ 1265 ICC_NapSetTemperature 31;
BA_ "GenSigSendType" SG_ 1265 ICC_SpoilerWelcomeFunSet 5;
BA_ "GenSigSendType" SG_ 1265 ICC_SpoilerCtrlCmd 5;
BA_ "GenSigSendType" SG_ 1265 ICC_HazardLightReq 0;
BA_ "GenSigSendType" SG_ 1265 ICC_MusicStatus 0;
BA_ "GenSigSendType" SG_ 1265 ICC_CinemaStatus 0;
BA_ "GenSigSendType" SG_ 1137 ICC_BookChrgSetReq 5;
BA_ "GenSigSendType" SG_ 1137 ICC_BkChrgStartTimeYear 0;
BA_ "GenSigSendType" SG_ 1137 ICC_BkChrgStartTimeDay 0;
BA_ "GenSigStartValue" SG_ 1137 ICC_BkChrgStartTimeDay 1;
BA_ "GenSigSendType" SG_ 1137 ICC_BkChrgStartTimeHour 0;
BA_ "GenSigInvalidValue" SG_ 1137 ICC_BkChrgStartTimeHour 31;
BA_ "GenSigSendType" SG_ 1137 ICC_BkChrgStartTimemMin 0;
BA_ "GenSigInvalidValue" SG_ 1137 ICC_BkChrgStartTimemMin 63;
BA_ "GenSigSendType" SG_ 1137 ICC_BkChrgStartTimeMonth 0;
BA_ "GenSigStartValue" SG_ 1137 ICC_BkChrgStartTimeMonth 1;
BA_ "GenSigSendType" SG_ 1137 ICC_BkChrgDuration 0;
BA_ "GenSigInvalidValue" SG_ 1137 ICC_BkChrgDuration 2047;
BA_ "GenSigSendType" SG_ 1137 ICC_BkChrgCycleType 0;
BA_ "GenSigSendType" SG_ 1137 ICC_StopChrgReq 5;
BA_ "GenSigSendType" SG_ 1137 ICC_BkChrgCycleMon 0;
BA_ "GenSigSendType" SG_ 1137 ICC_BkChrgCycleTues 0;
BA_ "GenSigSendType" SG_ 1137 ICC_BkChrgCycleWen 0;
BA_ "GenSigSendType" SG_ 1137 ICC_BkChrgCycleThur 0;
BA_ "GenSigSendType" SG_ 1137 ICC_BkChrgCycleFri 0;
BA_ "GenSigSendType" SG_ 1137 ICC_BkChrgCycleSat 0;
BA_ "GenSigSendType" SG_ 1137 ICC_BkChrgCycleSun 0;
BA_ "GenSigSendType" SG_ 1137 ICC_KeepWarmStrt 0;
BA_ "GenSigStartValue" SG_ 1137 ICC_KeepWarmStrt 1;
BA_ "GenSigSendType" SG_ 1137 ICC_KeepWarmStrtHour 0;
BA_ "GenSigInvalidValue" SG_ 1137 ICC_KeepWarmStrtHour 31;
BA_ "GenSigSendType" SG_ 1137 ICC_KeepWarmStrtMin 0;
BA_ "GenSigInvalidValue" SG_ 1137 ICC_KeepWarmStrtMin 63;
BA_ "GenSigSendType" SG_ 1137 ICC_PetmodeFb 0;
BA_ "GenSigInvalidValue" SG_ 1137 ICC_PetmodeFb 3;
BA_ "GenSigSendType" SG_ 1137 ICC_SentinelModeSwitchSts 0;
BA_ "GenSigSendType" SG_ 1137 ICC_SentinelModeWorkingSts 0;
BA_ "GenSigSendType" SG_ 1137 ICC_SentinelModeFaultSts 0;
BA_ "GenSigSendType" SG_ 1137 ICC_SentinelModeAlarmSts 0;
BA_ "GenSigSendType" SG_ 1137 ICC_SentinelModeExitReason 0;
BA_ "GenSigSendType" SG_ 1137 ICC_PetModeWarn 0;
BA_ "GenSigSendType" SG_ 1137 ICC_TBOXPetmodeReq 5;
BA_ "GenSigSendType" SG_ 1137 ICC_PetModeWarn_2 0;
BA_ "GenSigSendType" SG_ 1137 ICM_FuelLevel 0;
BA_ "GenSigSendType" SG_ 1137 ICM_AverageVehicleSpeed 0;
BA_ "GenSigInvalidValue" SG_ 1137 ICM_DistenceToEmpty_Km 2047;
BA_ "GenSigSendType" SG_ 1137 ICM_DistenceToEmpty_Km 0;
BA_ "GenSigSendType" SG_ 1137 ICM_FuelLevelFailSts 0;
BA_ "GenSigSendType" SG_ 1137 ICM_Maintenance_tips 0;
BA_ "GenSigSendType" SG_ 1137 ICM_SumTrip 0;
BA_ "GenSigSendType" SG_ 1144 ICC_HvBattKeepWarmSet 0;
BA_ "GenSigInvalidValue" SG_ 1144 ICC_HvBattKeepWarmSet 3;
BA_ "GenSigStartValue" SG_ 1144 ICC_HvBattKeepWarmSet 3;
BA_ "GenSigSendType" SG_ 1144 ICC_EnergyRegSet 5;
BA_ "GenSigSendType" SG_ 1144 ICC_HvBattKeepWarmActiveReq 5;
BA_ "GenSigSendType" SG_ 1210 ICC_FLSeatHeiCmd 5;
BA_ "GenSigSendType" SG_ 1210 ICC_FLSeatLvlCmd 5;
BA_ "GenSigSendType" SG_ 1210 ICC_FLSeatBackAgCmd 5;
BA_ "GenSigSendType" SG_ 1210 ICC_FLSeatCushCmd 5;
BA_ "GenSigSendType" SG_ 1210 ICC_FLSeatLegSpprtCmd 5;
BA_ "GenSigSendType" SG_ 1210 ICC_FRSeatHeiCmd 5;
BA_ "GenSigSendType" SG_ 1210 ICC_FRSeatLvlCmd 5;
BA_ "GenSigSendType" SG_ 1210 ICC_FRSeatBackAgCmd 5;
BA_ "GenSigSendType" SG_ 1210 ICC_FRSeatLegSpprtCmd 5;
BA_ "GenSigSendType" SG_ 1210 ICC_MemoryRecoveryCmd 5;
BA_ "GenSigSendType" SG_ 1210 ICC_DeleteFaceID 5;
BA_ "GenSigSendType" SG_ 1210 ICC_FLSeatHeitargetCmd 5;
BA_ "GenSigInvalidValue" SG_ 1210 ICC_FLSeatHeitargetCmd 127;
BA_ "GenSigSendType" SG_ 1210 ICC_FLSeatLvltargetCmd 5;
BA_ "GenSigInvalidValue" SG_ 1210 ICC_FLSeatLvltargetCmd 127;
BA_ "GenSigSendType" SG_ 1210 ICC_FLSeatBackAgtargetCmd 5;
BA_ "GenSigInvalidValue" SG_ 1210 ICC_FLSeatBackAgtargetCmd 127;
BA_ "GenSigSendType" SG_ 1210 ICC_FLSeatCushtargetCmd 5;
BA_ "GenSigInvalidValue" SG_ 1210 ICC_FLSeatCushtargetCmd 127;
BA_ "GenSigSendType" SG_ 1210 ICC_FLSeatLegSpprttargetCmd 5;
BA_ "GenSigInvalidValue" SG_ 1210 ICC_FLSeatLegSpprttargetCmd 127;
BA_ "GenSigSendType" SG_ 1210 ICC_FRSeatHeitargetCmd 5;
BA_ "GenSigInvalidValue" SG_ 1210 ICC_FRSeatHeitargetCmd 127;
BA_ "GenSigSendType" SG_ 1210 ICC_FRSeatLvltargetCmd 5;
BA_ "GenSigInvalidValue" SG_ 1210 ICC_FRSeatLvltargetCmd 127;
BA_ "GenSigSendType" SG_ 1210 ICC_FRSeatBackAgtargetCmd 5;
BA_ "GenSigInvalidValue" SG_ 1210 ICC_FRSeatBackAgtargetCmd 127;
BA_ "GenSigSendType" SG_ 1210 ICC_FRSeatLegSpprttargetCmd 5;
BA_ "GenSigInvalidValue" SG_ 1210 ICC_FRSeatLegSpprttargetCmd 127;
BA_ "GenSigSendType" SG_ 1210 ICC_NapFLSeatBackAgtargetSet 5;
BA_ "GenSigInvalidValue" SG_ 1210 ICC_NapFLSeatBackAgtargetSet 127;
BA_ "GenSigSendType" SG_ 1210 ICC_NapFRSeatBackAgtargetSet 5;
BA_ "GenSigInvalidValue" SG_ 1210 ICC_NapFRSeatBackAgtargetSet 127;
BA_ "GenSigSendType" SG_ 1210 ICC_NapFLSeatLvltargetSet 5;
BA_ "GenSigInvalidValue" SG_ 1210 ICC_NapFLSeatLvltargetSet 127;
BA_ "GenSigSendType" SG_ 1210 ICC_NapFRSeatLvltargetSet 5;
BA_ "GenSigInvalidValue" SG_ 1210 ICC_NapFRSeatLvltargetSet 127;
BA_ "GenSigSendType" SG_ 1210 ICC_FRSeatLegRestAngleCmd 5;
BA_ "GenSigSendType" SG_ 1210 ICC_FRSeatLegRestAngletargetCmd 5;
BA_ "GenSigInvalidValue" SG_ 1210 ICC_FRSeatLegRestAngletargetCmd 127;
BA_ "GenSigSendType" SG_ 1210 ICC_FRSeatCushCmd 5;
BA_ "GenSigSendType" SG_ 1210 ICC_FRSeatCushtargetCmd 5;
BA_ "GenSigInvalidValue" SG_ 1210 ICC_FRSeatCushtargetCmd 127;
BA_ "GenSigSendType" SG_ 1210 ICC_FRZeroGravitySeatSw 5;
BA_ "GenSigSendType" SG_ 1210 ICC_HomeLinkArmHornSet 5;
BA_ "GenSigSendType" SG_ 1210 ICC_HomeLinkWelLightSet 5;
BA_ "GenSigSendType" SG_ 1210 ICC_HomeLinkPositionSts 0;
BA_ "GenSigSendType" SG_ 1210 ICC_WelcomeOpenSetCmd 5;
BA_ "GenSigSendType" SG_ 1210 ICC_WALOpenSetCmd 5;
BA_ "GenSigSendType" SG_ 1210 ICC_UIROpenSetCmd 5;
BA_ "GenSigSendType" SG_ 1210 ICC_EnjoyableSeatSwitch 5;
BA_ "GenSigSendType" SG_ 1210 ICC_BLTKeyPESet 5;
BA_ "GenSigSendType" SG_ 1210 ICC_FRMemoryDeleteCmd 5;
BA_ "GenSigSendType" SG_ 1210 ICC_FLSitPosnlocation 5;
BA_ "GenSigSendType" SG_ 1210 ICC_FRSitPosnlocation 5;
BA_ "GenSigSendType" SG_ 1210 ICC_FREasyEntryExitSet 5;
BA_ "GenSigSendType" SG_ 1210 ICC_FRMemoryRecoveryCmd 5;
BA_ "GenSigSendType" SG_ 1210 ICC_ConsoleAdjustSwitch 5;
BA_ "GenSigSendType" SG_ 1399 ICC_CLTC_RangeAval 0;
BA_ "GenSigInvalidValue" SG_ 1399 ICC_CLTC_RangeAval 1023;
BA_ "GenSigSendType" SG_ 1399 ICC_DynamicRangeAval 0;
BA_ "GenSigInvalidValue" SG_ 1399 ICC_DynamicRangeAval 1023;
BA_ "GenSigSendType" SG_ 1399 ICC_WLTC_RangeAval 0;
BA_ "GenSigInvalidValue" SG_ 1399 ICC_WLTC_RangeAval 1023;
BA_ "GenSigSendType" SG_ 1399 ICC_CLTC_RangeAvalFuel 0;
BA_ "GenSigInvalidValue" SG_ 1399 ICC_CLTC_RangeAvalFuel 4095;
BA_ "GenSigSendType" SG_ 1399 ICC_WLTC_RangeAvalFuel 0;
BA_ "GenSigInvalidValue" SG_ 1399 ICC_WLTC_RangeAvalFuel 4095;
BA_ "GenSigSendType" SG_ 1399 ICC_DynamicRangeAvalFuel 0;
BA_ "GenSigInvalidValue" SG_ 1399 ICC_DynamicRangeAvalFuel 4095;
BA_ "GenSigSendType" SG_ 1399 ICC_CLTC_RangeAvalComp 0;
BA_ "GenSigInvalidValue" SG_ 1399 ICC_CLTC_RangeAvalComp 4095;
BA_ "GenSigSendType" SG_ 1399 ICC_WLTC_RangeAvalComp 0;
BA_ "GenSigInvalidValue" SG_ 1399 ICC_WLTC_RangeAvalComp 4095;
BA_ "GenSigSendType" SG_ 1399 ICC_DynamicRangeAvalComp 0;
BA_ "GenSigInvalidValue" SG_ 1399 ICC_DynamicRangeAvalComp 4095;
BA_ "GenSigSendType" SG_ 1399 ICC_Conditiontype 0;
BA_ "GenSigSendType" SG_ 1238 ICC_CFSSwitch 5;
BA_ "GenSigSendType" SG_ 1238 ICC_CFSLevelSet 5;
BA_ "GenSigSendType" SG_ 1238 ICC_CFSPosSet 5;
BA_ "GenSigSendType" SG_ 1238 ICC_PM25Switch 5;
BA_ "GenSigSendType" SG_ 1238 ICC_AQSSwitch 5;
BA_ "GenSigSendType" SG_ 1238 ICC_SecSetTemp_C 5;
BA_ "GenSigInvalidValue" SG_ 1238 ICC_SecSetTemp_C 31;
BA_ "GenSigStartValue" SG_ 1238 ICC_SecSetTemp_C 31;
BA_ "GenSigSendType" SG_ 1238 ICC_SecFaceKeySts 5;
BA_ "GenSigSendType" SG_ 1238 ICC_SecFootKeySts 5;
BA_ "GenSigSendType" SG_ 1238 ICC_SecBlowSpeedLevelKeySts 5;
BA_ "GenSigSendType" SG_ 1238 ICC_SecAutoSwitch 5;
BA_ "GenSigSendType" SG_ 1238 ICC_SecCLMSwitch 5;
BA_ "GenSigSendType" SG_ 1238 ICC_ThrSetTemp_C 5;
BA_ "GenSigInvalidValue" SG_ 1238 ICC_ThrSetTemp_C 31;
BA_ "GenSigStartValue" SG_ 1238 ICC_ThrSetTemp_C 31;
BA_ "GenSigSendType" SG_ 1238 ICC_ThrFaceKeySts 5;
BA_ "GenSigSendType" SG_ 1238 ICC_ThrFootKeySts 5;
BA_ "GenSigSendType" SG_ 1238 ICC_ThrBlowSpeedLevelKeySts 5;
BA_ "GenSigSendType" SG_ 1238 ICC_ThrAutoSwitch 5;
BA_ "GenSigSendType" SG_ 1238 ICC_ThrCLMSwitch 5;
BA_ "GenSigSendType" SG_ 1238 ICC_ThrACRequestKeySts 5;
BA_ "GenSigSendType" SG_ 1238 ICC_DFMSwitch 5;
BA_ "GenSigSendType" SG_ 1289 ICC_TirePressureDisplayUnit 0;
BA_ "GenSigSendType" SG_ 1289 ICC_TireTemperatureDisplayUnit 0;
BA_ "GenSigSendType" SG_ 1289 ICC_ToggleUnits 0;
BA_ "GenSigSendType" SG_ 1289 ICC_BtConFlag 0;
BA_ "GenSigSendType" SG_ 1289 ICC_GPSSwitchSet 0;
BA_ "GenSigSendType" SG_ 1167 ICC_KeyDriveModememory 5;
BA_ "GenSigSendType" SG_ 1167 ICC_DriveModeSet 5;
BA_ "GenSigSendType" SG_ 1167 ICC_DRIFTModeSetReq 5;
BA_ "GenSigSendType" SG_ 1167 ICC_EXPERTEIPBESPSet 5;
BA_ "GenSigSendType" SG_ 1167 ICC_EXPERTEcoSet 5;
BA_ "GenSigSendType" SG_ 1167 ICC_EXPERTNormSet 5;
BA_ "GenSigSendType" SG_ 1167 ICC_EXPERTSportSet 5;
BA_ "GenSigSendType" SG_ 1167 ICC_CrossaxisSet 5;
BA_ "GenSigSendType" SG_ 1167 ICC_EXPERTRWDSet 5;
BA_ "GenSigSendType" SG_ 1167 ICC_EXPERTAWDSet 5;
BA_ "GenSigSendType" SG_ 1167 ICC_EXPERTAutoSet 5;
BA_ "GenSigSendType" SG_ 1167 ICC_CLIMBSet 5;
BA_ "GenSigSendType" SG_ 1167 ICC_DriveModeExitSet 5;
BA_ "GenSigSendType" SG_ 1167 ICC_Confidencelevel 5;
BA_ "GenSigInvalidValue" SG_ 1167 ICC_Confidencelevel 127;
BA_ "GenSigSendType" SG_ 1167 ICC_V2L_IntlDisChg 5;
BA_ "GenSigSendType" SG_ 1167 ICC_ExhibitionModeSwitch 5;
BA_ "GenSigSendType" SG_ 1167 ICC_TrailerMode 5;
BA_ "GenSigSendType" SG_ 1167 ICC_V2L_DisChgMem 5;
BA_ "GenSigSendType" SG_ 1167 ICC_DrivePowerDispSet 5;
BA_ "GenSigSendType" SG_ 1167 ICC_WLTC_to_CLTC_Mode 5;
BA_ "GenSigSendType" SG_ 1167 ICC_StopChrgnSwitch 5;
BA_ "GenSigSendType" SG_ 1167 ICC_StopChrgnMode 5;
BA_ "GenSigSendType" SG_ 1167 ICC_RegenerateLevelCtrl 5;
BA_ "GenSigSendType" SG_ 1167 ICC_SinglePedalMem 5;
BA_ "GenSigSendType" SG_ 1167 ICC_FuelDetnSwt 5;
BA_ "GenSigSendType" SG_ 1167 ICC_FuelDetnState 5;
BA_ "GenSigSendType" SG_ 1167 ICC_FuelDetnOpDefeated 5;
BA_ "GenSigSendType" SG_ 1167 ICC_HVDownRepairMode 5;
BA_ "GenSigSendType" SG_ 1167 ICC_UTURNSnowSet 5;
BA_ "GenSigSendType" SG_ 1167 ICC_UTURNSandSet 5;
BA_ "GenSigSendType" SG_ 1167 ICC_UTURNMudSet 5;
BA_ "GenSigSendType" SG_ 1167 ICC_UTURNGrassSet 5;
BA_ "GenSigSendType" SG_ 1167 ICC_LTCDispSet2 5;
BA_ "GenSigSendType" SG_ 1167 ICC_SetSocManage 5;
BA_ "GenSigSendType" SG_ 1326 ICC_DWDOnOff_Req 5;
BA_ "GenSigSendType" SG_ 1326 ICC_ContainerLightSet 5;
BA_ "GenSigSendType" SG_ 1331 ICC_CMSMTouchSts 5;
BA_ "GenSigSendType" SG_ 1331 ICC_RLSeatEasyEntryExitSet 5;
BA_ "GenSigSendType" SG_ 1331 ICC_RRSeatEasyEntryExitSet 5;
BA_ "GenSigSendType" SG_ 1331 ICC_RLMemoryRecoveryCmd 5;
BA_ "GenSigSendType" SG_ 1331 ICC_RRMemoryRecoveryCmd 5;
BA_ "GenSigSendType" SG_ 1331 ICC_RLSitPosnlocation 5;
BA_ "GenSigSendType" SG_ 1331 ICC_RRSitPosnlocation 5;
BA_ "GenSigSendType" SG_ 1331 ICC_CMSMDisplaySwitch 5;
BA_ "GenSigSendType" SG_ 1331 ICC_CMSMDisplayAdjustmode 5;
BA_ "GenSigSendType" SG_ 1331 ICC_CMSMSetstandardSwitch 5;
BA_ "GenSigSendType" SG_ 1331 ICC_LeftPedalControl 5;
BA_ "GenSigStartValue" SG_ 1331 ICC_LeftPedalControl 3;
BA_ "GenSigSendType" SG_ 1331 ICC_RightPedalControl 5;
BA_ "GenSigStartValue" SG_ 1331 ICC_RightPedalControl 3;
BA_ "GenSigSendType" SG_ 1331 ICC_EPCEnable 5;
BA_ "GenSigSendType" SG_ 1331 ICC_AMPKTVvoiceVolumeSet 5;
BA_ "GenSigSendType" SG_ 1331 ICC_AMPA2BENCSoundReq 5;
BA_ "GenSigSendType" SG_ 1331 ICC_AMPENCVolumeSet 5;
BA_ "GenSigSendType" SG_ 1331 ICC_AMPA2BChimeSoundReq 5;
BA_ "GenSigSendType" SG_ 1331 Set_AMPSoundFocus_2 5;
BA_ "GenSigSendType" SG_ 1331 ICC_AMPA2BKTVvoiceSoundReq 5;
BA_ "GenSigSendType" SG_ 1331 ICC_MedStatusSet 5;
BA_ "GenSigSendType" SG_ 1331 Set_AMPLoudness 5;
BA_ "GenSigSendType" SG_ 1331 ICC_MedAreaSet 5;
BA_ "GenSigSendType" SG_ 1331 ICC_LeftElectricPedalsSet 5;
BA_ "GenSigSendType" SG_ 1331 ICC_RightElectricPedalsSet 5;
BA_ "GenSigSendType" SG_ 1331 ICC_NapAreaSet2 5;
BA_ "GenSigSendType" SG_ 1331 ICC_DisplayAdjustrAngReq 5;
BA_ "GenSigInvalidValue" SG_ 1331 ICC_DisplayAdjustrAngReq 255;
BA_ "GenSigSendType" SG_ 1331 Set_AMPKeyVolume 5;
BA_ "GenSigSendType" SG_ 1331 Set_AMPExSoundmode 5;
BA_ "GenSigSendType" SG_ 1331 Set_AMPA2BENCSound 5;
BA_ "GenSigSendType" SG_ 1333 ICC_SRFCmd 5;
BA_ "GenSigSendType" SG_ 1333 ICC_SRFPercentCmd 5;
BA_ "GenSigSendType" SG_ 1333 ICC_CSunshadeReq 5;
BA_ "GenSigSendType" SG_ 1333 ICC_CSunshadePercentReq 5;
BA_ "GenSigSendType" SG_ 1333 ICC_SunshadeCmd 5;
BA_ "GenSigSendType" SG_ 1333 ICC_SunshadePercentCmd 5;
BA_ "E2EDataLength" SG_ 1335 New_Signal_537_3 64;
BA_ "E2EProfile" SG_ 1335 New_Signal_537_3 "P01";
BA_ "E2EDataId" SG_ 1335 New_Signal_537_3 480;
BA_ "GenSigSendType" SG_ 1335 New_Signal_537_3 0;
BA_ "E2EDataLength" SG_ 1335 New_Signal_537_2 64;
BA_ "E2EProfile" SG_ 1335 New_Signal_537_2 "P01";
BA_ "E2EDataId" SG_ 1335 New_Signal_537_2 480;
BA_ "GenSigSendType" SG_ 1335 New_Signal_537_2 0;
BA_ "E2EDataLength" SG_ 1335 New_Signal_537_1 64;
BA_ "E2EProfile" SG_ 1335 New_Signal_537_1 "P01";
BA_ "E2EDataId" SG_ 1335 New_Signal_537_1 480;
BA_ "GenSigSendType" SG_ 1335 New_Signal_537_1 0;
BA_ "GRC_Sig_ASIL" SG_ 1335 ICC_RolloverSetCmd 2;
BA_ "E2EDataLength" SG_ 1335 ICC_RolloverSetCmd 64;
BA_ "E2EProfile" SG_ 1335 ICC_RolloverSetCmd "P01";
BA_ "E2EDataId" SG_ 1335 ICC_RolloverSetCmd 480;
BA_ "GenSigSendType" SG_ 1335 ICC_RolloverSetCmd 5;
BA_ "E2EDataLength" SG_ 1335 ICC_SET_EPS_SteerReturnRmdSts 64;
BA_ "E2EProfile" SG_ 1335 ICC_SET_EPS_SteerReturnRmdSts "P01";
BA_ "E2EDataId" SG_ 1335 ICC_SET_EPS_SteerReturnRmdSts 480;
BA_ "GenSigSendType" SG_ 1335 ICC_SET_EPS_SteerReturnRmdSts 5;
BA_ "E2EDataLength" SG_ 1335 ICC_SET_MFSShake 64;
BA_ "E2EProfile" SG_ 1335 ICC_SET_MFSShake "P01";
BA_ "E2EDataId" SG_ 1335 ICC_SET_MFSShake 480;
BA_ "GenSigSendType" SG_ 1335 ICC_SET_MFSShake 5;
BA_ "E2EDataLength" SG_ 1335 ICC_DMS_1_DistractionLevel 64;
BA_ "E2EProfile" SG_ 1335 ICC_DMS_1_DistractionLevel "P01";
BA_ "E2EDataId" SG_ 1335 ICC_DMS_1_DistractionLevel 480;
BA_ "GenSigSendType" SG_ 1335 ICC_DMS_1_DistractionLevel 5;
BA_ "E2EDataLength" SG_ 1335 ICC_SET_EPS_AsociWithDrvModSts 64;
BA_ "E2EProfile" SG_ 1335 ICC_SET_EPS_AsociWithDrvModSts "P01";
BA_ "E2EDataId" SG_ 1335 ICC_SET_EPS_AsociWithDrvModSts 480;
BA_ "GenSigSendType" SG_ 1335 ICC_SET_EPS_AsociWithDrvModSts 5;
BA_ "E2EDataLength" SG_ 1335 ICC_OverLoadWarnShieldSet 64;
BA_ "E2EProfile" SG_ 1335 ICC_OverLoadWarnShieldSet "P01";
BA_ "E2EDataId" SG_ 1335 ICC_OverLoadWarnShieldSet 480;
BA_ "GenSigSendType" SG_ 1335 ICC_OverLoadWarnShieldSet 5;
BA_ "E2EDataLength" SG_ 1335 ICC_BSWReq 64;
BA_ "E2EProfile" SG_ 1335 ICC_BSWReq "P01";
BA_ "E2EDataId" SG_ 1335 ICC_BSWReq 480;
BA_ "GenSigSendType" SG_ 1335 ICC_BSWReq 5;
BA_ "E2EDataLength" SG_ 1335 ICC_horizontalReq 64;
BA_ "E2EProfile" SG_ 1335 ICC_horizontalReq "P01";
BA_ "E2EDataId" SG_ 1335 ICC_horizontalReq 480;
BA_ "GenSigSendType" SG_ 1335 ICC_horizontalReq 5;
BA_ "GenSigSendType" SG_ 1337 ICC_SET_BT_ReduceWindSpeed 5;
BA_ "GenSigSendType" SG_ 1337 ICC_SET_IPM_FirstBlowing 5;
BA_ "GenSigSendType" SG_ 1337 ICC_SET_IPM_BlowerDelay 5;
BA_ "GenSigSendType" SG_ 1337 ICC_SET_CirculationInTunnels 5;
BA_ "GenSigSendType" SG_ 1337 ICC_UVCLuminanceReq 5;
BA_ "GenSigSendType" SG_ 1337 ICC_UVCControlReq 5;
BA_ "GenSigSendType" SG_ 1337 ICC_CrossCountryCoolingReq 5;
BA_ "GenSigSendType" SG_ 1337 ICC_KeepWarmReq 5;
BA_ "GenSigSendType" SG_ 1337 ICC_keepwarmSetTemperatureReq 5;
BA_ "GenSigSendType" SG_ 1337 ICC_ParkingAirConditioning 5;
BA_ "GenSigSendType" SG_ 1337 ICC_CoolantFill_Req 5;
BA_ "GenSigSendType" SG_ 1337 ICC_FraganceLightoffReq 5;
BA_ "GenSigSendType" SG_ 1337 ICC_FraganceMemoffReq 5;
BA_ "GenSigSendType" SG_ 1337 ICC_AirPurgeReminderReq 5;
BA_ "GenSigSendType" SG_ 1337 ICC_CFSCycleLevel 5;
BA_ "GenSigSendType" SG_ 1337 ICC_TimingLevel 5;
BA_ "GenSigSendType" SG_ 1337 ICC_ModeAdjustDisplaySts 5;
BA_ "GenSigStartValue" SG_ 1337 ICC_ModeAdjustDisplaySts 5;
BA_ "GenSigSendType" SG_ 1337 ICC_BiochemicalFuncReq 5;
BA_ "GenSigSendType" SG_ 1337 ICC_TimedVentilationReq 5;
BA_ "GenSigSendType" SG_ 1337 ICC_PetmodeSetTemperature_L_C 5;
BA_ "GenSigInvalidValue" SG_ 1337 ICC_PetmodeSetTemperature_L_C 31;
BA_ "GenSigStartValue" SG_ 1337 ICC_PetmodeSetTemperature_L_C 31;
BA_ "GenSigSendType" SG_ 1337 ICC_PetModeSetTemperature_R_C 5;
BA_ "GenSigInvalidValue" SG_ 1337 ICC_PetModeSetTemperature_R_C 31;
BA_ "GenSigStartValue" SG_ 1337 ICC_PetModeSetTemperature_R_C 31;
BA_ "GenSigSendType" SG_ 1337 ICC_PetModeSetCLMOn 5;
BA_ "GenSigSendType" SG_ 1337 ICC_PetModeSetAutoKeySts 5;
BA_ "GenSigSendType" SG_ 1337 ICC_PetModeSetCirculationSts 5;
BA_ "GenSigSendType" SG_ 1318 ICC_SET_TDL_Rhythm_Switch 5;
BA_ "GenSigSendType" SG_ 1318 ICC_SET_TDL_Switch 5;
BA_ "GenSigSendType" SG_ 1318 ICC_SET_TDL_ColourModeAdj 5;
BA_ "GenSigSendType" SG_ 1318 ICC_VoiceWake 5;
BA_ "GenSigSendType" SG_ 1318 ICC_TDL_RhythmReq 5;
BA_ "GenSigSendType" SG_ 1318 ICC_SET_ApiluminanceAdj 5;
BA_ "GenSigSendType" SG_ 1318 ICC_SET_MusicLoudness_120HZ 0;
BA_ "GenSigStartValue" SG_ 1318 ICC_SET_MusicLoudness_120HZ 15;
BA_ "GenSigSendType" SG_ 1318 ICC_SET_MusicLoudness_250HZ 0;
BA_ "GenSigStartValue" SG_ 1318 ICC_SET_MusicLoudness_250HZ 15;
BA_ "GenSigSendType" SG_ 1318 ICC_SET_MusicLoudness_500HZ 0;
BA_ "GenSigStartValue" SG_ 1318 ICC_SET_MusicLoudness_500HZ 15;
BA_ "GenSigSendType" SG_ 1318 ICC_SET_MusicLoudness_1000HZ 0;
BA_ "GenSigStartValue" SG_ 1318 ICC_SET_MusicLoudness_1000HZ 15;
BA_ "GenSigSendType" SG_ 1318 ICC_SET_MusicLoudness_1500HZ 0;
BA_ "GenSigStartValue" SG_ 1318 ICC_SET_MusicLoudness_1500HZ 15;
BA_ "GenSigSendType" SG_ 1318 ICC_SET_MusicLoudness_2000HZ 0;
BA_ "GenSigStartValue" SG_ 1318 ICC_SET_MusicLoudness_2000HZ 15;
BA_ "GenSigSendType" SG_ 1318 ICC_SET_MusicLoudness_6000HZ 0;
BA_ "GenSigSendType" SG_ 1318 ICC_TDL_FlowLightSw 5;
BA_ "GenSigSendType" SG_ 1318 ICC_TDL_FlowLightModeAdj 5;
BA_ "GenSigSendType" SG_ 1318 ICC_SET_256ColourAdj 5;
BA_ "GenSigInvalidValue" SG_ 1318 ICC_SET_256ColourAdj 127;
BA_ "GenSigStartValue" SG_ 1318 ICC_SET_256ColourAdj 127;
BA_ "GenSigSendType" SG_ 1320 ICC_Chb_Req 5;
BA_ "GenSigSendType" SG_ 1320 ICC_ChbMem_Req 5;
BA_ "GenSigSendType" SG_ 1320 ICC_ChbDelay_Req 5;
BA_ "GenSigSendType" SG_ 1320 ICC_ChbSterilization_Req 5;
BA_ "GenSigSendType" SG_ 1320 ICC_ChbItemsLeft_Req 5;
BA_ "GenSigSendType" SG_ 1320 ICC_ParkingRadarSwSet 5;
BA_ "GenSigSendType" SG_ 1320 ICC_ChbTimeset_Req 5;
BA_ "GenSigInvalidValue" SG_ 1320 ICC_ChbTimeset_Req 31;
BA_ "GenSigSendType" SG_ 1320 ICC_ChbCoolset_Req 5;
BA_ "GenSigSendType" SG_ 1320 ICC_ChbCoolorheat_Req 5;
BA_ "GenSigSendType" SG_ 1320 ICC_ChbHeatset_Req 5;
BA_ "GenSigSendType" SG_ 1360 ICC_XDriveMode 5;
BA_ "GenSigSendType" SG_ 1360 ICC_LISD_DisplaySwitch 5;
BA_ "GenSigSendType" SG_ 1360 ICC_LISD_ParkingShowCMD 5;
BA_ "GenSigSendType" SG_ 1360 ICC_RoofCampLampSetL 5;
BA_ "GenSigSendType" SG_ 1360 ICC_RISD_DisplaySwitch 5;
BA_ "GenSigSendType" SG_ 1360 ICC_RISD_ParkingShowCMD 5;
BA_ "GenSigSendType" SG_ 1360 ICC_RoofCampLampSetR 5;
BA_ "GenSigSendType" SG_ 1360 ICC_LogoParkingReq 5;
BA_ "GenSigSendType" SG_ 1360 ICC_LogoChargingReq 5;
BA_ "GenSigSendType" SG_ 1360 ICC_DRLSw 5;
BA_ "GenSigSendType" SG_ 1360 ICC_TopLightSet 5;
BA_ "GenSigSendType" SG_ 1360 ICC_APillarYellowAmbientSet 5;
BA_ "GenSigSendType" SG_ 1360 ICC_APillarWhiteAmbientSet 5;
BA_ "GenSigSendType" SG_ 1360 ICC_LISD_ParkingShowMod 5;
BA_ "GenSigSendType" SG_ 1360 ICC_RISD_ParkingShowMod 5;
BA_ "GenSigSendType" SG_ 1360 ICC_APillarSpotLampSet 5;
BA_ "GenSigSendType" SG_ 1360 ICC_PenetrationLampSetF 5;
BA_ "GenSigSendType" SG_ 1360 ICC_MusicLampShowSW 5;
BA_ "GenSigSendType" SG_ 1360 ICC_LogoColorReq 5;
VAL_ 1254 ICC_WelcomeOpenSet 0 "Not Active" 1 "On" 2 "Off" 3 "Not Used" ;
VAL_ 1254 ICC_WALOpenSet 0 "Not Active" 1 "On" 2 "Off" 3 "Not Used" ;
VAL_ 1254 ICC_EasytrunkSet 0 "Not Active" 1 "On" 2 "Off" 3 "Not Used" ;
VAL_ 1254 ICC_UIROpenSet 0 "Not Active" 1 "On" 2 "Off" 3 "Not Used" ;
VAL_ 1254 ICC_BeanIDReq 0 "No action" 1 "Request" 2 "Clear data" 3 "Reserved" ;
VAL_ 1254 ICC_CWCWorkingStsSet 0 "Not active" 1 "OFF" 2 "ON" 3 "Invalid" ;
VAL_ 1254 ICC_CWCPhoneforgottenFunStsSet 0 "Not active" 1 "OFF" 2 "ON" 3 "Invalid" ;
VAL_ 1254 ICC_RCWCWorkingStsSet 0 "Not active" 1 "OFF" 2 "ON" 3 "Invalid" ;
VAL_ 1254 ICC_RCWCPhoneforgottenFunStsSet 0 "Not active" 1 "OFF" 2 "ON" 3 "Invalid" ;
VAL_ 1100 Set_AMPNaviVolume 0 "Not Active" 1 "0" 2 "1" 3 "2" 4 "3" 5 "4" 6 "5" 7 "6" 8 "7" 9 "8" 10 "9" 11 "10" 12 "Reserved" 13 "Reserved" 14 "Reserved" 15 "Reserved" ;
VAL_ 1100 Set_AMPVRVolume 0 "Not Active" 1 "0" 2 "1" 3 "2" 4 "3" 5 "4" 6 "5" 7 "6" 8 "7" 9 "8" 10 "9" 11 "10" 12 "Reserved" 13 "Reserved" 14 "Reserved" 15 "Reserved" ;
VAL_ 1100 Set_AMPKeyTone 0 "Not Active" 1 "ON" 2 "OFF" 3 "reserved" ;
VAL_ 1100 Set_AMPMediaVolume 0 "Not Active" 1 "0" 2 "1" 3 "2" 4 "3" 5 "4" 6 "5" 7 "6" 8 "7" 9 "8" 10 "9" 11 "10" 12 "11" 13 "12" 14 "13" 15 "14" 16 "15" 17 "16" 18 "17" 19 "18" 20 "19" 21 "20" 22 "21" 23 "22" 24 "23" 25 "24" 26 "25" 27 "26" 28 "27" 29 "28" 30 "29" 31 "30" 32 "31" 33 "Reserved" 34 "Reserved" 35 "Reserved" 36 "Reserved" 37 "Reserved" 38 "Reserved" 39 "Reserved" 40 "Reserved" 41 "Reserved" 42 "Reserved" 43 "Reserved" 44 "Reserved" 45 "Reserved" 46 "Reserved" 47 "Reserved" 48 "Reserved" 49 "Reserved" 50 "Reserved" 51 "Reserved" 52 "Reserved" 53 "Reserved" 54 "Reserved" 55 "Reserved" 56 "Reserved" 57 "Reserved" 58 "Reserved" 59 "Reserved" 60 "Reserved" 61 "Reserved" 62 "Reserved" 63 "Reserved" ;
VAL_ 1100 Set_AMPPhoneVolume 0 "Not Active" 1 "0" 2 "1" 3 "2" 4 "3" 5 "4" 6 "5" 7 "6" 8 "7" 9 "8" 10 "9" 11 "10" 12 "11" 13 "12" 14 "13" 15 "14" 16 "15" 17 "16" 18 "17" 19 "18" 20 "19" 21 "20" 22 "21" 23 "22" 24 "23" 25 "24" 26 "25" 27 "Reserved" 28 "Reserved" 29 "Reserved" 30 "Reserved" 31 "Reserved" ;
VAL_ 1100 Set_AMPSoundFocus 0 "Not Active" 1 "Customized" 2 "All" 3 "Driver" 4 "Sleep" 5 "VIP" 6 "Dolby7.1.4" 7 "Reserved" ;
VAL_ 1100 Set_AMPSoundEffect 0 "Not Active" 1 "Customer-defined mode" 2 "Standard mode" 3 "Popular mode" 4 "Jazz mode" 5 "Classic mode" 6 "Rock mode" 7 "Vocal mode" 8 "Reserved" 9 "Reserved" 10 "Reserved" 11 "Reserved" 12 "Reserved" 13 "Reserved" 14 "Reserved" 15 "Reserved" ;
VAL_ 1100 Set_AMPSoundEffectBass 0 "Not Active" 1 "-7" 2 "-6" 3 "-5" 4 "-4" 5 "-3" 6 "-2" 7 "-1" 8 "0" 9 "1" 10 "2" 11 "3" 12 "4" 13 "5" 14 "6" 15 "7" ;
VAL_ 1100 Set_AMPSoundEffectMidrange 0 "Not Active" 1 "-7" 2 "-6" 3 "-5" 4 "-4" 5 "-3" 6 "-2" 7 "-1" 8 "0" 9 "1" 10 "2" 11 "3" 12 "4" 13 "5" 14 "6" 15 "7" ;
VAL_ 1100 Set_AMPSoundEffectTreble 0 "Not Active" 1 "-7" 2 "-6" 3 "-5" 4 "-4" 5 "-3" 6 "-2" 7 "-1" 8 "0" 9 "1" 10 "2" 11 "3" 12 "4" 13 "5" 14 "6" 15 "7" ;
VAL_ 1100 Set_AMPSoundFieldBalance 0 "Not Active" 1 "-7" 2 "-6" 3 "-5" 4 "-4" 5 "-3" 6 "-2" 7 "-1" 8 "0" 9 "1" 10 "2" 11 "3" 12 "4" 13 "5" 14 "6" 15 "7" ;
VAL_ 1100 Set_AMPSoundFieldFader 0 "Not Active" 1 "-7" 2 "-6" 3 "-5" 4 "-4" 5 "-3" 6 "-2" 7 "-1" 8 "0" 9 "1" 10 "2" 11 "3" 12 "4" 13 "5" 14 "6" 15 "7" ;
VAL_ 1100 Set_Headrest_Mode 0 "Not Active" 1 "Share Mode" 2 "Enjoy Driving Mode" 3 "Enjoy Private Mode" ;
VAL_ 1100 Set_SurndFnOnOff 0 "Not Active" 1 "ON" 2 "OFF" 3 "Reserved" ;
VAL_ 1100 Set_VirtualSbwfrOnOff 0 "Not Active" 1 "VocalConcert" 2 "ConcertHall" 3 "OFF" ;
VAL_ 1119 Set_AMPMediaDuck 0 "Not Active" 1 "ON" 2 "OFF" 3 "Reserved" ;
VAL_ 1119 Set_AMPSpeedVolume 0 "Not Active" 1 "OFF" 2 "Low" 3 "Middle" 4 "High" 5 "Reserved" 6 "Reserved" 7 "Reserved" ;
VAL_ 1119 Set_AMPMute 0 "Not Active" 1 "ON" 2 "OFF" 3 "Reserved" ;
VAL_ 1119 REQ_AMPA2BMediaSound 0 "Not Active" 1 "Media" 2 "Background" 3 "OFF" ;
VAL_ 1119 REQ_AMPA2BNaviSound 0 "Not Active" 1 "ON" 2 "OFF" 3 "Reserved" ;
VAL_ 1119 REQ_AMPA2BVRSound 0 "Not Active" 1 "VR" 2 "Siri" 3 "OFF" ;
VAL_ 1119 REQ_AMPA2BTTSSound 0 "Not Active" 1 "ON" 2 "OFF" 3 "Reserved" ;
VAL_ 1119 REQ_AMPA2BKeyTone 0 "Not Active" 1 "ON" 2 "OFF" 3 "Reserved" ;
VAL_ 1119 Set_AMPRestoreDefaults 0 "Not Active" 1 "ON" 2 "OFF" 3 "Reserved" ;
VAL_ 1119 Set_AMPAlarmVolume 0 "Not Active" 1 "1" 2 "2" 3 "3" 4 "4" 5 "5" 6 "6" 7 "7" 8 "8" 9 "9" 10 "10" 11 "Reserved" 12 "Reserved" 13 "Reserved" 14 "Reserved" 15 "Reserved" ;
VAL_ 1119 REQ_AMPA2BPhoneSound 0 "Not Active" 1 "BT Phone Sound ON" 2 "Tbox Sound ON" 3 "OFF" ;
VAL_ 1119 Set_AMPSoundEffectMegaBass 0 "Not Active" 1 "-7" 2 "-6" 3 "-5" 4 "-4" 5 "-3" 6 "-2" 7 "-1" 8 "0" 9 "1" 10 "2" 11 "3" 12 "4" 13 "5" 14 "6" 15 "7" ;
VAL_ 1119 Set_AMPSoundEffectMidBass 0 "Not Active" 1 "-7" 2 "-6" 3 "-5" 4 "-4" 5 "-3" 6 "-2" 7 "-1" 8 "0" 9 "1" 10 "2" 11 "3" 12 "4" 13 "5" 14 "6" 15 "7" ;
VAL_ 1119 Set_AMPSoundEffectMidTreble 0 "Not Active" 1 "-7" 2 "-6" 3 "-5" 4 "-4" 5 "-3" 6 "-2" 7 "-1" 8 "0" 9 "1" 10 "2" 11 "3" 12 "4" 13 "5" 14 "6" 15 "7" ;
VAL_ 1119 Set_AMPBackgroundVolume 0 "Not Active" 1 "0" 2 "1" 3 "2" 4 "3" 5 "4" 6 "5" 7 "6" 8 "7" 9 "8" 10 "9" 11 "10" 12 "11" 13 "12" 14 "13" 15 "14" 16 "15" 17 "16" 18 "17" 19 "18" 20 "19" 21 "20" 22 "21" 23 "22" 24 "23" 25 "24" 26 "25" 27 "26" 28 "27" 29 "28" 30 "29" 31 "30" 32 "31" 33 "Reserved" 34 "Reserved" 35 "Reserved" 36 "Reserved" 37 "Reserved" 38 "Reserved" 39 "Reserved" 40 "Reserved" 41 "Reserved" 42 "Reserved" 43 "Reserved" 44 "Reserved" 45 "Reserved" 46 "Reserved" 47 "Reserved" 48 "Reserved" 49 "Reserved" 50 "Reserved" 51 "Reserved" 52 "Reserved" 53 "Reserved" 54 "Reserved" 55 "Reserved" 56 "Reserved" 57 "Reserved" 58 "Reserved" 59 "Reserved" 60 "Reserved" 61 "Reserved" 62 "Reserved" 63 "Reserved" ;
VAL_ 1119 Set_AMPSoundBypass 0 "Not Active" 1 "ON" 2 "OFF" 3 "Reserved" ;
VAL_ 1119 Set_AMPA2BConfig 0 "Not Active" 1 "Not OK" 2 "OK" 3 "Reserved" ;
VAL_ 1150 ICC_CPDDelaySwitchSet 0 "Not Active" 1 "ON" 2 "OFF" 3 "Not Used" ;
VAL_ 1150 ICC_PPMIDBSRBPASet 0 "Not Active" 1 "ON" 2 "OFF" 3 "Not Used" ;
VAL_ 1150 ICC_PPMIDHwSet 0 "Not Active" 1 "ON" 2 "OFF" 3 "Not Used" ;
VAL_ 1150 ICC_DriveDrosinessLevel 0 "not available" 1 "unknown" 2 "not fatigue" 3 "low fatigue" 4 "mid-fatigue" 5 "highly fatigue" 6 "Reserved" 7 "Reserved" ;
VAL_ 1150 ICC_FLDoorButton 0 "Init" 1 "Inactive" 2 "Active" 3 "Reserved" ;
VAL_ 1150 ICC_FRDoorButton 0 "Init" 1 "Inactive" 2 "Active" 3 "Reserved" ;
VAL_ 1150 ICC_RRDoorButton 0 "Init" 1 "Inactive" 2 "Active" 3 "Reserved" ;
VAL_ 1150 ICC_RLDoorButton 0 "Init" 1 "Inactive" 2 "Active" 3 "Reserved" ;
VAL_ 1150 ICC_CloseAllDoors 0 "Init" 1 "Inactive" 2 "Active" 3 "Reserved" ;
VAL_ 1150 ICC_DoorRemoteKeyControlEnable 0 "No Request" 1 "Enable" 2 "Disable" 3 "Reserved" ;
VAL_ 1150 ICC_SetOpenAngle 0 "No Request" 1 "50%" 2 "75%" 3 "100%" ;
VAL_ 1150 ICC_CPDSwitchSet 0 "Not Active" 1 "ON" 2 "OFF" 3 "Not Used" ;
VAL_ 1150 ICC_FrontDoorPowerMode 0 "No Request" 1 "PowerMode" 2 "ManualMode" 3 "SemiAutoMode" ;
VAL_ 1150 ICC_RearDoorPowerMode 0 "No Request" 1 "PowerMode" 2 "ManualMode" 3 "SemiAutoMode" ;
VAL_ 1150 ICC_PedalCloseDriverDoorEnable 0 "No Request" 1 "Enable" 2 "Disable" 3 "Reserved" ;
VAL_ 1150 RR_Door_RearScreen_Control 0 "No Request" 1 "Inactive" 2 "active" 3 "Reserved" ;
VAL_ 1150 ICC_RearDoorVoiceControlEnable 0 "No Request" 1 "Enable" 2 "Disable" 3 "Reserved" ;
VAL_ 1150 ICC_FLVoiceControl 0 "No Action" 1 "Door Close" 2 "Door Open" 3 "Reserved" ;
VAL_ 1150 ICC_FRVoiceControl 0 "No Action" 1 "Door Close" 2 "Door Open" 3 "Reserved" ;
VAL_ 1150 ICC_RRVoiceControl 0 "No Action" 1 "Door Close" 2 "Door Open" 3 "Reserved" ;
VAL_ 1150 ICC_RLVoiceControl 0 "No Action" 1 "Door Close" 2 "Door Open" 3 "Reserved" ;
VAL_ 1150 RL_Door_RearScreen_Control 0 "No Request" 1 "Inactive" 2 "active" 3 "Reserved" ;
VAL_ 917 ADBenable 0 "Notactive" 1 "enable" 2 "disenable" 3 "Reserved" ;
VAL_ 917 RandomMusicShowCMD 0 "Not active" 1 "Active" 2 "Reserved" 3 "Reserved" ;
VAL_ 917 DIYMusicShowmod 0 "Not active" 1 "waiting" 2 "mode1" 3 "mode2" ;
VAL_ 917 LiShowMod 0 "NotActive" 1 "OFF" 2 "Mode1" 3 "Mode2" 4 "Mode3" 5 "Mode4(Reserved)" 6 "Mode5(Reserved)" 7 "Reserved" ;
VAL_ 917 MusicLoudness_55HZ 0 "Level 1" 1 "Level 2" 2 "Level 3" 3 "Level 4" 4 "Level 5" 5 "Level 6" 6 "Level 7" 7 "Level 8" 8 "Level 9" 9 "Level 10" 10 "Level 11" 11 "Level 12" 12 "Level 13" 13 "Level 14" 14 "Level 15" 15 "Level 16" 16 "Reserved" 17 "Reserved" 18 "Reserved" 19 "Reserved" 20 "Reserved" 21 "Reserved" 22 "Reserved" 23 "Reserved" 24 "Reserved" 25 "Reserved" 26 "Reserved" 27 "Reserved" 28 "Reserved" 29 "Reserved" 30 "Reserved" 31 "Invalid" ;
VAL_ 917 MusicLoudness_123HZ 0 "Level 1" 1 "Level 2" 2 "Level 3" 3 "Level 4" 4 "Level 5" 5 "Level 6" 6 "Level 7" 7 "Level 8" 8 "Level 9" 9 "Level 10" 10 "Level 11" 11 "Level 12" 12 "Level 13" 13 "Level 14" 14 "Level 15" 15 "Level 16" 16 "Reserved" 17 "Reserved" 18 "Reserved" 19 "Reserved" 20 "Reserved" 21 "Reserved" 22 "Reserved" 23 "Reserved" 24 "Reserved" 25 "Reserved" 26 "Reserved" 27 "Reserved" 28 "Reserved" 29 "Reserved" 30 "Reserved" 31 "Invalid" ;
VAL_ 917 MusicLoudness_262HZ 0 "Level 1" 1 "Level 2" 2 "Level 3" 3 "Level 4" 4 "Level 5" 5 "Level 6" 6 "Level 7" 7 "Level 8" 8 "Level 9" 9 "Level 10" 10 "Level 11" 11 "Level 12" 12 "Level 13" 13 "Level 14" 14 "Level 15" 15 "Level 16" 16 "Reserved" 17 "Reserved" 18 "Reserved" 19 "Reserved" 20 "Reserved" 21 "Reserved" 22 "Reserved" 23 "Reserved" 24 "Reserved" 25 "Reserved" 26 "Reserved" 27 "Reserved" 28 "Reserved" 29 "Reserved" 30 "Reserved" 31 "Invalid" ;
VAL_ 917 MusicLoudness_440HZ 0 "Level 1" 1 "Level 2" 2 "Level 3" 3 "Level 4" 4 "Level 5" 5 "Level 6" 6 "Level 7" 7 "Level 8" 8 "Level 9" 9 "Level 10" 10 "Level 11" 11 "Level 12" 12 "Level 13" 13 "Level 14" 14 "Level 15" 15 "Level 16" 16 "Reserved" 17 "Reserved" 18 "Reserved" 19 "Reserved" 20 "Reserved" 21 "Reserved" 22 "Reserved" 23 "Reserved" 24 "Reserved" 25 "Reserved" 26 "Reserved" 27 "Reserved" 28 "Reserved" 29 "Reserved" 30 "Reserved" 31 "Invalid" ;
VAL_ 917 MusicLoudness_587HZ 0 "Level 1" 1 "Level 2" 2 "Level 3" 3 "Level 4" 4 "Level 5" 5 "Level 6" 6 "Level 7" 7 "Level 8" 8 "Level 9" 9 "Level 10" 10 "Level 11" 11 "Level 12" 12 "Level 13" 13 "Level 14" 14 "Level 15" 15 "Level 16" 16 "Reserved" 17 "Reserved" 18 "Reserved" 19 "Reserved" 20 "Reserved" 21 "Reserved" 22 "Reserved" 23 "Reserved" 24 "Reserved" 25 "Reserved" 26 "Reserved" 27 "Reserved" 28 "Reserved" 29 "Reserved" 30 "Reserved" 31 "Invalid" ;
VAL_ 917 MusicLoudness_784HZ 0 "Level 1" 1 "Level 2" 2 "Level 3" 3 "Level 4" 4 "Level 5" 5 "Level 6" 6 "Level 7" 7 "Level 8" 8 "Level 9" 9 "Level 10" 10 "Level 11" 11 "Level 12" 12 "Level 13" 13 "Level 14" 14 "Level 15" 15 "Level 16" 16 "Reserved" 17 "Reserved" 18 "Reserved" 19 "Reserved" 20 "Reserved" 21 "Reserved" 22 "Reserved" 23 "Reserved" 24 "Reserved" 25 "Reserved" 26 "Reserved" 27 "Reserved" 28 "Reserved" 29 "Reserved" 30 "Reserved" 31 "Invalid" ;
VAL_ 917 MusicLoudness_1318HZ 0 "Level 1" 1 "Level 2" 2 "Level 3" 3 "Level 4" 4 "Level 5" 5 "Level 6" 6 "Level 7" 7 "Level 8" 8 "Level 9" 9 "Level 10" 10 "Level 11" 11 "Level 12" 12 "Level 13" 13 "Level 14" 14 "Level 15" 15 "Level 16" 16 "Reserved" 17 "Reserved" 18 "Reserved" 19 "Reserved" 20 "Reserved" 21 "Reserved" 22 "Reserved" 23 "Reserved" 24 "Reserved" 25 "Reserved" 26 "Reserved" 27 "Reserved" 28 "Reserved" 29 "Reserved" 30 "Reserved" 31 "Invalid" ;
VAL_ 917 MusicLoudness_2794HZ 0 "Level 1" 1 "Level 2" 2 "Level 3" 3 "Level 4" 4 "Level 5" 5 "Level 6" 6 "Level 7" 7 "Level 8" 8 "Level 9" 9 "Level 10" 10 "Level 11" 11 "Level 12" 12 "Level 13" 13 "Level 14" 14 "Level 15" 15 "Level 16" 16 "Reserved" 17 "Reserved" 18 "Reserved" 19 "Reserved" 20 "Reserved" 21 "Reserved" 22 "Reserved" 23 "Reserved" 24 "Reserved" 25 "Reserved" 26 "Reserved" 27 "Reserved" 28 "Reserved" 29 "Reserved" 30 "Reserved" 31 "Invalid" ;
VAL_ 917 MusicLoudness_6272HZ 0 "Level 1" 1 "Level 2" 2 "Level 3" 3 "Level 4" 4 "Level 5" 5 "Level 6" 6 "Level 7" 7 "Level 8" 8 "Level 9" 9 "Level 10" 10 "Level 11" 11 "Level 12" 12 "Level 13" 13 "Level 14" 14 "Level 15" 15 "Level 16" 16 "Reserved" 17 "Reserved" 18 "Reserved" 19 "Reserved" 20 "Reserved" 21 "Reserved" 22 "Reserved" 23 "Reserved" 24 "Reserved" 25 "Reserved" 26 "Reserved" 27 "Reserved" 28 "Reserved" 29 "Reserved" 30 "Reserved" 31 "Invalid" ;
VAL_ 917 ISDShowCMD 0 "OFF" 1 "ON" ;
VAL_ 917 ISDShowMode 0 "Default value" 1 "BatteryCharging" 2 "Brand" 3 "TiresPressures" 4 "Weather" 5 "Greetings" 6 "Package" 7 "Panda" 8 "PredestrianCrossing" 9 "PingPong" 10 "Kite" 11 "Coffee" 12 "Reserved" 13 "Reserved" 14 "Reserved" 15 "Reserved" ;
VAL_ 1273 FaceID 0 "Not active" 1 "ID1" 2 "ID2" 3 "ID3" 4 "ID4" 5 "ID5" 6 "Not Used" 7 "Not Used" ;
VAL_ 1157 ICC_DA_15_BSDLCWSettingSt 0 "None" 1 "ON" 2 "OFF" 3 "Reserved" ;
VAL_ 1157 ICC_DA_15_DOWSettingSt 0 "None" 1 "ON" 2 "OFF" 3 "Reserved" ;
VAL_ 1157 ICC_DA_15_RCWSettingSt 0 "None" 1 "ON" 2 "OFF" 3 "Reserved" ;
VAL_ 1157 ICC_DA_15_RCTARCTBWarnType 0 "OFF" 1 "Warning" 2 "Warning and braking" 3 "None" ;
VAL_ 1157 ICC_DA_15_FCTAFCTBWarnType 0 "OFF" 1 "Warning" 2 "Warning and braking" 3 "None" ;
VAL_ 1157 ICC_DA_15_FrontPDCMuteSet 0 "OFF" 1 "ON" ;
VAL_ 1157 ICC_DA_15_FKPMuteSet 0 "OFF" 1 "ON" ;
VAL_ 1157 ICC_DA_15_ExtremeEnergySaveMode 0 "OFF" 1 "ON" ;
VAL_ 1157 Driver_EyeOnRoad 0 "Unavailable" 1 "Eyes on road" 2 "Eyes off road -- driving task related region" 3 "Eyes off road -- non-driving task related region" ;
VAL_ 1157 Dms_Status 0 "Init" 1 "off/standby" 2 "active" 3 "fault" 4 "camera blocked" ;
VAL_ 1157 Driver_AbnormalBehavior 0 "unknown" 1 "no abnormal behavior detected" 2 "abnormal behavior detected" 3 "Reserved" ;
VAL_ 1157 Driver_GazeRegion 0 "Unknown" 1 "Driver Side of Windscreen" 2 "Passenger Side of Windscreen" 3 "Left Rear View Mirror" 4 "Right Rear View Mirror" 5 "Left Side Window" 6 "Right Side Window" 7 "Central Rear View Mirror" 8 "Central driver's Instrument Cluster(speed gauge,etc.)" 9 "other" ;
VAL_ 1157 Dms_DriverPresence 0 "unknown" 1 "Not present" 2 "present" 3 "Reserved" ;
VAL_ 1157 ICC_IHCfunctionSw 0 "Not Active" 1 "ON" 2 "OFF" 3 "Reserved" ;
VAL_ 1279 Weather_Type 0 "Reserved" 1 "Sunny" 2 "Cloudy" 3 "Overcast" 4 "Shower" 5 "Thundershower" 6 "Thundershower with hail" 7 "Sleet" 8 "Light rain" 9 "Moderate rain" 10 "Heavy rain" 11 "Storm" 12 "Reserved(Heavy storm)" 13 "Reserved(Severe storm)" 14 "Reserved(Snow flurry)" 15 "Light snow" 16 "Moderate snow" 17 "Heavy snow" 18 "Snowstorm" 19 "Foggy" 20 "Reserved(Ice rain)" 21 "Duststorm" 22 "Reserved(Light to moderate rain)" 23 "Reserved(Moderate to heavy rain)" 24 "Reserved(Heavy rain to storm)" 25 "Reserved(Storm to heavy storm)" 26 "Reserved(Heavy to severe storm)" 27 "Reserved(Light to moderate snow)" 28 "Reserved(Moderate to heavy snow)" 29 "Reserve(Heavy snow to snowstorm)" 30 "Dust" 31 "Sand" 32 "Reserved(Sandstorm)" 33 "Haze" 34 "Reserved" 35 "Reserved" 36 "Reserved" 37 "Reserved" 38 "Reserved" 39 "Reserved" 40 "Reserved" 41 "Reserved" 42 "Reserved" 43 "Reserved" 44 "Reserved" 45 "Reserved" 46 "Reserved" 47 "Reserved" 48 "Reserved" 49 "Reserved" 50 "Reserved" 51 "Reserved" 52 "Reserved" 53 "Reserved" 54 "Reserved" 55 "Reserved" 56 "Reserved" 57 "Reserved" 58 "Reserved" 59 "Reserved" 60 "Reserved" 61 "Reserved" 62 "Reserved" 63 "Reserved" ;
VAL_ 1279 ICC_SentinelModeSts 0 "invalid" 1 "OFF" 2 "ON" 3 "Reserved" ;
VAL_ 1279 ICC_CameraErrorCode 0 "NoError" 1 "ErrorCode1" 2 "ErrorCode2" 3 "ErrorCode3" ;
VAL_ 1279 ICC_SentinelRequest 0 "Not Active" 1 "EnterSentinelRequest" 2 "ExitSentinelRequest" 3 "OFF" ;
VAL_ 1279 ICC_StartDeInitCameraStream 0 "Not Active" 1 "ICC_StartDeInitCameraStream" 2 "Reserved" 3 "Reserved" ;
VAL_ 1279 ICC_CameraRecoveryRequest 0 "Not Active" 1 "ICC_StartRecovery" 2 "Reserved" 3 "Reserved" ;
VAL_ 1279 ICC_CleanMode 0 "Not Active" 1 "OFF" 2 "ON" 3 "Reserved" ;
VAL_ 644 FuelShortGround 0 "Fail Not Present" 1 "Short Ground" ;
VAL_ 644 FuelShortPower 0 "Fail Not Present" 1 "Short Power" ;
VAL_ 644 FuelOutOfRange 0 "Fail Not Present" 1 "Out Of Range" ;
VAL_ 644 FuelValidData 0 "Valid" 1 "Not valid" ;
VAL_ 1174 IHU_SetSocManage 0 "Not Active" 1 "Pure electricity priority mode" 2 "Fuel priority mode" 3 "SOC hold mode" 4 "Reserved" 5 "Reserved" 6 "Reserved" 7 "Reserved" ;
VAL_ 1174 IHU_SetSOC 255 "Not Active" ;
VAL_ 1174 CTP_PowerModeSet 0 "Not Active" 1 "EV" 2 "HEV" 3 "EV+" ;
VAL_ 1174 LidOpenReq 0 "No request" 1 "Request" ;
VAL_ 1174 ICC_ForcedEVMode 0 "Not Active" 1 "On" 2 "Off" 3 "Reserved" ;
VAL_ 1174 ICC_EmissionMode 0 "Not Active" 1 "Active" ;
VAL_ 1174 ICC_ForcedEVChargeMode 0 "Not Active" 1 "On" 2 "Off" 3 "Reserved" ;
VAL_ 1174 EVOdometer_km_ValidData 0 "Valid" 1 "Not valid" ;
VAL_ 1174 ICC_SetChrgnFctMem 0 "Not active" 1 "Remember" 2 "No Remember" 3 "Reserved" ;
VAL_ 1276 PassSeatHeiAdjmt_Target 0 "Not active" 1 "0" 2 "10%" 3 "20%" 4 "30%" 5 "40%" 6 "50%" 7 "60%" 8 "70%" 9 "80%" 10 "90%" 11 "100%" ;
VAL_ 1276 SeatBackAndFwdAdjmt_Target 0 "Not active" 1 "0" 2 "10%" 3 "20%" 4 "30%" 5 "40%" 6 "50%" 7 "60%" 8 "70%" 9 "80%" 10 "90%" 11 "100%" ;
VAL_ 1276 SeatBackAgAdjmt_Target 0 "Not active" 1 "0" 2 "5%" 3 "10%" 4 "15%" 5 "20%" 6 "25%" 7 "30%" 8 "35%" 9 "40%" 10 "45%" 11 "50%" 12 "55%" 13 "60%" 14 "65%" 15 "70%" 16 "75%" 17 "80%" 18 "85%" 19 "90%" 20 "95%" 21 "100%" ;
VAL_ 1276 Set_ProfileID 0 "Not active" 1 "ID1" 2 "ID2" 3 "ID3" 4 "ID4" 5 "ID5" 6 "ID6" 7 "Ignore" ;
VAL_ 1276 SeatCushAgAdjmt_Target 0 "Not active" 1 "0" 2 "10%" 3 "20%" 4 "30%" 5 "40%" 6 "50%" 7 "60%" 8 "70%" 9 "80%" 10 "90%" 11 "100%" ;
VAL_ 1276 LgRstFwdAndBckAdjmt_Target 0 "Not active" 1 "0" 2 "10%" 3 "20%" 4 "30%" 5 "40%" 6 "50%" 7 "60%" 8 "70%" 9 "80%" 10 "90%" 11 "100%" ;
VAL_ 1276 FootRestAdjmt_Target 0 "Not active" 1 "0" 2 "10%" 3 "20%" 4 "30%" 5 "40%" 6 "50%" 7 "60%" 8 "70%" 9 "80%" 10 "90%" 11 "100%" ;
VAL_ 1276 REQ_SeatPosRecall 0 "No action" 1 "Recall seat_mode_1 of ID1" 2 "Recall seat_mode_2 of ID1" 3 "Recall seat_mode_3 of ID1" 4 "Recall seat_mode_1 of ID2" 5 "Recall seat_mode_2 of ID2" 6 "Recall seat_mode_3 of ID2" 7 "Recall seat_mode_1 of ID3" 8 "Recall seat_mode_2 of ID3" 9 "Recall seat_mode_3 of ID3" 10 "Recall seat_mode_1 of ID4" 11 "Recall seat_mode_2 of ID4" 12 "Recall seat_mode_3 of ID4" 13 "Recall seat_mode_1 of ID5" 14 "Recall seat_mode_2 of ID5" 15 "Recall seat_mode_3 of ID5" ;
VAL_ 1276 REQ_SeatPosStore 0 "No action" 1 "Store seat_mode_1 of ID1" 2 "Store seat_mode_2 of ID1" 3 "Store seat_mode_3 of ID1" 4 "Store seat_mode_1 of ID2" 5 "Store seat_mode_2 of ID2" 6 "Store seat_mode_3 of ID2" 7 "Store seat_mode_1 of ID3" 8 "Store seat_mode_2 of ID3" 9 "Store seat_mode_3 of ID3" 10 "Store seat_mode_1 of ID4" 11 "Store seat_mode_2 of ID4" 12 "Store seat_mode_3 of ID4" 13 "Store seat_mode_1 of ID5" 14 "Store seat_mode_2 of ID5" 15 "Store seat_mode_3 of ID5" ;
VAL_ 1276 Set_ToDefault 0 "No action" 1 "Set_Vehicle_to_default" 2 "Set_Personalization_to_default" 3 "Set_Telematics_to_default" 4 "Set_System_to_default" 5 "Set_All_to_default" 6 "Reserved" 7 "Ignore" ;
VAL_ 1276 Set_EasyEntryEnable 0 "No action" 1 "Enable" 2 "Disable" 3 "Ignore" ;
VAL_ 1276 REQ_SeatHeatPass 0 "Not Pressed" 1 "Seat heating level 1" 2 "Seat heating level 2" 3 "Seat heating level 3" ;
VAL_ 1276 REQ_SeatVentPass 0 "Not Pressed" 1 "Seat venting level 1" 2 "Seat venting level 2" 3 "Seat venting level 3" ;
VAL_ 1276 PassSeatMsgStr_LvlCmd 0 "NotActive" 1 "OFF" 2 "Low" 3 "Middle" 4 "High" ;
VAL_ 1276 PassSeatMsg_ModeCmd 0 "NotActive" 1 "PulseMode" 2 "WaveMode" 3 "CatPawMode" 4 "SigleRowMode" 5 "CrossMode" 6 "ButterflyMode" 7 "WaistMode" 8 "SnakeMode" 9 "Special 1" 10 "Special 2" 11 "Special 3" 12 "Special 4" ;
VAL_ 1059 ICC_FLSeatHeatLevelCmd 0 "Not Active" 1 "OFF" 2 "Seat heating Level1" 3 "Seat heating Level2" 4 "Seat heating Level3" 5 "Reserved" 6 "Reserved" 7 "Reserved" ;
VAL_ 1059 ICC_FRSeatHeatLevelCmd 0 "Not Active" 1 "OFF" 2 "Seat heating Level1" 3 "Seat heating Level2" 4 "Seat heating Level3" 5 "Reserved" 6 "Reserved" 7 "Reserved" ;
VAL_ 1059 ICC_TrunkSW 0 "Not Active" 1 "ON" 2 "OFF" 3 "Reserved" ;
VAL_ 1059 ICC_Set_PLGOperateSts 0 "Not active" ;
VAL_ 1059 ICC_RLSeatHeatLevelCmd 0 "Not active" 1 "OFF" 2 "Seat heating Level1" 3 "Seat heating Level2" 4 "Seat heating Level3" 5 "Reserved" 6 "Reserved" 7 "Reserved" ;
VAL_ 1059 ICC_RRSeatHeatLevelCmd 0 "Not active" 1 "OFF" 2 "Seat heating Level1" 3 "Seat heating Level2" 4 "Seat heating Level3" 5 "Reserved" 6 "Reserved" 7 "Reserved" ;
VAL_ 1059 ICC_FLSeatVentLevelCmd 0 "Not Active" 1 "OFF" 2 "Seat Ventilation Level1" 3 "Seat Ventilation Level2" 4 "Seat Ventilation Level3" 5 "Reserved" 6 "Reserved" 7 "Reserved" ;
VAL_ 1059 ICC_FRSeatVentLevelCmd 0 "Not Active" 1 "OFF" 2 "Seat Ventilation Level1" 3 "Seat Ventilation Level2" 4 "Seat Ventilation Level3" 5 "Reserved" 6 "Reserved" 7 "Reserved" ;
VAL_ 1059 ICC_RLSeatVentLevelCmd 0 "Not Active" 1 "OFF" 2 "Seat Ventilation Level1" 3 "Seat Ventilation Level2" 4 "Seat Ventilation Level3" 5 "Reserved" 6 "Reserved" 7 "Reserved" ;
VAL_ 1059 ICC_RRSeatVentLevelCmd 0 "Not Active" 1 "OFF" 2 "Seat Ventilation Level1" 3 "Seat Ventilation Level2" 4 "Seat Ventilation Level3" 5 "Reserved" 6 "Reserved" 7 "Reserved" ;
VAL_ 1059 ICC_FrontWiperMaintenanceMode 0 "Not Active" 1 "ON" 2 "OFF" 3 "Reserved" ;
VAL_ 1059 ICC_RearWiperMaintenanceMode 0 "Not Active" 1 "ON" 2 "OFF" 3 "Reserved" ;
VAL_ 1105 ICC_MultiplexSignalStatusSet 0 "Not Active" 1 "Mirror" 2 "EPS" 3 "HUD" 4 "OFF" 5 "Reserved" 6 "Reserved" 7 "invalid" ;
VAL_ 1056 ICC_DSBH_HeatReq 0 "NotActive" 1 "No Heat Request" 2 "Heat Request" 3 "Reserved" ;
VAL_ 1056 ICC_DSBH_SetTemp 0 "NotActive" ;
VAL_ 1056 ICC_PSBH_HeatReq 0 "NotActive" 1 "No Heat Request" 2 "Heat Request" 3 "Reserved" ;
VAL_ 1056 ICC_PSBH_SetTemp 0 "NotActive" ;
VAL_ 1112 PassSeatMsgStr_LvlCmd 0 "NotActive/Initial" 1 "OFF" 2 "Low" 3 "Middle" 4 "High" ;
VAL_ 1112 PassSeatMsg_ModeCmd 0 "NotActive" 1 "PulseMode" 2 "WaveMode" 3 "CatPawMode" 4 "SigleRowMode" 5 "CrossMode" 6 "ButterflyMode" 7 "WaistMode" 8 "SnakeMode" 9 "Special 1" 10 "Special 2" 11 "Special 3" 12 "Special 4" ;
VAL_ 1112 DriverSeatMsgStr_Lvlcmd 0 "NotActive/Initial" 1 "OFF" 2 "Low" 3 "Middle" 4 "High" ;
VAL_ 1112 DriverSeatMsg_ModeCmd 0 "NotActive" 1 "PulseMode" 2 "WaveMode" 3 "CatPawMode" 4 "SigleRowMode" 5 "CrossMode" 6 "ButterflyMode" 7 "WaistMode" 8 "SnakeMode" 9 "Special 1" 10 "Special 2" 11 "Special 3" 12 "Special 4" ;
VAL_ 1112 RightSeatMsgStr_LvlCmd 0 "NotActive/Initial" 1 "OFF" 2 "Low" 3 "Middle" 4 "High" ;
VAL_ 1112 RightSeatMsg_ModeCmd 0 "NotActive" 1 "PulseMode" 2 "WaveMode" 3 "CatPawMode" 4 "SigleRowMode" 5 "CrossMode" 6 "ButterflyMode" 7 "WaistMode" 8 "SnakeMode" 9 "Special 1" 10 "Special 2" 11 "Special 3" 12 "Special 4" ;
VAL_ 1112 LeftSeatMsgStr_LvlCmd 0 "NotActive/Initial" 1 "OFF" 2 "Low" 3 "Middle" 4 "High" ;
VAL_ 1112 LeftSeatMsg_ModeCmd 0 "NotActive" 1 "PulseMode" 2 "WaveMode" 3 "CatPawMode" 4 "SigleRowMode" 5 "CrossMode" 6 "ButterflyMode" 7 "WaistMode" 8 "SnakeMode" 9 "Special 1" 10 "Special 2" 11 "Special 3" 12 "Special 4" ;
VAL_ 1265 ICC_PwrOff 0 "No active" 1 "Active" ;
VAL_ 1265 ICC_EtmEgySave 0 "OFF" 1 "ON" ;
VAL_ 1265 ICC_HoodSW 0 "Not Active" 1 "ON" 2 "Reserved" 3 "Reserved" ;
VAL_ 1265 ICC_GloveboxSW 0 "Not Active" 1 "ON" 2 "Reserved" 3 "Reserved" ;
VAL_ 1265 ICC_ChrgPortCover_Switch 0 "Not Active" 1 "ON" 2 "OFF" 3 "Reserved" ;
VAL_ 1265 ICC_ReWinDefrstSwt 0 "Not Active" 1 "ON" 2 "OFF" 3 "Reserved" ;
VAL_ 1265 ICC_RearMirrorFoldCmd 0 "Not Active" 1 "Fold" 2 "Unfold" 3 "Reserved" ;
VAL_ 1265 ICC_CenterLockSwt 0 "Not Active" 1 "UNLOCK" 2 "LOCK" 3 "Reserved" ;
VAL_ 1265 ICC_ReverseExtMirrorSts 0 "Not active" 1 "OFF" 2 "Only right side" 3 "Only left side" 4 "Both sides" 5 "Not Used" 6 "Not Used" 7 "Not Used" ;
VAL_ 1265 ICC_LightMainSwitchSts 0 "Not active" 1 "Off" 2 "Auto" 3 "PositionLampSwitch" 4 "LowBeamSwitch" 5 "Reserved" 6 "Reserved" 7 "Reserved" ;
VAL_ 1265 ICC_AutoFoldSts 0 "Not active" 1 "Autofold mode" 2 "Not autofold mode" 3 "Not used" ;
VAL_ 1265 ICC_HeadlampHeightSts 0 "Not active" 1 "Level 0" 2 "Level 1" 3 "Level 2" 4 "Level 3" 5 "Not Used" 6 "Not Used" 7 "Not Used" ;
VAL_ 1265 ICC_WiprSnvty 0 "Not Active" 1 "Level1" 2 "Level2" 3 "Level3" 4 "Level4" 5 "Reserved" 6 "Reserved" ;
VAL_ 1265 ICC_WindowCmd 0 "Not active" 1 "FLWindow open" 2 "FLWindow close" 3 "FRWindow open" 4 "FRWindow close" 5 "RLWindow open" 6 "RLWindow close" 7 "RRWindow open" 8 "RRWindow close" 9 "Front Windows open" 10 "Front Windows close" 11 "Rear Windows open" 12 "Rear Windows close" 13 "All Windows open" 14 "All  Windows close" 15 "All  Windows comfort" 16 "Not used" 17 "Not used" 18 "Not used" 19 "Not used" 20 "Not used" 21 "Not used" 22 "Not used" 23 "Not used" 24 "Not used" 25 "Not used" 26 "Not used" 27 "Not used" 28 "Not used" 29 "Not used" 30 "Not used" 31 "Not used" ;
VAL_ 1265 ICC_LowBeamDelayOff 0 "Not Active" 1 "0s" 2 "10s" 3 "20s" 4 "30s" 5 "60s" 6 "Not Used" 7 "Not Used" ;
VAL_ 1265 ICC_FGHeatSts 0 "Not Active" 1 "ON" 2 "OFF" 3 "Reserved" ;
VAL_ 1265 ICC_AutolockSts 0 "Not active" 1 "Autolock mode" 2 "Not autolock mode" 3 "Not Used" ;
VAL_ 1265 ICC_WiperID 0 "Not Active" 1 "Front Wiper" 2 "Rear Wiper" 3 "Both Wiper" ;
VAL_ 1265 ICC_MaintenanceMode 0 "Not Active" 1 "Exit" 2 "Entrance" 3 "Reserved" ;
VAL_ 1265 ICC_lockSetSwitchSts 0 "Not Active" 1 "OFF" 2 "Only Lighting" 3 "Sound and Lighting" ;
VAL_ 1265 ICC_ChildLockSW 0 "Not Active" 1 "Window" 2 "ChildLock_RL" 3 "ChildLock_RR" ;
VAL_ 1265 ICC_ParkUnlockEnable 0 "Not Active" 1 "Disable" 2 "Enable" 3 "Reserved" ;
VAL_ 1265 ICC_BLEOpenDriverDoorEnable 0 "No Request" 1 "Enable" 2 "Disable" 3 "Reserved" ;
VAL_ 1265 ICC_WinInhbSwt 0 "Not Active" 1 "Inhibit" 2 "Permit" 3 "Reserved" ;
VAL_ 1265 ICC_SteerWhlHeatgSwt 0 "Not Active" 1 "Level1" 2 "Level2" 3 "Level3" 4 "OFF" ;
VAL_ 1265 ICC_AutoHeatingset 0 "Not Active" 1 "ON" 2 "OFF" 3 "Reserved" ;
VAL_ 1265 ICC_FrontFogSw 0 "Not Active" 1 "ON" 2 "OFF" 3 "Reserved" ;
VAL_ 1265 ICC_RearFogSw 0 "Not Active" 1 "ON" 2 "OFF" 3 "Reserved" ;
VAL_ 1265 ICC_DoorControlSW 0 "Not Active" 1 "ON" 2 "OFF" 3 "Reserved" ;
VAL_ 1265 ICC_LockCarWinCloseSw 0 "Not Active" 1 "ON" 2 "OFF" 3 "Reserved" ;
VAL_ 1265 ICC_RainCarWinCloseSw 0 "Not Active" 1 "ON" 2 "OFF" 3 "Reserved" ;
VAL_ 1265 ICC_EasyEntryExitSet 0 "Not Active" 1 "ON" 2 "OFF" 3 "Not Used" ;
VAL_ 1265 ICC_NapTimeSet 0 "Not Active" ;
VAL_ 1265 ICC_NapAreaSet 0 "Not Active" 1 "Front Left" 2 "Front Right" 3 "Front Left and Right" ;
VAL_ 1265 ICC_NapStatusSet 0 "Not Active" 1 "ON" 2 "OFF" 3 "Not Used" ;
VAL_ 1265 ICC_NapCFSStatusSet 0 "Not Active" 1 "On" 2 "Off" 3 "Not Used" ;
VAL_ 1265 ICC_NapSetTemperature 31 "Not active" ;
VAL_ 1265 ICC_SpoilerWelcomeFunSet 0 "Not Active" 1 "ON" 2 "OFF" 3 "Reserved" ;
VAL_ 1265 ICC_SpoilerCtrlCmd 0 "Not Active" 1 "Auto" 2 "Open Level1" 3 "Open Level2" 4 "Close" 5 "Reserved" 6 "Reserved" 7 "Reserved" ;
VAL_ 1265 ICC_HazardLightReq 0 "Not Active" 1 "ON" 2 "OFF" 3 "Not Used" ;
VAL_ 1265 ICC_MusicStatus 0 "Not Active" 1 "ON" 2 "OFF" 3 "Not Used" ;
VAL_ 1265 ICC_CinemaStatus 0 "Not Active" 1 "ON" 2 "OFF" 3 "Not Used" ;
VAL_ 1137 ICC_BookChrgSetReq 0 "default" 1 "BookSet" 2 "CancellBook" 3 "Reserved" ;
VAL_ 1137 ICC_BkChrgCycleType 0 "default" 1 "Once" 2 "EveryDay" 3 "WorkDay" 4 "Reserved" 5 "Reserved" ;
VAL_ 1137 ICC_StopChrgReq 0 "Not Active" 1 "Active" ;
VAL_ 1137 ICC_BkChrgCycleMon 0 "Not active" 1 "Active" ;
VAL_ 1137 ICC_BkChrgCycleTues 0 "Not active" 1 "Active" ;
VAL_ 1137 ICC_BkChrgCycleWen 0 "Not active" 1 "Active" ;
VAL_ 1137 ICC_BkChrgCycleThur 0 "Not active" 1 "Active" ;
VAL_ 1137 ICC_BkChrgCycleFri 0 "Not active" 1 "Active" ;
VAL_ 1137 ICC_BkChrgCycleSat 0 "Not active" 1 "Active" ;
VAL_ 1137 ICC_BkChrgCycleSun 0 "Not active" 1 "Active" ;
VAL_ 1137 ICC_PetmodeFb 0 "Not active" 1 "ON" 2 "OFF" 3 "Invalid" ;
VAL_ 1137 ICC_SentinelModeSwitchSts 0 "Not active" 1 "ON" 2 "OFF" 3 "Reserved" ;
VAL_ 1137 ICC_SentinelModeWorkingSts 0 "Not Active" 1 "Active" 2 "LowSOC" 3 "HVNotReady" 4 "HVFault" 5 "MirrorUnFold" 6 "CameraFault" 7 "LowBatVolt" ;
VAL_ 1137 ICC_SentinelModeFaultSts 0 "Not Warming" 1 "Artificial occlusion" 2 "Rain and snow cover" 3 "Reserved" ;
VAL_ 1137 ICC_SentinelModeAlarmSts 0 "Not Alarm" 1 "Level 1" 2 "Level 2" 3 "Level 3" ;
VAL_ 1137 ICC_SentinelModeExitReason 0 "Normal" 1 "LowSOC" 2 "HVNotReady" 3 "HVFault" 4 "MirrorUnFold" 5 "CameraFault" 6 "LowBatVolt" ;
VAL_ 1137 ICC_PetModeWarn 0 "Not Active" 1 "High Voltage Battery Low" 2 "TMS Abnormal" 3 "High Pressure Abnormal" 4 "Low Voltage Battery Low" 5 "High Voltage Battery Less Than 15%" 6 "High Voltage Battery Less Than 12%" 7 "Time Long Warning" ;
VAL_ 1137 ICC_TBOXPetmodeReq 0 "Not Active" 1 "ON" 2 "OFF" 3 "Reserved" ;
VAL_ 1137 ICC_PetModeWarn_2 0 "Not Active" 1 "High Voltage Battery Low" 2 "TMS Abnormal" 3 "High Pressure Abnormal" 4 "Low Voltage Battery Low" 5 "High Voltage Battery Less Than 15%" 6 "High Voltage Battery Less Than 12%" 7 "Time Long Warning" 8 "Vehicle charging" 9 "Vehicle Disarming" 10 "Gear is non-p" ;
VAL_ 1137 ICM_FuelLevelFailSts 0 "Fail_Not_Present" 1 "Fail_Present" ;
VAL_ 1137 ICM_Maintenance_tips 0 "Tip_Not_Present" 1 "Tip_Present" ;
VAL_ 1144 ICC_HvBattKeepWarmSet 0 "Not active" 1 "active" ;
VAL_ 1144 ICC_EnergyRegSet 0 "Not active" ;
VAL_ 1144 ICC_HvBattKeepWarmActiveReq 0 "Not active" 1 "StartWarm" 2 "EndWarm" 3 "Not Used" ;
VAL_ 1210 ICC_FLSeatHeiCmd 0 "Not active" 1 "Move Forwardwarde" 2 "Move Bacwardkwarde" 3 "Reserved" ;
VAL_ 1210 ICC_FLSeatLvlCmd 0 "Not active" 1 "Move Forwardwarde" 2 "Move Bacwardkwarde" 3 "Reserved" ;
VAL_ 1210 ICC_FLSeatBackAgCmd 0 "Not active" 1 "Move Forwardwarde" 2 "Move Bacwardkwarde" 3 "Reserved" ;
VAL_ 1210 ICC_FLSeatCushCmd 0 "Not active" 1 "Move Forwardwarde" 2 "Move Bacwardkwarde" 3 "Reserved" ;
VAL_ 1210 ICC_FLSeatLegSpprtCmd 0 "Not active" 1 "Move Forwardwarde" 2 "Move Bacwardkwarde" 3 "Reserved" ;
VAL_ 1210 ICC_FRSeatHeiCmd 0 "Not active" 1 "Move Forwardwarde" 2 "Move Bacwardkwarde" 3 "Reserved" ;
VAL_ 1210 ICC_FRSeatLvlCmd 0 "Not active" 1 "Move Forwardwarde" 2 "Move Bacwardkwarde" 3 "Reserved" ;
VAL_ 1210 ICC_FRSeatBackAgCmd 0 "Not active" 1 "Move Forwardwarde" 2 "Move Bacwardkwarde" 3 "Reserved" ;
VAL_ 1210 ICC_FRSeatLegSpprtCmd 0 "Not active" 1 "Move Forwardwarde" 2 "Move Bacwardkwarde" 3 "Reserved" ;
VAL_ 1210 ICC_MemoryRecoveryCmd 0 "Not Active" 1 "Save" 2 "Recover Manual" 3 "RecoverAuto" ;
VAL_ 1210 ICC_DeleteFaceID 0 "Not active" 1 "ID1" 2 "ID2" 3 "ID3" 4 "ID4" 5 "ID5" 6 "Not Used" 7 "Not Used" ;
VAL_ 1210 ICC_FLSeatHeitargetCmd 0 "Not active" ;
VAL_ 1210 ICC_FLSeatLvltargetCmd 0 "Not active" ;
VAL_ 1210 ICC_FLSeatBackAgtargetCmd 0 "Not active" ;
VAL_ 1210 ICC_FLSeatCushtargetCmd 0 "Not active" ;
VAL_ 1210 ICC_FLSeatLegSpprttargetCmd 0 "Not active" ;
VAL_ 1210 ICC_FRSeatHeitargetCmd 0 "Not active" ;
VAL_ 1210 ICC_FRSeatLvltargetCmd 0 "Not active" ;
VAL_ 1210 ICC_FRSeatBackAgtargetCmd 0 "Not active" ;
VAL_ 1210 ICC_FRSeatLegSpprttargetCmd 0 "Not active" ;
VAL_ 1210 ICC_NapFLSeatBackAgtargetSet 0 "Not active" ;
VAL_ 1210 ICC_NapFRSeatBackAgtargetSet 0 "Not active" ;
VAL_ 1210 ICC_NapFLSeatLvltargetSet 0 "Not active" ;
VAL_ 1210 ICC_NapFRSeatLvltargetSet 0 "Not active" ;
VAL_ 1210 ICC_FRSeatLegRestAngleCmd 0 "Not Active" 1 "Move Forwardwarde" 2 "Move Bacwardkwarde" 3 "Reserved" ;
VAL_ 1210 ICC_FRSeatLegRestAngletargetCmd 0 "Not active" ;
VAL_ 1210 ICC_FRSeatCushCmd 0 "Not Active" 1 "Move Forwardwarde" 2 "Move Bacwardkwarde" 3 "Reserved" ;
VAL_ 1210 ICC_FRSeatCushtargetCmd 0 "Not Active" ;
VAL_ 1210 ICC_FRZeroGravitySeatSw 0 "Not Active" 1 "OFF" 2 "ON" 3 "Reserved" ;
VAL_ 1210 ICC_HomeLinkArmHornSet 0 "Not Active" 1 "ON" 2 "OFF" 3 "Not Used" ;
VAL_ 1210 ICC_HomeLinkWelLightSet 0 "Not Active" 1 "ON" 2 "OFF" 3 "Not Used" ;
VAL_ 1210 ICC_HomeLinkPositionSts 0 "Not Active" 1 "At home" 2 "Not at home" 3 "Reserved" ;
VAL_ 1210 ICC_WelcomeOpenSetCmd 0 "Not Active" 1 "ON" 2 "OFF" 3 "Not Used" ;
VAL_ 1210 ICC_WALOpenSetCmd 0 "Not Active" 1 "ON" 2 "OFF" 3 "Not Used" ;
VAL_ 1210 ICC_UIROpenSetCmd 0 "Not Active" 1 "ON" 2 "OFF" 3 "Not Used" ;
VAL_ 1210 ICC_EnjoyableSeatSwitch 0 "Not Active" 1 "Entrence" 2 "Exit" 3 "Pause" ;
VAL_ 1210 ICC_BLTKeyPESet 0 "Not Active" 1 "ON" 2 "OFF" 3 "Not Used" ;
VAL_ 1210 ICC_FRMemoryDeleteCmd 0 "Not Active" 1 "Delete" 2 "Not Used" 3 "Not Used" ;
VAL_ 1210 ICC_FLSitPosnlocation 0 "Not Active" 1 "Location1" 2 "Location2" 3 "Location3" ;
VAL_ 1210 ICC_FRSitPosnlocation 0 "Not Active" 1 "Location1" 2 "Location2" 3 "Location3" ;
VAL_ 1210 ICC_FREasyEntryExitSet 0 "Not Active" 1 "ON" 2 "OFF" 3 "Not Used" ;
VAL_ 1210 ICC_FRMemoryRecoveryCmd 0 "Not Active" 1 "Save" 2 "Recover Manual" 3 "RecoverAuto" ;
VAL_ 1210 ICC_ConsoleAdjustSwitch 0 "Not Active" 1 "Lock" 2 "Unlock" 3 "Forward(Reserved)" 4 "Backward(Reserved)" 5 "Delpoy" 6 "Retract" 7 "Middle" 8 "Stop" ;
VAL_ 1399 ICC_Conditiontype 0 "Default" 1 "Dynamics" 2 "CLTC" 3 "WLTC" ;
VAL_ 1238 ICC_CFSSwitch 0 "Not Active" 1 "ON" 2 "OFF" 3 "Not Used" ;
VAL_ 1238 ICC_CFSLevelSet 0 "Not Active" 1 "Level 1" 2 "Level 2" 3 "Level 3" 4 "Reserved" 5 "Reserved" 6 "Reserved" 7 "Reserved" ;
VAL_ 1238 ICC_CFSPosSet 0 "Not Active" 1 "Position One" 2 "Position Two" 3 "Position Three" ;
VAL_ 1238 ICC_PM25Switch 0 "Not Active" 1 "ON" 2 "OFF" 3 "Not Used" ;
VAL_ 1238 ICC_AQSSwitch 0 "Not Active" 1 "ON" 2 "OFF" 3 "Not Used" ;
VAL_ 1238 ICC_SecSetTemp_C 31 "Not Active" ;
VAL_ 1238 ICC_SecFaceKeySts 0 "Not Active" 1 "ON" 2 "OFF" 3 "Not Used" ;
VAL_ 1238 ICC_SecFootKeySts 0 "Not Active" 1 "ON" 2 "OFF" 3 "Not Used" ;
VAL_ 1238 ICC_SecBlowSpeedLevelKeySts 0 "Not Active" 1 "Level  1" 2 "Level  2" 3 "Level  3" 4 "Level  4" 5 "Level  5" 6 "Level  6" 7 "Level  7" 8 "Reserved" 9 "Reserved" 10 "Reserved" 11 "Reserved" 12 "Reserved" 13 "Reserved" 14 "Reserved" 15 "Reserved" ;
VAL_ 1238 ICC_SecAutoSwitch 0 "Not Active" 1 "ON" 2 "OFF" 3 "Not Used" ;
VAL_ 1238 ICC_SecCLMSwitch 0 "Not Active" 1 "ON" 2 "OFF" 3 "Not Used" ;
VAL_ 1238 ICC_ThrSetTemp_C 31 "Not Active" ;
VAL_ 1238 ICC_ThrFaceKeySts 0 "Not Active" 1 "ON" 2 "OFF" 3 "Not Used" ;
VAL_ 1238 ICC_ThrFootKeySts 0 "Not Active" 1 "ON" 2 "OFF" 3 "Not Used" ;
VAL_ 1238 ICC_ThrBlowSpeedLevelKeySts 0 "Not Active" 1 "Level  1" 2 "Level  2" 3 "Level  3" 4 "Level  4" 5 "Level  5" 6 "Level  6" 7 "Level  7" 8 "Level  0" 9 "Reserved" 10 "Reserved" 11 "Reserved" 12 "Reserved" 13 "Reserved" 14 "Reserved" 15 "Reserved" ;
VAL_ 1238 ICC_ThrAutoSwitch 0 "Not Active" 1 "ON" 2 "OFF" 3 "Not Used" ;
VAL_ 1238 ICC_ThrCLMSwitch 0 "Not Active" 1 "ON" 2 "OFF" 3 "Not Used" ;
VAL_ 1238 ICC_ThrACRequestKeySts 0 "Not Active" 1 "ON" 2 "OFF" 3 "Not used" ;
VAL_ 1238 ICC_DFMSwitch 0 "Not Active" 1 "ON" 2 "OFF" 3 "Not Used" ;
VAL_ 1289 ICC_TirePressureDisplayUnit 0 "Not Active" 1 "kPa" 2 "bar" 3 "psi" ;
VAL_ 1289 ICC_TireTemperatureDisplayUnit 0 "Not Active" 1 "°C" 2 "F" 3 "Reserved" ;
VAL_ 1289 ICC_ToggleUnits 0 "Not Active" 1 "Imperial" 2 "Metric" 3 "Reserved" ;
VAL_ 1289 ICC_BtConFlag 0 "invalid" 1 "bluetooth not found" 2 "PIN error" 3 "other anomalies" 4 "bluetooth connection successful" ;
VAL_ 1289 ICC_GPSSwitchSet 0 "Not Active" 1 "On" 2 "Off" 3 "Not Used" ;
VAL_ 1167 ICC_KeyDriveModememory 0 "Not Active" 1 "ON" 2 "OFF" 3 "Reserved" ;
VAL_ 1167 ICC_DriveModeSet 0 "Not Active" 1 "ECO" 2 "NORMAL" 3 "SPORT" 4 "SNOW" 5 "MUD" 6 "OffRoad" 7 "SAND" 8 "ROCK" 9 "EXPERT" 10 "X" 11 "WADE" 12 "UTURN" 13 "DRIFT" 14 "TOW" 15 "OffroadRace" 16 "Reserved" 17 "Reserved" 18 "Reserved" 19 "Reserved" 20 "Reserved" 21 "Reserved" 22 "Reserved" 23 "Reserved" 24 "Reserved" 25 "Reserved" 26 "Reserved" 27 "Reserved" 28 "Reserved" 29 "Reserved" 30 "Reserved" 31 "Reserved" ;
VAL_ 1167 ICC_DRIFTModeSetReq 0 "Not active" 1 "Entry Mode" 2 "Master mode" 3 "Expert mode" ;
VAL_ 1167 ICC_EXPERTEIPBESPSet 0 "Not Active" 1 "TCS_VDC_OFF" 2 "ALL_ON" 3 "ALL_OFF" ;
VAL_ 1167 ICC_EXPERTEcoSet 0 "Not Active" 1 "ON" 2 "OFF" 3 "Reserved" ;
VAL_ 1167 ICC_EXPERTNormSet 0 "NotActive" 1 "ON" 2 "OFF" 3 "Reserved" ;
VAL_ 1167 ICC_EXPERTSportSet 0 "Not Active" 1 "ON" 2 "OFF" 3 "Reserved" ;
VAL_ 1167 ICC_CrossaxisSet 0 "Not Active" 1 "ON" 2 "OFF" 3 "Reserved" ;
VAL_ 1167 ICC_EXPERTRWDSet 0 "Not Active" 1 "ON" 2 "OFF" 3 "Reserved" ;
VAL_ 1167 ICC_EXPERTAWDSet 0 "Not Active" 1 "ON" 2 "OFF" 3 "Reserved" ;
VAL_ 1167 ICC_EXPERTAutoSet 0 "Not Active" 1 "ON" 2 "OFF" 3 "Reserved" ;
VAL_ 1167 ICC_CLIMBSet 0 "Not Active" 1 "ON" 2 "OFF" 3 "Reserved" ;
VAL_ 1167 ICC_DriveModeExitSet 0 "Not Active" 1 "ON" 2 "OFF" 3 "Reserved" ;
VAL_ 1167 ICC_V2L_IntlDisChg 0 "Not Active" 1 "OFF" 2 "IntelV2L ON" 3 "Reserved" ;
VAL_ 1167 ICC_ExhibitionModeSwitch 0 "Not Active" 1 "ON" 2 "OFF" 3 "Reserved" ;
VAL_ 1167 ICC_TrailerMode 0 "Not Active" 1 "ON" 2 "OFF" 3 "Reserved" ;
VAL_ 1167 ICC_V2L_DisChgMem 0 "Not Active" 1 "Remember" 2 "No Remember" 3 "Reserved" ;
VAL_ 1167 ICC_DrivePowerDispSet 0 "Not Active" 1 "PercentDisp" 2 "kWDisp" 3 "Reserved" ;
VAL_ 1167 ICC_WLTC_to_CLTC_Mode 0 "Not Active" 1 "CLTC" 2 "WLTC" 3 "Reserved" ;
VAL_ 1167 ICC_StopChrgnSwitch 0 "Not Active" 1 "ON" 2 "OFF" 3 "Reserved" ;
VAL_ 1167 ICC_StopChrgnMode 0 "Not Active" 1 "Silence" 2 "Quick" 3 "Reserved" ;
VAL_ 1167 ICC_RegenerateLevelCtrl 0 "Not Active" 1 "Low" 2 "High" 3 "middle" 4 "SinglePedl" 5 "Reserved" 6 "Reserved" 7 "Reserved" ;
VAL_ 1167 ICC_SinglePedalMem 0 "Not Active" 1 "ON" 2 "OFF" 3 "Reserved" ;
VAL_ 1167 ICC_FuelDetnSwt 0 "Not Active" 1 "ON" 2 "OFF" 3 "Reserved" ;
VAL_ 1167 ICC_FuelDetnState 0 "Not Active" 1 "High Idle" 2 "Low Idle" 3 "Reserved" ;
VAL_ 1167 ICC_FuelDetnOpDefeated 0 "No Prompt" 1 "Prompt" ;
VAL_ 1167 ICC_HVDownRepairMode 0 "Not Active" 1 "ON" 2 "OFF" 3 "Reserved" ;
VAL_ 1167 ICC_UTURNSnowSet 0 "Not Active" 1 "ON" 2 "OFF" 3 "Reserved" ;
VAL_ 1167 ICC_UTURNSandSet 0 "Not Active" 1 "ON" 2 "OFF" 3 "Reserved" ;
VAL_ 1167 ICC_UTURNMudSet 0 "Not Active" 1 "ON" 2 "OFF" 3 "Reserved" ;
VAL_ 1167 ICC_UTURNGrassSet 0 "Not Active" 1 "ON" 2 "OFF" 3 "Reserved" ;
VAL_ 1167 ICC_LTCDispSet2 0 "Not Active" 1 "WLTC" 2 "CLTC" 3 "Reserved" ;
VAL_ 1167 ICC_SetSocManage 0 "NotActive" 1 "Default" 2 "SAVE" 3 "Auto" 4 "Charge" 5 "Reserved" 6 "Reserved" 7 "Reserved" ;
VAL_ 1326 ICC_DWDOnOff_Req 0 "Not Active" 1 "ON" 2 "OFF" 3 "Reserved" ;
VAL_ 1326 ICC_ContainerLightSet 0 "Not_Active" 1 "ON" 2 "OFF" 3 "reserved" ;
VAL_ 1331 ICC_RLSeatEasyEntryExitSet 0 "Not Active" 1 "ON" 2 "OFF" 3 "Not Used" ;
VAL_ 1331 ICC_RRSeatEasyEntryExitSet 0 "Not Active" 1 "ON" 2 "OFF" 3 "Not Used" ;
VAL_ 1331 ICC_RLMemoryRecoveryCmd 0 "Not Active" 1 "Save" 2 "Recover Manual" 3 "RecoverAuto" ;
VAL_ 1331 ICC_RRMemoryRecoveryCmd 0 "Not Active" 1 "Save" 2 "Recover Manual" 3 "RecoverAuto" ;
VAL_ 1331 ICC_RLSitPosnlocation 0 "Not Active" 1 "Location1" 2 "Location2" 3 "Location3" ;
VAL_ 1331 ICC_RRSitPosnlocation 0 "Not Active" 1 "Location1" 2 "Location2" 3 "Location3" ;
VAL_ 1331 ICC_CMSMDisplaySwitch 0 "Not active" 1 "ON" 2 "OFF" 3 "Reserved" ;
VAL_ 1331 ICC_CMSMDisplayAdjustmode 0 "Not active" 1 "NormalAngle" 2 "ViewAngle" 3 "Reserved" ;
VAL_ 1331 ICC_CMSMSetstandardSwitch 0 "Not active" 1 "ON" 2 "OFF" 3 "Reserved" ;
VAL_ 1331 ICC_LeftPedalControl 0 "Not active" 1 "Spread_LeftPedal" 2 "Retract_LeftPedal" 3 "Auto" ;
VAL_ 1331 ICC_RightPedalControl 0 "Not active" 1 "Spread_RightPedal" 2 "Retract_RightPedal" 3 "Auto" ;
VAL_ 1331 ICC_EPCEnable 0 "Not active" 1 "ON" 2 "OFF" 3 "Reserved" ;
VAL_ 1331 ICC_AMPKTVvoiceVolumeSet 0 "Not Active" 1 "0" 2 "1" 3 "2" 4 "3" 5 "4" 6 "5" 7 "6" 8 "7" 9 "8" 10 "9" 11 "10" 12 "11" 13 "12" 14 "13" 15 "14" 16 "15" 17 "16" 18 "17" 19 "18" 20 "19" 21 "20" 22 "21" 23 "22" 24 "23" 25 "24" 26 "25" 27 "26" 28 "27" 29 "28" 30 "29" 31 "30" 32 "31" 33 "Reserved" 34 "Reserved" 35 "Reserved" 36 "Reserved" 37 "Reserved" 38 "Reserved" 39 "Reserved" 40 "Reserved" 41 "Reserved" 42 "Reserved" 43 "Reserved" 44 "Reserved" 45 "Reserved" 46 "Reserved" 47 "Reserved" 48 "Reserved" 49 "Reserved" 50 "Reserved" 51 "Reserved" 52 "Reserved" 53 "Reserved" 54 "Reserved" 55 "Reserved" 56 "Reserved" 57 "Reserved" 58 "Reserved" 59 "Reserved" 60 "Reserved" 61 "Reserved" 62 "Reserved" 63 "Reserved" ;
VAL_ 1331 ICC_AMPA2BENCSoundReq 0 "Not Active" 1 "ON" 2 "OFF" 3 "Reserved" ;
VAL_ 1331 ICC_AMPENCVolumeSet 0 "Not Active" 1 "0" 2 "1" 3 "2" 4 "3" 5 "4" 6 "5" 7 "6" 8 "7" 9 "8" 10 "9" 11 "10" 12 "11" 13 "12" 14 "13" 15 "14" 16 "15" 17 "16" 18 "17" 19 "18" 20 "19" 21 "20" 22 "21" 23 "22" 24 "23" 25 "24" 26 "25" 27 "26" 28 "27" 29 "28" 30 "29" 31 "30" 32 "31" 33 "Reserved" 34 "Reserved" 35 "Reserved" 36 "Reserved" 37 "Reserved" 38 "Reserved" 39 "Reserved" 40 "Reserved" 41 "Reserved" 42 "Reserved" 43 "Reserved" 44 "Reserved" 45 "Reserved" 46 "Reserved" 47 "Reserved" 48 "Reserved" 49 "Reserved" 50 "Reserved" 51 "Reserved" 52 "Reserved" 53 "Reserved" 54 "Reserved" 55 "Reserved" 56 "Reserved" 57 "Reserved" 58 "Reserved" 59 "Reserved" 60 "Reserved" 61 "Reserved" 62 "Reserved" 63 "Reserved" ;
VAL_ 1331 ICC_AMPA2BChimeSoundReq 0 "Not Active" 1 "ON" 2 "OFF" 3 "Reserved" ;
VAL_ 1331 Set_AMPSoundFocus_2 0 "Not Active" 1 "Customized" 2 "All" 3 "Driver" 4 "Sleep" 5 "VIP" 6 "FrontRow" 7 "BackRow" ;
VAL_ 1331 ICC_AMPA2BKTVvoiceSoundReq 0 "Not Active" 1 "IESS OFF and KTV OFF（默认值)" 2 "IESS OFF and KTV ON" 3 "IESS ON and KTV OFF" 4 "IESS ON and KTV ON" ;
VAL_ 1331 ICC_MedStatusSet 0 "Not Active" 1 "ON" 2 "OFF" 3 "Not Used" ;
VAL_ 1331 Set_AMPLoudness 0 "Not Active" 1 "ON" 2 "OFF" 3 "Reserved" ;
VAL_ 1331 ICC_MedAreaSet 0 "Not Active" 1 "Front Left" 2 "Front Right" 3 "Front Left and Right" 4 "2Row Left" 5 "2Row Right" 6 "2Row Left and 2Row Right" 7 "Front Left and 2Row Right" 8 "Front Right and 2Row Left" 9 "Front Left and 2Row Left" 10 "Front Right and 2Row Right" ;
VAL_ 1331 ICC_LeftElectricPedalsSet 0 "Not active" 1 "Open" 2 "Close" 3 "Reserved" ;
VAL_ 1331 ICC_RightElectricPedalsSet 0 "Not active" 1 "Open" 2 "Close" 3 "Reserved" ;
VAL_ 1331 ICC_NapAreaSet2 0 "Not Active" 1 "2Row Left" 2 "2Row Right" 3 "2Row Left and Right" 4 "Front Left and 2Row Right" 5 "Front Right and 2Row Left" 6 "Front Left and 2Row Left" 7 "Front Right and 2Row Right" ;
VAL_ 1331 ICC_DisplayAdjustrAngReq 0 "Not active" ;
VAL_ 1331 Set_AMPKeyVolume 0 "Not Active" 1 "0" 2 "1" 3 "2" 4 "3" 5 "4" 6 "5" 7 "6" 8 "7" 9 "8" 10 "9" 11 "10" 12 "11" 13 "12" 14 "13" 15 "14" 16 "15" 17 "16" 18 "17" 19 "18" 20 "19" 21 "20" 22 "21" 23 "22" 24 "23" 25 "24" 26 "25" 27 "26" 28 "27" 29 "28" 30 "29" 31 "30" 32 "31" 33 "Reserved" 34 "Reserved" 35 "Reserved" 36 "Reserved" 37 "Reserved" 38 "Reserved" 39 "Reserved" 40 "Reserved" 41 "Reserved" 42 "Reserved" 43 "Reserved" 44 "Reserved" 45 "Reserved" 46 "Reserved" 47 "Reserved" 48 "Reserved" 49 "Reserved" 50 "Reserved" 51 "Reserved" 52 "Reserved" 53 "Reserved" 54 "Reserved" 55 "Reserved" 56 "Reserved" 57 "Reserved" 58 "Reserved" 59 "Reserved" 60 "Reserved" 61 "Reserved" 62 "Reserved" 63 "Reserved" ;
VAL_ 1331 Set_AMPExSoundmode 0 "Not Active" 1 "Soundmode1" 2 "Soundmode2" 3 "Soundmode3" 4 "OFF" 5 "Reserved" 6 "Reserved" 7 "Reserved" ;
VAL_ 1331 Set_AMPA2BENCSound 0 "Not Active" 1 "FL+FR+RL+SWF" 2 "FL+FR+SWF+RR" 3 "FL+FR+RL+RR" 4 "OFF" 5 "reserved" 6 "reserved" 7 "reserved" ;
VAL_ 1333 ICC_SRFCmd 0 "Not Active" 1 "Open" 2 "Close" 3 "Tilt" ;
VAL_ 1333 ICC_SRFPercentCmd 0 "Not Active" 1 "0" 2 "10%" 3 "20%" 4 "30%" 5 "40%" 6 "50%" 7 "60%" 8 "70%" 9 "80%" 10 "90%" 11 "100%" ;
VAL_ 1333 ICC_CSunshadeReq 0 "Not Active" 1 "Open" 2 "Close" 3 "Half_Open" ;
VAL_ 1333 ICC_CSunshadePercentReq 0 "Not Active" 1 "0%" 2 "10%" 3 "20%" 4 "30%" 5 "40%" 6 "50%" 7 "60%" 8 "70%" 9 "80%" 10 "90%" 11 "100%" ;
VAL_ 1333 ICC_SunshadeCmd 0 "Not Active" 1 "Open" 2 "Close" 3 "Half_Open" ;
VAL_ 1333 ICC_SunshadePercentCmd 0 "Not Active" 1 "0%" 2 "10%" 3 "20%" 4 "30%" 5 "40%" 6 "50%" 7 "60%" 8 "70%" 9 "80%" 10 "90%" 11 "100%" ;
VAL_ 1335 ICC_SET_EPS_SteerReturnRmdSts 0 "Not Active" 1 "ON" 2 "OFF" 3 "reserved" ;
VAL_ 1335 ICC_SET_MFSShake 0 "Not Active" 1 "ON" 2 "OFF" 3 "reserved" ;
VAL_ 1335 ICC_DMS_1_DistractionLevel 0 "Not Active" 1 "DISTRACTION_LEVEL_LIGHT" 2 "DISTRACTION_LEVEL_MEDIUM" 3 "DISTRACTION_LEVEL_HEAVY" 4 "Reserved" 5 "Reserved" 6 "Reserved" 7 "Reserved" ;
VAL_ 1335 ICC_SET_EPS_AsociWithDrvModSts 0 "Not_Active" 1 "ON" 2 "OFF" 3 "reserved" ;
VAL_ 1335 ICC_OverLoadWarnShieldSet 0 "Not Active" 1 "ON" 2 "OFF" 3 "reserved" ;
VAL_ 1335 ICC_BSWReq 0 "Not Active" 1 "ON" 2 "OFF" 3 "reserved" ;
VAL_ 1335 ICC_horizontalReq 0 "Not Active" 1 "ON" 2 "OFF" 3 "Not Used" ;
VAL_ 1337 ICC_SET_BT_ReduceWindSpeed 0 "Not_Active" 1 "ON" 2 "OFF" 3 "Reserved" ;
VAL_ 1337 ICC_SET_IPM_FirstBlowing 0 "Not Active" 1 "ON" 2 "OFF" 3 "Reserved" ;
VAL_ 1337 ICC_SET_IPM_BlowerDelay 0 "Not Active" 1 "ON" 2 "OFF" 3 "Reserved" ;
VAL_ 1337 ICC_SET_CirculationInTunnels 0 "Not Active" 1 "ON" 2 "OFF" 3 "Reserved" ;
VAL_ 1337 ICC_UVCLuminanceReq 0 "Not Active" 1 "high" 2 "lower" 3 "reserved" ;
VAL_ 1337 ICC_UVCControlReq 0 "Not Active" 1 "ON" 2 "OFF" 3 "AUTO" ;
VAL_ 1337 ICC_CrossCountryCoolingReq 0 "Not Active" 1 "ON" 2 "OFF" 3 "Reserved" ;
VAL_ 1337 ICC_KeepWarmReq 0 "Not Active" 1 "Open_AC" 2 "Open_NotAC" 3 "Closed" ;
VAL_ 1337 ICC_keepwarmSetTemperatureReq 0 "Not Active" 1 "Temperature 20°C" 2 "Temperature 25°C" 3 "Temperature 30°C" 4 "Temperature 35°C" 5 "Temperature 40°C" 6 "Temperature 45°C" 7 "Temperature 50°C" 8 "Temperature 55°C" 9 "Temperature 60°C" ;
VAL_ 1337 ICC_ParkingAirConditioning 0 "Not Active" 1 "Disable" 2 "AUTO" 3 "ventilate" ;
VAL_ 1337 ICC_CoolantFill_Req 0 "Not Active" 1 "ON" 2 "OFF" 3 "Reserved" ;
VAL_ 1337 ICC_FraganceLightoffReq 0 "No Active" 1 "FraganceLight_on" 2 "FraganceLight_off" 3 "Reserved" ;
VAL_ 1337 ICC_FraganceMemoffReq 0 "Not_Active" 1 "FraganceMem_on" 2 "FraganceMem_off" 3 "Reserved" ;
VAL_ 1337 ICC_AirPurgeReminderReq 0 "Not_Active" 1 "ON" 2 "OFF" 3 "Not_Used" ;
VAL_ 1337 ICC_CFSCycleLevel 0 "Not_Active" 1 "CFSCycle level1" 2 "CFSCycle level2" 3 "CFSCycle level3" 4 "CFSCycle level4" 5 "reserved" 6 "reserved" 7 "reserved" ;
VAL_ 1337 ICC_TimingLevel 0 "Not_Active" 1 "CFSTiming level1" 2 "CFSTiming level2" 3 "CFSTiming level3" 4 "CFSTiming level4" 5 "reserved" 6 "reserved" 7 "reserved" ;
VAL_ 1337 ICC_ModeAdjustDisplaySts 0 "BlowFace" 1 "BlowFaceAndBlowFoot" 2 "BlowFoot" 3 "BlowFootAndBlowWindow" 4 "BlowWindow" 5 "Not Active" 6 "BlowFaceAndBlowWindow" 7 "BlowFaceAndBlowFootAndBlowWindow" 8 "Auto" 9 "reserved" 10 "reserved" 11 "reserved" 12 "reserved" 13 "reserved" 14 "reserved" 15 "reserved" ;
VAL_ 1337 ICC_BiochemicalFuncReq 0 "Not Active" 1 "ON" 2 "OFF" 3 "Reserved" ;
VAL_ 1337 ICC_TimedVentilationReq 0 "Not Active" 1 "ON" 2 "OFF" 3 "Reserved" ;
VAL_ 1337 ICC_PetmodeSetTemperature_L_C 31 "Not active" ;
VAL_ 1337 ICC_PetModeSetTemperature_R_C 31 "Not active" ;
VAL_ 1337 ICC_PetModeSetCLMOn 0 "Not Active" 1 "On" 2 "Off" 3 "Not Used" ;
VAL_ 1337 ICC_PetModeSetAutoKeySts 0 "Not Active" 1 "On" 2 "Off" 3 "Not Used" ;
VAL_ 1337 ICC_PetModeSetCirculationSts 0 "Not Active" 1 "Recirculation mode" 2 "Air circulation mode" 3 "Two-Layer Flow Mode" ;
VAL_ 1318 ICC_SET_TDL_Rhythm_Switch 0 "Not_Active" 1 "ON" 2 "OFF" 3 "reserved" ;
VAL_ 1318 ICC_SET_TDL_Switch 0 "Not_Active" 1 "ON" 2 "OFF" 3 "reserved" ;
VAL_ 1318 ICC_SET_TDL_ColourModeAdj 0 "Not_Active" 1 "Monochrome" 2 "panchromatic" 3 "OFF" 4 "Reserved" 5 "Reserved" 6 "Reserved" 7 "Reserved" ;
VAL_ 1318 ICC_VoiceWake 0 "Not_Active" 1 "ON" 2 "OFF" 3 "LHFawaken" 4 "LHRawaken" 5 "RHFawaken" 6 "RHRawaken" 7 "Reserved" ;
VAL_ 1318 ICC_TDL_RhythmReq 0 "Not_Active" 1 "Mode1" 2 "Mode2" 3 "Mode3" 4 "Mode4" 5 "Mode5" 6 "Mode6" 7 "Reserved" ;
VAL_ 1318 ICC_SET_ApiluminanceAdj 0 "Not_Active" 1 "Level1" 2 "Level2" 3 "Level3" 4 "Level4" 5 "Level5" 6 "Level6" 7 "Level7" 8 "Level8" 9 "Reserved" 10 "Reserved" 11 "Reserved" 12 "Reserved" 13 "Reserved" 14 "Reserved" 15 "Reserved" ;
VAL_ 1318 ICC_SET_MusicLoudness_120HZ 0 "Not_Active" 1 "Level_1" 2 "Level_2" 3 "Level_3" 4 "Level_4" 5 "Level_5" 6 "Level_6" 7 "Level_7" 8 "Level_8" 9 "Level_9" 10 "Level_10" 11 "Level_11" 12 "Level_12" 13 "Level_13" 14 "Level_14" 15 "Level_15" ;
VAL_ 1318 ICC_SET_MusicLoudness_250HZ 0 "Not_Active" 1 "Level_1" 2 "Level_2" 3 "Level_3" 4 "Level_4" 5 "Level_5" 6 "Level_6" 7 "Level_7" 8 "Level_8" 9 "Level_9" 10 "Level_10" 11 "Level_11" 12 "Level_12" 13 "Level_13" 14 "Level_14" 15 "Level_15" ;
VAL_ 1318 ICC_SET_MusicLoudness_500HZ 0 "Not_Active" 1 "Level_1" 2 "Level_2" 3 "Level_3" 4 "Level_4" 5 "Level_5" 6 "Level_6" 7 "Level_7" 8 "Level_8" 9 "Level_9" 10 "Level_10" 11 "Level_11" 12 "Level_12" 13 "Level_13" 14 "Level_14" 15 "Level_15" ;
VAL_ 1318 ICC_SET_MusicLoudness_1000HZ 0 "Not_Active" 1 "Level_1" 2 "Level_2" 3 "Level_3" 4 "Level_4" 5 "Level_5" 6 "Level_6" 7 "Level_7" 8 "Level_8" 9 "Level_9" 10 "Level_10" 11 "Level_11" 12 "Level_12" 13 "Level_13" 14 "Level_14" 15 "Level_15" ;
VAL_ 1318 ICC_SET_MusicLoudness_1500HZ 0 "Not_Active" 1 "Level_1" 2 "Level_2" 3 "Level_3" 4 "Level_4" 5 "Level_5" 6 "Level_6" 7 "Level_7" 8 "Level_8" 9 "Level_9" 10 "Level_10" 11 "Level_11" 12 "Level_12" 13 "Level_13" 14 "Level_14" 15 "Level_15" ;
VAL_ 1318 ICC_SET_MusicLoudness_2000HZ 0 "Not_Active" 1 "Level_1" 2 "Level_2" 3 "Level_3" 4 "Level_4" 5 "Level_5" 6 "Level_6" 7 "Level_7" 8 "Level_8" 9 "Level_9" 10 "Level_10" 11 "Level_11" 12 "Level_12" 13 "Level_13" 14 "Level_14" 15 "Level_15" ;
VAL_ 1318 ICC_SET_MusicLoudness_6000HZ 0 "Not_Active" 1 "Level_1" 2 "Level_2" 3 "Level_3" 4 "Level_4" 5 "Level_5" 6 "Level_6" 7 "Level_7" 8 "Level_8" 9 "Level_9" 10 "Level_10" 11 "Level_11" 12 "Level_12" 13 "Level_13" 14 "Level_14" 15 "Level_15" ;
VAL_ 1318 ICC_TDL_FlowLightSw 0 "Not_Active" 1 "ON" 2 "OFF" 3 "reserved" ;
VAL_ 1318 ICC_TDL_FlowLightModeAdj 0 "Not Active" 1 "mode1" 2 "mode2" 3 "mode3" 4 "mode4" 5 "mode5" 6 "mode6" 7 "Reserved" ;
VAL_ 1320 ICC_Chb_Req 0 "Not Active" 1 "Chb_ON" 2 "Chb_OFF" 3 "reserved" ;
VAL_ 1320 ICC_ChbMem_Req 0 "Not Active" 1 "ChbMem_ON" 2 "ChbMem_OFF" 3 "reserved" ;
VAL_ 1320 ICC_ChbDelay_Req 0 "Not Active" 1 "ChbDelay_ON" 2 "ChbDelay_OFF" 3 "reserved" ;
VAL_ 1320 ICC_ChbSterilization_Req 0 "Not Active" 1 "Chbsterilize_ON" 2 "Chbsterilize_OFF" 3 "reserved" ;
VAL_ 1320 ICC_ChbItemsLeft_Req 0 "Not Active" 1 "Chbhanddown_ON" 2 "Chbhanddown_OFF" 3 "reserved" ;
VAL_ 1320 ICC_ParkingRadarSwSet 0 "Not active" 1 "ON" 2 "OFF" 3 "Reserved" ;
VAL_ 1320 ICC_ChbCoolset_Req 0 "Not_Active" 1 "ChbCoolset_-6" 2 "ChbCoolset_-5" 3 "ChbCoolset_-4" 4 "ChbCoolset_-3" 5 "ChbCoolset_-2" 6 "ChbCoolset_-1" 7 "ChbCoolset_0" 8 "ChbCoolset_1" 9 "ChbCoolset_2" 10 "ChbCoolset_3" 11 "ChbCoolset_4" 12 "ChbCoolset_5" 13 "ChbCoolset_6" 14 "ChbCoolset_-18" 15 "ChbCoolset_-17" 16 "ChbCoolset_-16" 17 "ChbCoolset_-15" 18 "ChbCoolset_-14" 19 "ChbCoolset_-13" 20 "ChbCoolset_-12" 21 "ChbCoolset_-11" 22 "ChbCoolset_-10" 23 "ChbCoolset_-9" 24 "ChbCoolset_-8" 25 "ChbCoolset_-7" 26 "Reserved" 27 "Reserved" 28 "Reserved" 29 "Reserved" 30 "Reserved" 31 "Reserved" ;
VAL_ 1320 ICC_ChbCoolorheat_Req 0 "NotActive" 1 "ChbCool_on" 2 "ChbHeat_on" 3 "Close" 4 "ColdDrinkMode" 5 "IceCreamMode" 6 "WarmMilkMode" 7 "WarmDrinkMode" ;
VAL_ 1320 ICC_ChbHeatset_Req 0 "Not Active" 1 "ChbHeatset_35" 2 "ChbHeatset_36" 3 "ChbHeatset_37" 4 "ChbHeatset_38" 5 "ChbHeatset_39" 6 "ChbHeatset_40" 7 "ChbHeatset_41" 8 "ChbHeatset_42" 9 "ChbHeatset_43" 10 "ChbHeatset_44" 11 "ChbHeatset_45" 12 "ChbHeatset_46" 13 "ChbHeatset_47" 14 "ChbHeatset_48" 15 "ChbHeatset_49" 16 "ChbHeatset_50" ;
VAL_ 1360 ICC_XDriveMode 0 "Not Active" 1 "unidentifiable" 2 "Normal" 3 "SNOW" 4 "MUD" 5 "ROCK" 6 "SAND" 7 "WATERSURFACE" 8 "Normal" 9 "SNOW" 10 "MUD" 11 "ROCK" 12 "SAND" 13 "WATERSURFACE" 14 "Normal" 15 "SNOW" 16 "MUD" 17 "ROCK" 18 "SAND" 19 "Reserved" 20 "Reserved" 21 "Reserved" 22 "Reserved" 23 "Reserved" 24 "Reserved" 25 "Reserved" 26 "Reserved" 27 "Reserved" 28 "Reserved" 29 "Reserved" 30 "Reserved" 31 "Reserved" ;
VAL_ 1360 ICC_LISD_DisplaySwitch 0 "Default value" 1 "Display ON" 2 "Display OFF" 3 "Reserved" ;
VAL_ 1360 ICC_LISD_ParkingShowCMD 0 "Default value" 1 "ON" 2 "OFF" 3 "Reserved" ;
VAL_ 1360 ICC_RoofCampLampSetL 0 "Not_Active" 1 "ON" 2 "OFF" 3 "reserved" ;
VAL_ 1360 ICC_RISD_DisplaySwitch 0 "Default value" 1 "Display ON" 2 "Display OFF" 3 "Reserved" ;
VAL_ 1360 ICC_RISD_ParkingShowCMD 0 "Default value" 1 "ON" 2 "OFF" 3 "Reserved" ;
VAL_ 1360 ICC_RoofCampLampSetR 0 "Not_Active" 1 "ON" 2 "OFF" 3 "reserved" ;
VAL_ 1360 ICC_LogoParkingReq 0 "Not Active" 1 "ON" 2 "OFF" 3 "Reserved" ;
VAL_ 1360 ICC_LogoChargingReq 0 "Not Active" 1 "ON" 2 "OFF" 3 "Reserved" ;
VAL_ 1360 ICC_DRLSw 0 "Not active" 1 "ON" 2 "OFF" 3 "Reserved" ;
VAL_ 1360 ICC_TopLightSet 0 "Not_Active" 1 "ON" 2 "OFF" 3 "reserved" ;
VAL_ 1360 ICC_APillarYellowAmbientSet 0 "Not_Active" 1 "ON" 2 "OFF" 3 "reserved" ;
VAL_ 1360 ICC_APillarWhiteAmbientSet 0 "Not_Active" 1 "ON" 2 "OFF" 3 "reserved" ;
VAL_ 1360 ICC_LISD_ParkingShowMod 0 "Default value" 1 "Mode1" 2 "Mode2" 3 "Mode3" 4 "Mode4" 5 "Reserved" 6 "Reserved" 7 "Reserved" 8 "Reserved" 9 "Reserved" 10 "Reserved" 11 "Reserved" 12 "Reserved" 13 "Reserved" 14 "Reserved" 15 "Reserved" ;
VAL_ 1360 ICC_RISD_ParkingShowMod 0 "Default value" 1 "Mode1" 2 "Mode2" 3 "Mode3" 4 "Mode4" 5 "Reserved" 6 "Reserved" 7 "Reserved" 8 "Reserved" 9 "Reserved" 10 "Reserved" 11 "Reserved" 12 "Reserved" 13 "Reserved" 14 "Reserved" 15 "Reserved" ;
VAL_ 1360 ICC_APillarSpotLampSet 0 "Not_Active" 1 "ON" 2 "OFF" 3 "reserved" ;
VAL_ 1360 ICC_PenetrationLampSetF 0 "Not_Active" 1 "ON" 2 "OFF" 3 "reserved" ;
VAL_ 1360 ICC_MusicLampShowSW 0 "Not active" 1 "OFF" 2 "ON" 3 "Reserved" ;
VAL_ 1360 ICC_LogoColorReq 0 "Not_Active" ;
SIG_GROUP_ 1150 ICC_BD_11_0x47E_E2E_P01_1 1 : Fusa_47E_1 Fusa_47E_2 Fusa_47E_3 ICC_BD_11_CRC ICC_BD_11_RollgCntr ICC_CPDDelaySwitchSet ICC_PPMIDBSRBPASet ICC_PPMIDHwSet ICC_DriveDrosinessLevel ICC_FLDoorButton ICC_FRDoorButton ICC_RRDoorButton ICC_RLDoorButton ICC_CloseAllDoors ICC_DoorRemoteKeyControlEnable ICC_SetOpenAngle ICC_CPDSwitchSet ICC_FrontDoorPowerMode ICC_RearDoorPowerMode ICC_PedalCloseDriverDoorEnable RR_Door_RearScreen_Control ICC_RearDoorVoiceControlEnable ICC_FLVoiceControl ICC_FRVoiceControl ICC_RRVoiceControl ICC_RLVoiceControl RL_Door_RearScreen_Control;
SIG_GROUP_ 1157 ICC_DA_15_0x485_E2E_P01_1 1 : Fusa_485_1 Fusa_485_2 ICC_DA_15_CRC ICC_DA_15_RollgCntr ICC_DA_15_Resd ICC_DA_15_BSDLCWSettingSt ICC_DA_15_DOWSettingSt ICC_DA_15_RCWSettingSt ICC_DA_15_RCTARCTBWarnType ICC_DA_15_FCTAFCTBWarnType ICC_DA_15_FrontPDCMuteSet ICC_DA_15_FKPMuteSet ICC_DA_15_ExtremeEnergySaveMode Driver_EyeOnRoad Dms_Status Driver_AbnormalBehavior Driver_GazeRegion Dms_DriverPresence ICC_IHCfunctionSw;
SIG_GROUP_ 1335 New_Signal_Group_537 1 : New_Signal_537_1 New_Signal_537_2 New_Signal_537_3 ICC_horizontalReq ICC_BSWReq ICC_OverLoadWarnShieldSet ICC_SET_EPS_AsociWithDrvModSts ICC_DMS_1_DistractionLevel ICC_SET_MFSShake ICC_SET_EPS_SteerReturnRmdSts ICC_RolloverSetCmd;
